VERSION "ae3c"

NS_ :

BS_:

BU_: Brightloop_Can_Loader ECU HVHV DCDC

BO_ 2147487814 BL3_Node6GlobalValue: 7 HVHV
 SG_ NCellOtpErrorFlags m0 : 48|8@1+ (1,0) [0|255] ""  ECU
 SG_ TCell3N2 m1 : 48|8@1+ (1,-40) [-40|215] "°C"  ECU
 SG_ VAuxCell4N2 m9 : 48|8@1+ (0.15,0) [0|38.25] "V"  ECU
 SG_ TCell3N1 m1 : 40|8@1+ (1,-40) [-40|215] "°C"  ECU
 SG_ TInternal m3 : 40|8@1+ (1,-40) [-40|215] "°C"  ECU
 SG_ NBootloaderId m4 : 40|16@1+ (1,0) [0|65535] ""  ECU
 SG_ NApplicationId m5 : 40|16@1+ (1,0) [0|65535] ""  ECU
 SG_ VAuxCell3N2 m9 : 40|8@1+ (0.15,0) [0|38.25] "V"  ECU
 SG_ NSyncNodeCount m0 : 39|5@1+ (1,0) [0|31] ""  ECU
 SG_ NSyncNodeRank m0 : 34|5@1+ (1,0) [0|31] ""  ECU
 SG_ NReleaseMode m0 : 32|2@1+ (1,0) [0|3] ""  ECU
 SG_ TCell2N2 m1 : 32|8@1+ (1,-40) [-40|215] "°C"  ECU
 SG_ NCellVAuxErrorFlags m7 : 32|8@1+ (1,0) [0|65535] ""  ECU
 SG_ VAuxCell4N1 m8 : 32|8@1+ (0.15,0) [0|38.25] "V"  ECU
 SG_ VAuxCell2N2 m9 : 32|8@1+ (0.15,0) [0|38.25] "V"  ECU
 SG_ VAuxCell4N3 m10 : 32|8@1+ (0.15,0) [0|38.25] "V"  ECU
 SG_ TCell4N3 m11 : 32|8@1+ (1,-40) [-40|215] "°C"  ECU
 SG_ VAux3Measured m0 : 24|8@1+ (0.01,0) [0|2.55] "V"  ECU
 SG_ TCell2N1 m1 : 24|8@1+ (1,-40) [-40|215] "°C"  ECU
 SG_ NConfigCrc m4 : 24|16@1+ (1,0) [0|65535] ""  ECU
 SG_ NSettingsCrc m5 : 24|16@1+ (1,0) [0|65535] ""  ECU
 SG_ NSerial m6 : 24|32@1+ (1,0) [0|4294967295] ""  ECU
 SG_ VAuxCell3N1 m8 : 24|8@1+ (0.15,0) [0|38.25] "V"  ECU
 SG_ VAuxCell1N2 m9 : 24|8@1+ (0.15,0) [0|38.25] "V"  ECU
 SG_ VAuxCell3N3 m10 : 24|8@1+ (0.15,0) [0|38.25] "V"  ECU
 SG_ TCell3N3 m11 : 24|8@1+ (1,-40) [-40|215] "°C"  ECU
 SG_ VAux2Measured m0 : 16|8@1+ (0.02,0) [0|5.1] "V"  ECU
 SG_ TCell1N2 m1 : 16|8@1+ (1,-40) [-40|215] "°C"  ECU
 SG_ TCell4N2 m2 : 16|8@1+ (1,-40) [-40|215] "°C"  ECU
 SG_ NCellXcpErrorFlags m7 : 16|16@1+ (1,0) [0|65535] ""  ECU
 SG_ VAuxCell2N1 m8 : 16|8@1+ (0.15,0) [0|38.25] "V"  ECU
 SG_ VAuxCell2N3 m10 : 16|8@1+ (0.15,0) [0|38.25] "V"  ECU
 SG_ TCell2N3 m11 : 16|8@1+ (1,-40) [-40|215] "°C"  ECU
 SG_ VAux1Measured m0 : 8|8@1+ (0.15,0) [0|38.25] "V"  ECU
 SG_ TCell1N1 m1 : 8|8@1+ (1,-40) [-40|215] "°C"  ECU
 SG_ TCell4N1 m2 : 8|8@1+ (1,-40) [-40|215] "°C"  ECU
 SG_ NConfigVersion m4 : 8|16@1+ (1,0) [0|65535] ""  ECU
 SG_ NSettingsVersion m5 : 8|16@1+ (1,0) [0|65535] ""  ECU
 SG_ NChecksum m6 : 8|16@1+ (1,0) [0|65535] ""  ECU
 SG_ NCellSwOcpErrorFlags m7 : 8|8@1+ (1,0) [0|255] ""  ECU
 SG_ VAuxCell1N1 m8 : 8|8@1+ (0.15,0) [0|38.25] "V"  ECU
 SG_ VAuxCell1N3 m10 : 8|8@1+ (0.15,0) [0|38.25] "V"  ECU
 SG_ TCell1N3 m11 : 8|8@1+ (1,-40) [-40|215] "°C"  ECU
 SG_ NMultiplexer M : 0|8@1+ (1,0) [0|255] ""  ECU

BO_ 2147487750 BL3_Node6Status: 8 HVHV
 SG_ BPath1AcModeActivated m0 : 63|1@1+ (1,0) [0|1] ""  ECU
 SG_ BPath1AcUfpError m0 : 62|1@1+ (1,0) [0|1] ""  ECU
 SG_ BPath1AcOfpError m0 : 61|1@1+ (1,0) [0|1] ""  ECU
 SG_ NPath1AcFunctionMode m0 : 58|3@1+ (1,0) [0|7] ""  ECU
 SG_ BPath1FlgCapaError m0 : 57|1@1+ (1,0) [0|1] ""  ECU
 SG_ BPath2FlgCapaError m1 : 57|1@1+ (1,0) [0|1] ""  ECU
 SG_ BPath1ErrVAuxCell m0 : 56|1@1+ (1,0) [0|1] ""  ECU
 SG_ BPath2ErrVAuxCell m1 : 56|1@1+ (1,0) [0|1] ""  ECU
 SG_ IPath1Unbalance m0 : 48|8@1+ (0.25,0) [0|63.75] "A"  ECU
 SG_ IPath2Unbalance m1 : 48|8@1+ (0.25,0) [0|63.75] "A"  ECU
 SG_ BPath1RcpWarning m0 : 47|1@1+ (1,0) [0|1] ""  ECU
 SG_ BPath2RcpWarning m1 : 47|1@1+ (1,0) [0|1] ""  ECU
 SG_ BPath1OcpError m0 : 46|1@1+ (1,0) [0|1] ""  ECU
 SG_ BPath2OcpError m1 : 46|1@1+ (1,0) [0|1] ""  ECU
 SG_ BPath1OtpError m0 : 45|1@1+ (1,0) [0|1] ""  ECU
 SG_ BPath2OtpError m1 : 45|1@1+ (1,0) [0|1] ""  ECU
 SG_ BPath1SideBUvpError m0 : 44|1@1+ (1,0) [0|1] ""  ECU
 SG_ BPath2SideBUvpError m1 : 44|1@1+ (1,0) [0|1] ""  ECU
 SG_ BPath1SideAUvpError m0 : 43|1@1+ (1,0) [0|1] ""  ECU
 SG_ BPath2SideAUvpError m1 : 43|1@1+ (1,0) [0|1] ""  ECU
 SG_ BPath1SideBOvpError m0 : 42|1@1+ (1,0) [0|1] ""  ECU
 SG_ BPath2SideBOvpError m1 : 42|1@1+ (1,0) [0|1] ""  ECU
 SG_ BPath1SideAOvpError m0 : 41|1@1+ (1,0) [0|1] ""  ECU
 SG_ BPath2SideAOvpError m1 : 41|1@1+ (1,0) [0|1] ""  ECU
 SG_ BPath1Requested m0 : 40|1@1+ (1,0) [0|1] ""  ECU
 SG_ BPath2Requested m1 : 40|1@1+ (1,0) [0|1] ""  ECU
 SG_ NPath1CurrentSideSelected m0 : 38|2@1+ (1,0) [0|3] ""  ECU
 SG_ NPath2CurrentSideSelected m1 : 38|2@1+ (1,0) [0|3] ""  ECU
 SG_ NPath1VoltageSideSelected m0 : 36|2@1+ (1,0) [0|3] ""  ECU
 SG_ NPath2VoltageSideSelected m1 : 36|2@1+ (1,0) [0|3] ""  ECU
 SG_ NPath1State m0 : 32|4@1+ (1,0) [0|15] ""  ECU
 SG_ NPath2State m1 : 32|4@1+ (1,0) [0|15] ""  ECU
 SG_ NMultiplexer M : 29|3@1+ (1,0) [0|7] ""  ECU
 SG_ BXcpError : 28|1@1+ (1,0) [0|1] ""  ECU
 SG_ NCellHwErrorFlags : 20|8@1+ (1,0) [0|255] ""  ECU
 SG_ BSyncInputSignal : 18|1@1+ (1,0) [0|0] ""  ECU
 SG_ BSyncRequested : 17|1@1+ (1,0) [0|0] ""  ECU
 SG_ BInternalTemperatureError : 16|1@1+ (1,0) [0|1] ""  ECU
 SG_ BConfigSettingsError : 15|1@1+ (1,0) [0|1] ""  ECU
 SG_ BAuxSupplyError : 14|1@1+ (1,0) [0|1] ""  ECU
 SG_ BCanTimeoutError : 13|1@1+ (1,0) [0|1] ""  ECU
 SG_ BAuxIsoEnabled : 12|1@1+ (1,0) [0|1] ""  ECU
 SG_ BSafetyDischargeEnabled : 11|1@1+ (1,0) [0|1] ""  ECU
 SG_ BFaultSignal : 10|1@1+ (1,0) [0|1] ""  ECU
 SG_ BEnableSignal : 9|1@1+ (1,0) [0|1] ""  ECU
 SG_ BSafetyDischargeStatus : 8|1@1+ (1,0) [0|1] ""  ECU
 SG_ BSyncStatus : 7|1@1+ (1,0) [0|1] ""  ECU
 SG_ BReadConfigAndSettingsRequested : 6|1@1+ (1,0) [0|1] ""  ECU
 SG_ BSwResetModuleRequested : 5|1@1+ (1,0) [0|1] ""  ECU
 SG_ BSafetyDischargeRequested : 4|1@1+ (1,0) [0|1] ""  ECU
 SG_ NModuleState : 0|4@1+ (1,0) [0|15] ""  ECU

BO_ 2147487753 BL4_Node9Status: 8 HVHV
 SG_ BPath1AcModeActivated m0 : 63|1@1+ (1,0) [0|1] ""  ECU
 SG_ BPath1AcUfpError m0 : 62|1@1+ (1,0) [0|1] ""  ECU
 SG_ BPath1AcOfpError m0 : 61|1@1+ (1,0) [0|1] ""  ECU
 SG_ NPath1AcFunctionMode m0 : 58|3@1+ (1,0) [0|7] ""  ECU
 SG_ BPath1FlgCapaError m0 : 57|1@1+ (1,0) [0|1] ""  ECU
 SG_ BPath2FlgCapaError m1 : 57|1@1+ (1,0) [0|1] ""  ECU
 SG_ BPath1ErrVAuxCell m0 : 56|1@1+ (1,0) [0|1] ""  ECU
 SG_ BPath2ErrVAuxCell m1 : 56|1@1+ (1,0) [0|1] ""  ECU
 SG_ IPath1Unbalance m0 : 48|8@1+ (0.25,0) [0|63.75] "A"  ECU
 SG_ IPath2Unbalance m1 : 48|8@1+ (0.25,0) [0|63.75] "A"  ECU
 SG_ BPath1RcpWarning m0 : 47|1@1+ (1,0) [0|1] ""  ECU
 SG_ BPath2RcpWarning m1 : 47|1@1+ (1,0) [0|1] ""  ECU
 SG_ BPath1OcpError m0 : 46|1@1+ (1,0) [0|1] ""  ECU
 SG_ BPath2OcpError m1 : 46|1@1+ (1,0) [0|1] ""  ECU
 SG_ BPath1OtpError m0 : 45|1@1+ (1,0) [0|1] ""  ECU
 SG_ BPath2OtpError m1 : 45|1@1+ (1,0) [0|1] ""  ECU
 SG_ BPath1SideBUvpError m0 : 44|1@1+ (1,0) [0|1] ""  ECU
 SG_ BPath2SideBUvpError m1 : 44|1@1+ (1,0) [0|1] ""  ECU
 SG_ BPath1SideAUvpError m0 : 43|1@1+ (1,0) [0|1] ""  ECU
 SG_ BPath2SideAUvpError m1 : 43|1@1+ (1,0) [0|1] ""  ECU
 SG_ BPath1SideBOvpError m0 : 42|1@1+ (1,0) [0|1] ""  ECU
 SG_ BPath2SideBOvpError m1 : 42|1@1+ (1,0) [0|1] ""  ECU
 SG_ BPath1SideAOvpError m0 : 41|1@1+ (1,0) [0|1] ""  ECU
 SG_ BPath2SideAOvpError m1 : 41|1@1+ (1,0) [0|1] ""  ECU
 SG_ BPath1Requested m0 : 40|1@1+ (1,0) [0|1] ""  ECU
 SG_ BPath2Requested m1 : 40|1@1+ (1,0) [0|1] ""  ECU
 SG_ NPath1CurrentSideSelected m0 : 38|2@1+ (1,0) [0|3] ""  ECU
 SG_ NPath2CurrentSideSelected m1 : 38|2@1+ (1,0) [0|3] ""  ECU
 SG_ NPath1VoltageSideSelected m0 : 36|2@1+ (1,0) [0|3] ""  ECU
 SG_ NPath2VoltageSideSelected m1 : 36|2@1+ (1,0) [0|3] ""  ECU
 SG_ NPath1State m0 : 32|4@1+ (1,0) [0|15] ""  ECU
 SG_ NPath2State m1 : 32|4@1+ (1,0) [0|15] ""  ECU
 SG_ NMultiplexer M : 29|3@1+ (1,0) [0|7] ""  ECU
 SG_ BXcpError : 28|1@1+ (1,0) [0|1] ""  ECU
 SG_ NCellHwErrorFlags : 20|8@1+ (1,0) [0|255] ""  ECU
 SG_ BSyncInputSignal : 18|1@1+ (1,0) [0|0] ""  ECU
 SG_ BSyncRequested : 17|1@1+ (1,0) [0|0] ""  ECU
 SG_ BInternalTemperatureError : 16|1@1+ (1,0) [0|1] ""  ECU
 SG_ BConfigSettingsError : 15|1@1+ (1,0) [0|1] ""  ECU
 SG_ BAuxSupplyError : 14|1@1+ (1,0) [0|1] ""  ECU
 SG_ BCanTimeoutError : 13|1@1+ (1,0) [0|1] ""  ECU
 SG_ BAuxIsoEnabled : 12|1@1+ (1,0) [0|1] ""  ECU
 SG_ BSafetyDischargeEnabled : 11|1@1+ (1,0) [0|1] ""  ECU
 SG_ BFaultSignal : 10|1@1+ (1,0) [0|1] ""  ECU
 SG_ BEnableSignal : 9|1@1+ (1,0) [0|1] ""  ECU
 SG_ BSafetyDischargeStatus : 8|1@1+ (1,0) [0|1] ""  ECU
 SG_ BSyncStatus : 7|1@1+ (1,0) [0|1] ""  ECU
 SG_ BReadConfigAndSettingsRequested : 6|1@1+ (1,0) [0|1] ""  ECU
 SG_ BSwResetModuleRequested : 5|1@1+ (1,0) [0|1] ""  ECU
 SG_ BSafetyDischargeRequested : 4|1@1+ (1,0) [0|1] ""  ECU
 SG_ NModuleState : 0|4@1+ (1,0) [0|15] ""  ECU

BO_ 2147489417 BL4_Node9Setpoints2Value: 6 HVHV
 SG_ IqPath1AcLimitLo m9 : 38|10@1+ (0.5,-256) [-256|255.5] "A"  ECU
 SG_ IqPath1AcLimitHi m9 : 28|10@1+ (0.5,-256) [-256|255.5] "A"  ECU
 SG_ PPath2LimitLo m2 : 24|16@1+ (100,-3000000) [-3000000|3553500] "W"  ECU
 SG_ IqPath1AcSetpoint m13 : 18|10@1+ (0.5,-256) [-256|255.5] "A"  ECU
 SG_ IdPath1AcLimitLo m9 : 18|10@1+ (0.5,-256) [-256|255.5] "A"  ECU
 SG_ IdPath1AcSetpoint m13 : 8|10@1+ (0.5,-256) [-256|255.5] "A"  ECU
 SG_ IdPath1AcLimitHi m9 : 8|10@1+ (0.5,-256) [-256|255.5] "A"  ECU
 SG_ PPath2LimitHi m2 : 8|16@1+ (100,-3000000) [-3000000|3553500] "W"  ECU
 SG_ NMultiplexer M : 0|5@1+ (1,0) [0|31] ""  ECU

BO_ 2147489353 BL4_Node9Setpoints1Value: 7 HVHV
 SG_ NPath1AcFunctionMode m9 : 50|3@1+ (1,0) [0|7] ""  ECU
 SG_ NPath2CurrentSideSelected m2 : 42|2@1+ (1,0) [0|3] ""  ECU
 SG_ NPath2VoltageSideSelected m2 : 40|2@1+ (1,0) [0|3] ""  ECU
 SG_ NPath1AcFrequencySetpoint m9 : 38|12@1+ (0.25,0) [0|1023.75] "Hz"  ECU
 SG_ IPath2LimitLo m2 : 28|12@1+ (0.5,-1000) [-1000|1047.5] "A"  ECU
 SG_ VqPath1AcSetpoint m9 : 27|11@1+ (1,-1024) [-1024|1023] "V"  ECU
 SG_ VdPath1AcSetpoint m9 : 16|11@1+ (1,-1024) [-1024|1023] "V"  ECU
 SG_ IPath2LimitHi m2 : 16|12@1+ (0.5,-1000) [-1000|1047.5] "A"  ECU
 SG_ VDcPath1AcSetpoint m9 : 4|12@1+ (1,0) [0|4095] "V"  ECU
 SG_ VPath2Setpoint m2 : 4|12@1+ (1,0) [0|4095] "V"  ECU
 SG_ NMultiplexer M : 0|4@1+ (1,0) [0|15] ""  ECU

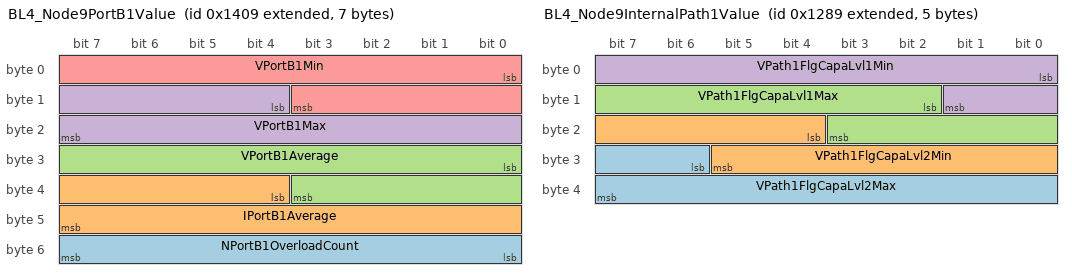
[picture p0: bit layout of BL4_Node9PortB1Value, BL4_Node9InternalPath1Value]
BO_ 2147488777 BL4_Node9PortB1Value: 7 HVHV
 SG_ NPortB1OverloadCount : 48|8@1+ (1,0) [0|255] ""  ECU
 SG_ IPortB1Average : 36|12@1+ (0.25,-500) [-500|523.75] "A"  ECU
 SG_ VPortB1Average : 24|12@1+ (1,0) [0|4095] "V"  ECU
 SG_ VPortB1Max : 12|12@1+ (1,0) [0|4095] "V"  ECU
 SG_ VPortB1Min : 0|12@1+ (1,0) [0|4095] "V"  ECU

BO_ 2147487881 BL4_Node9PortA1Value: 8 HVHV
 SG_ NMultiplexer M : 56|8@1+ (1,0) [0|255] ""  ECU
 SG_ IqPhAPortA1RMS m3 : 42|12@1+ (0.125,-256) [-256|255.875] "A"  ECU
 SG_ IqPortA1RMS m1 : 36|12@1+ (0.125,-256) [-256|255.875] "A"  ECU
 SG_ NFrequencyPortA1 m2 : 36|16@1+ (0.0125,0) [0|819.1875] "Hz"  ECU
 SG_ IqPhCPortA1RMS m4 : 36|12@1+ (0.125,-256) [-256|255.875] "A"  ECU
 SG_ IdPhAPortA1RMS m3 : 30|12@1+ (0.125,-256) [-256|255.875] "A"  ECU
 SG_ IdPortA1RMS m1 : 24|12@1+ (0.125,-256) [-256|255.875] "A"  ECU
 SG_ VphCPortA1Peak m2 : 24|12@1+ (0.5,0) [0|2047.5] "V"  ECU
 SG_ IdPhCPortA1RMS m4 : 24|12@1+ (0.125,-256) [-256|255.875] "A"  ECU
 SG_ IphCPortA1Peak m3 : 20|10@1+ (0.25,0) [0|255.75] "A"  ECU
 SG_ VqPortA1RMS m1 : 12|12@1+ (0.5,-1024) [-1024|1023.5] "V"  ECU
 SG_ VphBPortA1Peak m2 : 12|12@1+ (0.5,0) [0|2047.5] "V"  ECU
 SG_ IqPhBPortA1RMS m4 : 12|12@1+ (0.125,-256) [-256|255.875] "A"  ECU
 SG_ IphBPortA1Peak m3 : 10|10@1+ (0.25,0) [0|255.75] "A"  ECU
 SG_ VdPortA1RMS m1 : 0|12@1+ (0.5,-1024) [-1024|1023.5] "V"  ECU
 SG_ VphAPortA1Peak m2 : 0|12@1+ (0.5,0) [0|2047.5] "V"  ECU
 SG_ IphAPortA1Peak m3 : 0|10@1+ (0.25,0) [0|255.75] "A"  ECU
 SG_ IdPhBPortA1RMS m4 : 0|12@1+ (0.125,-256) [-256|255.875] "A"  ECU

BO_ 2147487945 BL4_Node9PortA2Value: 8 HVHV
 SG_ NMultiplexer M : 56|8@1+ (1,0) [0|255] ""  ECU
 SG_ NPortA2OverloadCount m0 : 48|8@1+ (1,0) [0|255] ""  ECU
 SG_ IPortA2Average m0 : 36|12@1+ (0.25,-500) [-500|523.75] "A"  ECU
 SG_ VPortA2Average m0 : 24|12@1+ (1,0) [0|4095] "V"  ECU
 SG_ VPortA2Max m0 : 12|12@1+ (1,0) [0|4095] "V"  ECU
 SG_ VPortA2Min m0 : 0|12@1+ (1,0) [0|4095] "V"  ECU

BO_ 2147488393 BL4_Node9InternalPath1Value: 5 HVHV
 SG_ VPath1FlgCapaLvl2Max : 30|10@1+ (2,0) [0|2046] "V"  ECU
 SG_ VPath1FlgCapaLvl2Min : 20|10@1+ (2,0) [0|2046] "V"  ECU
 SG_ VPath1FlgCapaLvl1Max : 10|10@1+ (2,0) [0|2046] "V"  ECU
 SG_ VPath1FlgCapaLvl1Min : 0|10@1+ (2,0) [0|2046] "V"  ECU

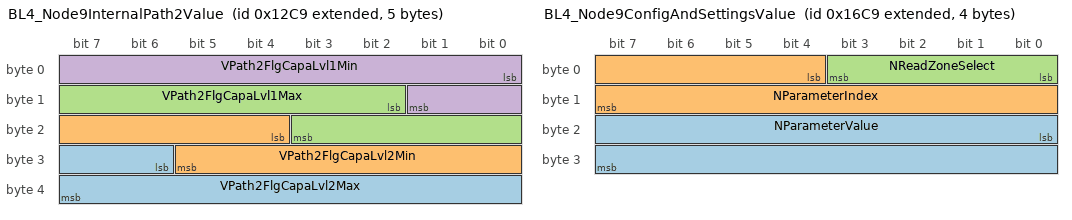
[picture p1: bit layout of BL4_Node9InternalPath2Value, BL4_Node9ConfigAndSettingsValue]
BO_ 2147488457 BL4_Node9InternalPath2Value: 5 HVHV
 SG_ VPath2FlgCapaLvl2Max : 30|10@1+ (2,0) [0|2046] "V"  ECU
 SG_ VPath2FlgCapaLvl2Min : 20|10@1+ (2,0) [0|2046] "V"  ECU
 SG_ VPath2FlgCapaLvl1Max : 10|10@1+ (2,0) [0|2046] "V"  ECU
 SG_ VPath2FlgCapaLvl1Min : 0|10@1+ (2,0) [0|2046] "V"  ECU

BO_ 2147487817 BL4_Node9GlobalValue: 7 HVHV
 SG_ NCellOtpErrorFlags m0 : 48|8@1+ (1,0) [0|255] ""  ECU
 SG_ TCell3N2 m1 : 48|8@1+ (1,-40) [-40|215] "°C"  ECU
 SG_ VAuxCell4N2 m9 : 48|8@1+ (0.15,0) [0|38.25] "V"  ECU
 SG_ TCell3N1 m1 : 40|8@1+ (1,-40) [-40|215] "°C"  ECU
 SG_ TInternal m3 : 40|8@1+ (1,-40) [-40|215] "°C"  ECU
 SG_ NBootloaderId m4 : 40|16@1+ (1,0) [0|65535] ""  ECU
 SG_ NApplicationId m5 : 40|16@1+ (1,0) [0|65535] ""  ECU
 SG_ VAuxCell3N2 m9 : 40|8@1+ (0.15,0) [0|38.25] "V"  ECU
 SG_ NSyncNodeCount m0 : 39|5@1+ (1,0) [0|31] ""  ECU
 SG_ NSyncNodeRank m0 : 34|5@1+ (1,0) [0|31] ""  ECU
 SG_ NReleaseMode m0 : 32|2@1+ (1,0) [0|3] ""  ECU
 SG_ TCell2N2 m1 : 32|8@1+ (1,-40) [-40|215] "°C"  ECU
 SG_ NCellVAuxErrorFlags m7 : 32|8@1+ (1,0) [0|65535] ""  ECU
 SG_ VAuxCell4N1 m8 : 32|8@1+ (0.15,0) [0|38.25] "V"  ECU
 SG_ VAuxCell2N2 m9 : 32|8@1+ (0.15,0) [0|38.25] "V"  ECU
 SG_ VAuxCell4N3 m10 : 32|8@1+ (0.15,0) [0|38.25] "V"  ECU
 SG_ TCell4N3 m11 : 32|8@1+ (1,-40) [-40|215] "°C"  ECU
 SG_ VAux3Measured m0 : 24|8@1+ (0.01,0) [0|2.55] "V"  ECU
 SG_ TCell2N1 m1 : 24|8@1+ (1,-40) [-40|215] "°C"  ECU
 SG_ NConfigCrc m4 : 24|16@1+ (1,0) [0|65535] ""  ECU
 SG_ NSettingsCrc m5 : 24|16@1+ (1,0) [0|65535] ""  ECU
 SG_ NSerial m6 : 24|32@1+ (1,0) [0|4294967295] ""  ECU
 SG_ VAuxCell3N1 m8 : 24|8@1+ (0.15,0) [0|38.25] "V"  ECU
 SG_ VAuxCell1N2 m9 : 24|8@1+ (0.15,0) [0|38.25] "V"  ECU
 SG_ VAuxCell3N3 m10 : 24|8@1+ (0.15,0) [0|38.25] "V"  ECU
 SG_ TCell3N3 m11 : 24|8@1+ (1,-40) [-40|215] "°C"  ECU
 SG_ VAux2Measured m0 : 16|8@1+ (0.02,0) [0|5.1] "V"  ECU
 SG_ TCell1N2 m1 : 16|8@1+ (1,-40) [-40|215] "°C"  ECU
 SG_ TCell4N2 m2 : 16|8@1+ (1,-40) [-40|215] "°C"  ECU
 SG_ NCellXcpErrorFlags m7 : 16|16@1+ (1,0) [0|65535] ""  ECU
 SG_ VAuxCell2N1 m8 : 16|8@1+ (0.15,0) [0|38.25] "V"  ECU
 SG_ VAuxCell2N3 m10 : 16|8@1+ (0.15,0) [0|38.25] "V"  ECU
 SG_ TCell2N3 m11 : 16|8@1+ (1,-40) [-40|215] "°C"  ECU
 SG_ VAux1Measured m0 : 8|8@1+ (0.15,0) [0|38.25] "V"  ECU
 SG_ TCell1N1 m1 : 8|8@1+ (1,-40) [-40|215] "°C"  ECU
 SG_ TCell4N1 m2 : 8|8@1+ (1,-40) [-40|215] "°C"  ECU
 SG_ NConfigVersion m4 : 8|16@1+ (1,0) [0|65535] ""  ECU
 SG_ NSettingsVersion m5 : 8|16@1+ (1,0) [0|65535] ""  ECU
 SG_ NChecksum m6 : 8|16@1+ (1,0) [0|65535] ""  ECU
 SG_ NCellSwOcpErrorFlags m7 : 8|8@1+ (1,0) [0|255] ""  ECU
 SG_ VAuxCell1N1 m8 : 8|8@1+ (0.15,0) [0|38.25] "V"  ECU
 SG_ VAuxCell1N3 m10 : 8|8@1+ (0.15,0) [0|38.25] "V"  ECU
 SG_ TCell1N3 m11 : 8|8@1+ (1,-40) [-40|215] "°C"  ECU
 SG_ NMultiplexer M : 0|8@1+ (1,0) [0|255] ""  ECU

BO_ 2147489481 BL4_Node9ConfigAndSettingsValue: 4 HVHV
 SG_ NParameterValue : 16|16@1+ (1,0) [0|0] ""  ECU
 SG_ NParameterIndex : 4|12@1+ (1,0) [0|0] ""  ECU
 SG_ NReadZoneSelect : 0|4@1+ (1,0) [0|0] ""  ECU

BO_ 2147489416 BL4_Node8Setpoints2Value: 6 HVHV
 SG_ IqPath1AcLimitLo m9 : 38|10@1+ (0.5,-256) [-256|255.5] "A"  ECU
 SG_ IqPath1AcLimitHi m9 : 28|10@1+ (0.5,-256) [-256|255.5] "A"  ECU
 SG_ PPath2LimitLo m2 : 24|16@1+ (100,-3000000) [-3000000|3553500] "W"  ECU
 SG_ IqPath1AcSetpoint m13 : 18|10@1+ (0.5,-256) [-256|255.5] "A"  ECU
 SG_ IdPath1AcLimitLo m9 : 18|10@1+ (0.5,-256) [-256|255.5] "A"  ECU
 SG_ IdPath1AcSetpoint m13 : 8|10@1+ (0.5,-256) [-256|255.5] "A"  ECU
 SG_ IdPath1AcLimitHi m9 : 8|10@1+ (0.5,-256) [-256|255.5] "A"  ECU
 SG_ PPath2LimitHi m2 : 8|16@1+ (100,-3000000) [-3000000|3553500] "W"  ECU
 SG_ NMultiplexer M : 0|5@1+ (1,0) [0|31] ""  ECU

BO_ 2147489352 BL4_Node8Setpoints1Value: 7 HVHV
 SG_ NPath1AcFunctionMode m9 : 50|3@1+ (1,0) [0|7] ""  ECU
 SG_ NPath2CurrentSideSelected m2 : 42|2@1+ (1,0) [0|3] ""  ECU
 SG_ NPath2VoltageSideSelected m2 : 40|2@1+ (1,0) [0|3] ""  ECU
 SG_ NPath1AcFrequencySetpoint m9 : 38|12@1+ (0.25,0) [0|1023.75] "Hz"  ECU
 SG_ IPath2LimitLo m2 : 28|12@1+ (0.5,-1000) [-1000|1047.5] "A"  ECU
 SG_ VqPath1AcSetpoint m9 : 27|11@1+ (1,-1024) [-1024|1023] "V"  ECU
 SG_ VdPath1AcSetpoint m9 : 16|11@1+ (1,-1024) [-1024|1023] "V"  ECU
 SG_ IPath2LimitHi m2 : 16|12@1+ (0.5,-1000) [-1000|1047.5] "A"  ECU
 SG_ VDcPath1AcSetpoint m9 : 4|12@1+ (1,0) [0|4095] "V"  ECU
 SG_ VPath2Setpoint m2 : 4|12@1+ (1,0) [0|4095] "V"  ECU
 SG_ NMultiplexer M : 0|4@1+ (1,0) [0|15] ""  ECU

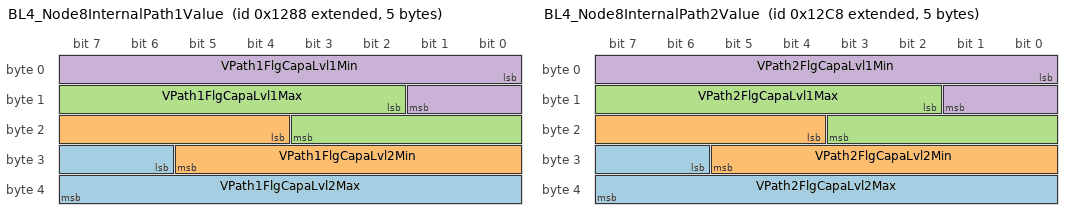
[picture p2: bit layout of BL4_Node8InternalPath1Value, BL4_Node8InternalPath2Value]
BO_ 2147488392 BL4_Node8InternalPath1Value: 5 HVHV
 SG_ VPath1FlgCapaLvl2Max : 30|10@1+ (2,0) [0|2046] "V"  ECU
 SG_ VPath1FlgCapaLvl2Min : 20|10@1+ (2,0) [0|2046] "V"  ECU
 SG_ VPath1FlgCapaLvl1Max : 10|10@1+ (2,0) [0|2046] "V"  ECU
 SG_ VPath1FlgCapaLvl1Min : 0|10@1+ (2,0) [0|2046] "V"  ECU

BO_ 2147488456 BL4_Node8InternalPath2Value: 5 HVHV
 SG_ VPath2FlgCapaLvl2Max : 30|10@1+ (2,0) [0|2046] "V"  ECU
 SG_ VPath2FlgCapaLvl2Min : 20|10@1+ (2,0) [0|2046] "V"  ECU
 SG_ VPath2FlgCapaLvl1Max : 10|10@1+ (2,0) [0|2046] "V"  ECU
 SG_ VPath2FlgCapaLvl1Min : 0|10@1+ (2,0) [0|2046] "V"  ECU

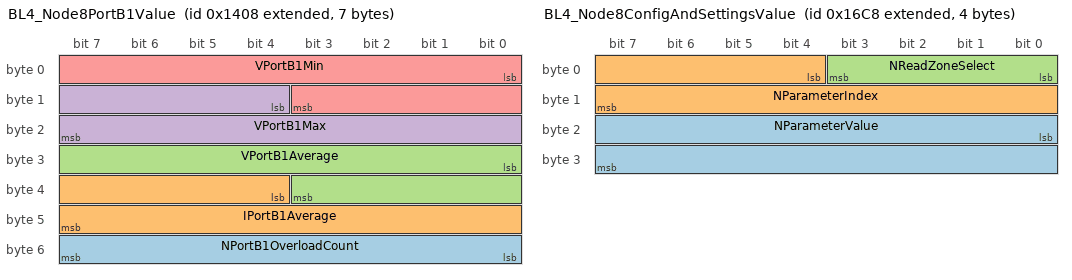
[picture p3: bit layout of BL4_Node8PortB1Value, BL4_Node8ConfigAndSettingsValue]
BO_ 2147488776 BL4_Node8PortB1Value: 7 HVHV
 SG_ NPortB1OverloadCount : 48|8@1+ (1,0) [0|255] ""  ECU
 SG_ IPortB1Average : 36|12@1+ (0.25,-500) [-500|523.75] "A"  ECU
 SG_ VPortB1Average : 24|12@1+ (1,0) [0|4095] "V"  ECU
 SG_ VPortB1Max : 12|12@1+ (1,0) [0|4095] "V"  ECU
 SG_ VPortB1Min : 0|12@1+ (1,0) [0|4095] "V"  ECU

BO_ 2147487880 BL4_Node8PortA1Value: 8 HVHV
 SG_ NMultiplexer M : 56|8@1+ (1,0) [0|255] ""  ECU
 SG_ IqPhAPortA1RMS m3 : 42|12@1+ (0.125,-256) [-256|255.875] "A"  ECU
 SG_ IqPortA1RMS m1 : 36|12@1+ (0.125,-256) [-256|255.875] "A"  ECU
 SG_ NFrequencyPortA1 m2 : 36|16@1+ (0.0125,0) [0|819.1875] "Hz"  ECU
 SG_ IqPhCPortA1RMS m4 : 36|12@1+ (0.125,-256) [-256|255.875] "A"  ECU
 SG_ IdPhAPortA1RMS m3 : 30|12@1+ (0.125,-256) [-256|255.875] "A"  ECU
 SG_ IdPortA1RMS m1 : 24|12@1+ (0.125,-256) [-256|255.875] "A"  ECU
 SG_ VphCPortA1Peak m2 : 24|12@1+ (0.5,0) [0|2047.5] "V"  ECU
 SG_ IdPhCPortA1RMS m4 : 24|12@1+ (0.125,-256) [-256|255.875] "A"  ECU
 SG_ IphCPortA1Peak m3 : 20|10@1+ (0.25,0) [0|255.75] "A"  ECU
 SG_ VqPortA1RMS m1 : 12|12@1+ (0.5,-1024) [-1024|1023.5] "V"  ECU
 SG_ VphBPortA1Peak m2 : 12|12@1+ (0.5,0) [0|2047.5] "V"  ECU
 SG_ IqPhBPortA1RMS m4 : 12|12@1+ (0.125,-256) [-256|255.875] "A"  ECU
 SG_ IphBPortA1Peak m3 : 10|10@1+ (0.25,0) [0|255.75] "A"  ECU
 SG_ VdPortA1RMS m1 : 0|12@1+ (0.5,-1024) [-1024|1023.5] "V"  ECU
 SG_ VphAPortA1Peak m2 : 0|12@1+ (0.5,0) [0|2047.5] "V"  ECU
 SG_ IphAPortA1Peak m3 : 0|10@1+ (0.25,0) [0|255.75] "A"  ECU
 SG_ IdPhBPortA1RMS m4 : 0|12@1+ (0.125,-256) [-256|255.875] "A"  ECU

BO_ 2147487944 BL4_Node8PortA2Value: 8 HVHV
 SG_ NMultiplexer M : 56|8@1+ (1,0) [0|255] ""  ECU
 SG_ NPortA2OverloadCount m0 : 48|8@1+ (1,0) [0|255] ""  ECU
 SG_ IPortA2Average m0 : 36|12@1+ (0.25,-500) [-500|523.75] "A"  ECU
 SG_ VPortA2Average m0 : 24|12@1+ (1,0) [0|4095] "V"  ECU
 SG_ VPortA2Max m0 : 12|12@1+ (1,0) [0|4095] "V"  ECU
 SG_ VPortA2Min m0 : 0|12@1+ (1,0) [0|4095] "V"  ECU

BO_ 2147489480 BL4_Node8ConfigAndSettingsValue: 4 HVHV
 SG_ NParameterValue : 16|16@1+ (1,0) [0|0] ""  ECU
 SG_ NParameterIndex : 4|12@1+ (1,0) [0|0] ""  ECU
 SG_ NReadZoneSelect : 0|4@1+ (1,0) [0|0] ""  ECU

BO_ 2147487816 BL4_Node8GlobalValue: 7 HVHV
 SG_ NCellOtpErrorFlags m0 : 48|8@1+ (1,0) [0|255] ""  ECU
 SG_ TCell3N2 m1 : 48|8@1+ (1,-40) [-40|215] "°C"  ECU
 SG_ VAuxCell4N2 m9 : 48|8@1+ (0.15,0) [0|38.25] "V"  ECU
 SG_ TCell3N1 m1 : 40|8@1+ (1,-40) [-40|215] "°C"  ECU
 SG_ TInternal m3 : 40|8@1+ (1,-40) [-40|215] "°C"  ECU
 SG_ NBootloaderId m4 : 40|16@1+ (1,0) [0|65535] ""  ECU
 SG_ NApplicationId m5 : 40|16@1+ (1,0) [0|65535] ""  ECU
 SG_ VAuxCell3N2 m9 : 40|8@1+ (0.15,0) [0|38.25] "V"  ECU
 SG_ NSyncNodeCount m0 : 39|5@1+ (1,0) [0|31] ""  ECU
 SG_ NSyncNodeRank m0 : 34|5@1+ (1,0) [0|31] ""  ECU
 SG_ NReleaseMode m0 : 32|2@1+ (1,0) [0|3] ""  ECU
 SG_ TCell2N2 m1 : 32|8@1+ (1,-40) [-40|215] "°C"  ECU
 SG_ NCellVAuxErrorFlags m7 : 32|8@1+ (1,0) [0|65535] ""  ECU
 SG_ VAuxCell4N1 m8 : 32|8@1+ (0.15,0) [0|38.25] "V"  ECU
 SG_ VAuxCell2N2 m9 : 32|8@1+ (0.15,0) [0|38.25] "V"  ECU
 SG_ VAuxCell4N3 m10 : 32|8@1+ (0.15,0) [0|38.25] "V"  ECU
 SG_ TCell4N3 m11 : 32|8@1+ (1,-40) [-40|215] "°C"  ECU
 SG_ VAux3Measured m0 : 24|8@1+ (0.01,0) [0|2.55] "V"  ECU
 SG_ TCell2N1 m1 : 24|8@1+ (1,-40) [-40|215] "°C"  ECU
 SG_ NConfigCrc m4 : 24|16@1+ (1,0) [0|65535] ""  ECU
 SG_ NSettingsCrc m5 : 24|16@1+ (1,0) [0|65535] ""  ECU
 SG_ NSerial m6 : 24|32@1+ (1,0) [0|4294967295] ""  ECU
 SG_ VAuxCell3N1 m8 : 24|8@1+ (0.15,0) [0|38.25] "V"  ECU
 SG_ VAuxCell1N2 m9 : 24|8@1+ (0.15,0) [0|38.25] "V"  ECU
 SG_ VAuxCell3N3 m10 : 24|8@1+ (0.15,0) [0|38.25] "V"  ECU
 SG_ TCell3N3 m11 : 24|8@1+ (1,-40) [-40|215] "°C"  ECU
 SG_ VAux2Measured m0 : 16|8@1+ (0.02,0) [0|5.1] "V"  ECU
 SG_ TCell1N2 m1 : 16|8@1+ (1,-40) [-40|215] "°C"  ECU
 SG_ TCell4N2 m2 : 16|8@1+ (1,-40) [-40|215] "°C"  ECU
 SG_ NCellXcpErrorFlags m7 : 16|16@1+ (1,0) [0|65535] ""  ECU
 SG_ VAuxCell2N1 m8 : 16|8@1+ (0.15,0) [0|38.25] "V"  ECU
 SG_ VAuxCell2N3 m10 : 16|8@1+ (0.15,0) [0|38.25] "V"  ECU
 SG_ TCell2N3 m11 : 16|8@1+ (1,-40) [-40|215] "°C"  ECU
 SG_ VAux1Measured m0 : 8|8@1+ (0.15,0) [0|38.25] "V"  ECU
 SG_ TCell1N1 m1 : 8|8@1+ (1,-40) [-40|215] "°C"  ECU
 SG_ TCell4N1 m2 : 8|8@1+ (1,-40) [-40|215] "°C"  ECU
 SG_ NConfigVersion m4 : 8|16@1+ (1,0) [0|65535] ""  ECU
 SG_ NSettingsVersion m5 : 8|16@1+ (1,0) [0|65535] ""  ECU
 SG_ NChecksum m6 : 8|16@1+ (1,0) [0|65535] ""  ECU
 SG_ NCellSwOcpErrorFlags m7 : 8|8@1+ (1,0) [0|255] ""  ECU
 SG_ VAuxCell1N1 m8 : 8|8@1+ (0.15,0) [0|38.25] "V"  ECU
 SG_ VAuxCell1N3 m10 : 8|8@1+ (0.15,0) [0|38.25] "V"  ECU
 SG_ TCell1N3 m11 : 8|8@1+ (1,-40) [-40|215] "°C"  ECU
 SG_ NMultiplexer M : 0|8@1+ (1,0) [0|255] ""  ECU

BO_ 2147487752 BL4_Node8Status: 8 HVHV
 SG_ BPath1AcModeActivated m0 : 63|1@1+ (1,0) [0|1] ""  ECU
 SG_ BPath1AcUfpError m0 : 62|1@1+ (1,0) [0|1] ""  ECU
 SG_ BPath1AcOfpError m0 : 61|1@1+ (1,0) [0|1] ""  ECU
 SG_ NPath1AcFunctionMode m0 : 58|3@1+ (1,0) [0|7] ""  ECU
 SG_ BPath1FlgCapaError m0 : 57|1@1+ (1,0) [0|1] ""  ECU
 SG_ BPath2FlgCapaError m1 : 57|1@1+ (1,0) [0|1] ""  ECU
 SG_ BPath1ErrVAuxCell m0 : 56|1@1+ (1,0) [0|1] ""  ECU
 SG_ BPath2ErrVAuxCell m1 : 56|1@1+ (1,0) [0|1] ""  ECU
 SG_ IPath1Unbalance m0 : 48|8@1+ (0.25,0) [0|63.75] "A"  ECU
 SG_ IPath2Unbalance m1 : 48|8@1+ (0.25,0) [0|63.75] "A"  ECU
 SG_ BPath1RcpWarning m0 : 47|1@1+ (1,0) [0|1] ""  ECU
 SG_ BPath2RcpWarning m1 : 47|1@1+ (1,0) [0|1] ""  ECU
 SG_ BPath1OcpError m0 : 46|1@1+ (1,0) [0|1] ""  ECU
 SG_ BPath2OcpError m1 : 46|1@1+ (1,0) [0|1] ""  ECU
 SG_ BPath1OtpError m0 : 45|1@1+ (1,0) [0|1] ""  ECU
 SG_ BPath2OtpError m1 : 45|1@1+ (1,0) [0|1] ""  ECU
 SG_ BPath1SideBUvpError m0 : 44|1@1+ (1,0) [0|1] ""  ECU
 SG_ BPath2SideBUvpError m1 : 44|1@1+ (1,0) [0|1] ""  ECU
 SG_ BPath1SideAUvpError m0 : 43|1@1+ (1,0) [0|1] ""  ECU
 SG_ BPath2SideAUvpError m1 : 43|1@1+ (1,0) [0|1] ""  ECU
 SG_ BPath1SideBOvpError m0 : 42|1@1+ (1,0) [0|1] ""  ECU
 SG_ BPath2SideBOvpError m1 : 42|1@1+ (1,0) [0|1] ""  ECU
 SG_ BPath1SideAOvpError m0 : 41|1@1+ (1,0) [0|1] ""  ECU
 SG_ BPath2SideAOvpError m1 : 41|1@1+ (1,0) [0|1] ""  ECU
 SG_ BPath1Requested m0 : 40|1@1+ (1,0) [0|1] ""  ECU
 SG_ BPath2Requested m1 : 40|1@1+ (1,0) [0|1] ""  ECU
 SG_ NPath1CurrentSideSelected m0 : 38|2@1+ (1,0) [0|3] ""  ECU
 SG_ NPath2CurrentSideSelected m1 : 38|2@1+ (1,0) [0|3] ""  ECU
 SG_ NPath1VoltageSideSelected m0 : 36|2@1+ (1,0) [0|3] ""  ECU
 SG_ NPath2VoltageSideSelected m1 : 36|2@1+ (1,0) [0|3] ""  ECU
 SG_ NPath1State m0 : 32|4@1+ (1,0) [0|15] ""  ECU
 SG_ NPath2State m1 : 32|4@1+ (1,0) [0|15] ""  ECU
 SG_ NMultiplexer M : 29|3@1+ (1,0) [0|7] ""  ECU
 SG_ BXcpError : 28|1@1+ (1,0) [0|1] ""  ECU
 SG_ NCellHwErrorFlags : 20|8@1+ (1,0) [0|255] ""  ECU
 SG_ BSyncInputSignal : 18|1@1+ (1,0) [0|0] ""  ECU
 SG_ BSyncRequested : 17|1@1+ (1,0) [0|0] ""  ECU
 SG_ BInternalTemperatureError : 16|1@1+ (1,0) [0|1] ""  ECU
 SG_ BConfigSettingsError : 15|1@1+ (1,0) [0|1] ""  ECU
 SG_ BAuxSupplyError : 14|1@1+ (1,0) [0|1] ""  ECU
 SG_ BCanTimeoutError : 13|1@1+ (1,0) [0|1] ""  ECU
 SG_ BAuxIsoEnabled : 12|1@1+ (1,0) [0|1] ""  ECU
 SG_ BSafetyDischargeEnabled : 11|1@1+ (1,0) [0|1] ""  ECU
 SG_ BFaultSignal : 10|1@1+ (1,0) [0|1] ""  ECU
 SG_ BEnableSignal : 9|1@1+ (1,0) [0|1] ""  ECU
 SG_ BSafetyDischargeStatus : 8|1@1+ (1,0) [0|1] ""  ECU
 SG_ BSyncStatus : 7|1@1+ (1,0) [0|1] ""  ECU
 SG_ BReadConfigAndSettingsRequested : 6|1@1+ (1,0) [0|1] ""  ECU
 SG_ BSwResetModuleRequested : 5|1@1+ (1,0) [0|1] ""  ECU
 SG_ BSafetyDischargeRequested : 4|1@1+ (1,0) [0|1] ""  ECU
 SG_ NModuleState : 0|4@1+ (1,0) [0|15] ""  ECU

BO_ 2147491393 BL5_Setpoints1Value: 7 DCDC
 SG_ NPath1CurrentSideSelected m1 : 42|2@1+ (1,0) [0|3] ""  ECU
 SG_ NPath1VoltageSideSelected m1 : 40|2@1+ (1,0) [0|3] ""  ECU
 SG_ IPath1LimitLo m1 : 28|12@1+ (0.5,-1000) [-1000|1047.5] "A"  ECU
 SG_ IPath1LimitHi m1 : 16|12@1+ (0.5,-1000) [-1000|1047.5] "A"  ECU
 SG_ VPath1Setpoint m1 : 4|12@1+ (1,0) [0|4095] "V"  ECU
 SG_ NMultiplexer M : 0|4@1+ (1,0) [0|15] ""  ECU

BO_ 2147491457 BL5_Setpoints2Value: 6 DCDC
 SG_ PPath1LimitLo m1 : 24|16@1+ (100,-3000000) [-3000000|3553500] "W"  ECU
 SG_ PPath1LimitHi m1 : 8|16@1+ (100,-3000000) [-3000000|3553500] "W"  ECU
 SG_ NMultiplexer M : 0|4@1+ (1,0) [0|15] ""  ECU

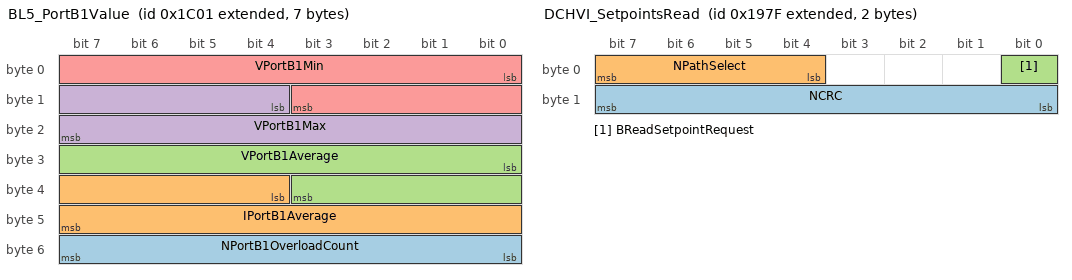
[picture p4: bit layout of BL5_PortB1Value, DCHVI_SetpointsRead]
BO_ 2147490817 BL5_PortB1Value: 7 DCDC
 SG_ NPortB1OverloadCount : 48|8@1+ (1,0) [0|255] ""  ECU
 SG_ IPortB1Average : 36|12@1+ (0.25,-500) [-500|523.75] "A"  ECU
 SG_ VPortB1Average : 24|12@1+ (1,0) [0|4095] "V"  ECU
 SG_ VPortB1Max : 12|12@1+ (1,0) [0|4095] "V"  ECU
 SG_ VPortB1Min : 0|12@1+ (1,0) [0|4095] "V"  ECU

BO_ 2147490175 DCHVI_SetpointsRead: 2 ECU
 SG_ NCRC : 8|8@1+ (1,0) [0|255] ""  DCDC
 SG_ NPathSelect : 4|4@1+ (1,0) [0|15] ""  DCDC
 SG_ BReadSetpointRequest : 0|1@1+ (1,0) [0|1] ""  DCDC

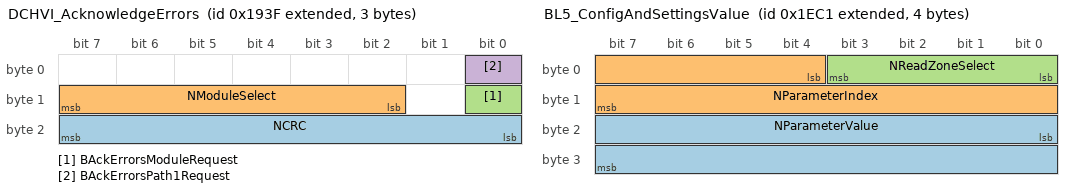
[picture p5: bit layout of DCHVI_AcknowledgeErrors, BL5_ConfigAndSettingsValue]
BO_ 2147490111 DCHVI_AcknowledgeErrors: 3 ECU
 SG_ NCRC : 16|8@1+ (1,0) [0|255] ""  DCDC
 SG_ NModuleSelect M : 10|6@1+ (1,0) [0|63] ""  DCDC
 SG_ BAckErrorsModuleRequest : 8|1@1+ (1,0) [0|1] ""  DCDC
 SG_ BAckErrorsPath1Request : 0|1@1+ (1,0) [0|1] ""  DCDC

BO_ 2147490047 DCHVI_Setpoints2Write: 7 ECU
 SG_ NCRC : 48|8@1+ (1,0) [0|255] ""  DCDC
 SG_ NModuleSelect M : 40|6@1+ (1,0) [0|63] ""  DCDC
 SG_ BL5_PPath1LimitLo m1 : 24|16@1+ (100,-3000000) [-3000000|3553500] "W"  DCDC
 SG_ BL6_PPath1LimitLo m1 : 24|16@1+ (100,-3000000) [-3000000|3553500] "W"  DCDC
 SG_ BL7_PPath1LimitLo m1 : 24|16@1+ (100,-3000000) [-3000000|3553500] "W"  DCDC
 SG_ BL5_PPath1LimitHi m1 : 8|16@1+ (100,-3000000) [-3000000|3553500] "W"  DCDC
 SG_ BL6_PPath1LimitHi m1 : 8|16@1+ (100,-3000000) [-3000000|3553500] "W"  DCDC
 SG_ BL7_PPath1LimitHi m1 : 8|16@1+ (100,-3000000) [-3000000|3553500] "W"  DCDC
 SG_ BL5_NMultiplexer m1M : 0|4@1+ (1,0) [0|15] ""  DCDC
 SG_ BL6_NMultiplexer m2M : 0|4@1+ (1,0) [0|15] ""  DCDC
 SG_ BL7_NMultiplexer m3M : 0|4@1+ (1,0) [0|15] ""  DCDC

BO_ 2147489921 BL5_PortA1Value: 8 DCDC
 SG_ NMultiplexer M : 56|8@1+ (1,0) [0|255] ""  ECU
 SG_ NPortA1OverloadCount m0 : 48|8@1+ (1,0) [0|255] ""  ECU
 SG_ IPortA1Average m0 : 36|12@1+ (0.25,-500) [-500|523.75] "A"  ECU
 SG_ VPortA1Average m0 : 24|12@1+ (1,0) [0|4095] "V"  ECU
 SG_ VPortA1Max m0 : 12|12@1+ (1,0) [0|4095] "V"  ECU
 SG_ VPortA1Min m0 : 0|12@1+ (1,0) [0|4095] "V"  ECU

BO_ 2147491521 BL5_ConfigAndSettingsValue: 4 DCDC
 SG_ NParameterValue : 16|16@1+ (1,0) [0|65535] ""  ECU
 SG_ NParameterIndex : 4|12@1+ (1,0) [0|4095] ""  ECU
 SG_ NReadZoneSelect : 0|4@1+ (1,0) [0|15] ""  ECU

BO_ 2147489857 BL5_GlobalValue: 8 DCDC
 SG_ BSetpointsApplied : 56|1@1+ (1,0) [0|1] ""  ECU
 SG_ VAuxCell6N1 m8 : 48|8@1+ (0.15,0) [0|38.25] "V"  ECU
 SG_ TCell6N2 m2 : 48|8@1+ (1,-40) [-40|215] "°C"  ECU
 SG_ TCell3N2 m1 : 48|8@1+ (1,-40) [-40|215] "°C"  ECU
 SG_ NCellOtpErrorFlags m0 : 48|8@1+ (1,0) [0|255] ""  ECU
 SG_ VAuxCell5N1 m8 : 40|8@1+ (0.15,0) [0|38.25] "V"  ECU
 SG_ NApplicationId m5 : 40|16@1+ (1,0) [0|65535] ""  ECU
 SG_ NBootloaderId m4 : 40|16@1+ (1,0) [0|65535] ""  ECU
 SG_ TInternal m3 : 40|8@1+ (1,-40) [-40|215] "°C"  ECU
 SG_ TCell6N1 m2 : 40|8@1+ (1,-40) [-40|215] "°C"  ECU
 SG_ TCell3N1 m1 : 40|8@1+ (1,-40) [-40|215] "°C"  ECU
 SG_ NSyncNodeCount m0 : 39|5@1+ (1,0) [0|31] ""  ECU
 SG_ NSyncNodeRank m0 : 34|5@1+ (1,0) [0|31] ""  ECU
 SG_ VAuxCell4N1 m8 : 32|8@1+ (0.15,0) [0|38.25] "V"  ECU
 SG_ NCellVAuxErrorFlags m7 : 32|8@1+ (1,0) [0|65535] ""  ECU
 SG_ TCell8N2 m3 : 32|8@1+ (1,-40) [-40|215] "°C"  ECU
 SG_ TCell5N2 m2 : 32|8@1+ (1,-40) [-40|215] "°C"  ECU
 SG_ TCell2N2 m1 : 32|8@1+ (1,-40) [-40|215] "°C"  ECU
 SG_ NReleaseMode m0 : 32|2@1+ (1,0) [0|3] ""  ECU
 SG_ VAuxCell3N1 m8 : 24|8@1+ (0.15,0) [0|38.25] "V"  ECU
 SG_ NSerial m6 : 24|32@1+ (1,0) [0|4294967295] ""  ECU
 SG_ NSettingsCrc m5 : 24|16@1+ (1,0) [0|65535] ""  ECU
 SG_ NConfigCrc m4 : 24|16@1+ (1,0) [0|65535] ""  ECU
 SG_ TCell8N1 m3 : 24|8@1+ (1,-40) [-40|215] "°C"  ECU
 SG_ TCell5N1 m2 : 24|8@1+ (1,-40) [-40|215] "°C"  ECU
 SG_ TCell2N1 m1 : 24|8@1+ (1,-40) [-40|215] "°C"  ECU
 SG_ VAux3Measured m0 : 24|8@1+ (0.01,0) [0|2.55] "V"  ECU
 SG_ VAuxCell8N1 m9 : 16|8@1+ (0.15,0) [0|38.25] "V"  ECU
 SG_ VAuxCell2N1 m8 : 16|8@1+ (0.15,0) [0|38.25] "V"  ECU
 SG_ NCellXcpErrorFlags m7 : 16|16@1+ (1,0) [0|65535] ""  ECU
 SG_ TCell7N2 m3 : 16|8@1+ (1,-40) [-40|215] "°C"  ECU
 SG_ TCell4N2 m2 : 16|8@1+ (1,-40) [-40|215] "°C"  ECU
 SG_ TCell1N2 m1 : 16|8@1+ (1,-40) [-40|215] "°C"  ECU
 SG_ VAux2Measured m0 : 16|8@1+ (0.02,0) [0|5.1] "V"  ECU
 SG_ VAuxCell7N1 m9 : 8|8@1+ (0.15,0) [0|38.25] "V"  ECU
 SG_ VAuxCell1N1 m8 : 8|8@1+ (0.15,0) [0|38.25] "V"  ECU
 SG_ NCellSwOcpErrorFlags m7 : 8|8@1+ (1,0) [0|255] ""  ECU
 SG_ NChecksum m6 : 8|16@1+ (1,0) [0|65535] ""  ECU
 SG_ NSettingsVersion m5 : 8|16@1+ (1,0) [0|65535] ""  ECU
 SG_ NConfigVersion m4 : 8|16@1+ (1,0) [0|65535] ""  ECU
 SG_ TCell7N1 m3 : 8|8@1+ (1,-40) [-40|215] "°C"  ECU
 SG_ TCell4N1 m2 : 8|8@1+ (1,-40) [-40|215] "°C"  ECU
 SG_ TCell1N1 m1 : 8|8@1+ (1,-40) [-40|215] "°C"  ECU
 SG_ VAux1Measured m0 : 8|8@1+ (0.15,0) [0|38.25] "V"  ECU
 SG_ NMultiplexer M : 0|8@1+ (1,0) [0|255] ""  ECU

BO_ 2147489793 BL5_Status: 8 DCDC
 SG_ BPath1AcModeActivated m0 : 63|1@1+ (1,0) [0|1] ""  ECU
 SG_ BPath1ErrVAuxCell m0 : 56|1@1+ (1,0) [0|1] ""  ECU
 SG_ IPath1Unbalance m0 : 48|8@1+ (0.25,0) [0|63.75] "A"  ECU
 SG_ BPath1RcpWarning m0 : 47|1@1+ (1,0) [0|1] ""  ECU
 SG_ BPath1OcpError m0 : 46|1@1+ (1,0) [0|1] ""  ECU
 SG_ BPath1OtpError m0 : 45|1@1+ (1,0) [0|1] ""  ECU
 SG_ BPath1SideBUvpError m0 : 44|1@1+ (1,0) [0|1] ""  ECU
 SG_ BPath1SideAUvpError m0 : 43|1@1+ (1,0) [0|1] ""  ECU
 SG_ BPath1SideBOvpError m0 : 42|1@1+ (1,0) [0|1] ""  ECU
 SG_ BPath1SideAOvpError m0 : 41|1@1+ (1,0) [0|1] ""  ECU
 SG_ BPath1Requested m0 : 40|1@1+ (1,0) [0|1] ""  ECU
 SG_ NPath1CurrentSideSelected m0 : 38|2@1+ (1,0) [0|3] ""  ECU
 SG_ NPath1VoltageSideSelected m0 : 36|2@1+ (1,0) [0|3] ""  ECU
 SG_ NPath1State m0 : 32|4@1+ (1,0) [0|15] ""  ECU
 SG_ NMultiplexer M : 29|3@1+ (1,0) [0|7] ""  ECU
 SG_ BXcpError : 28|1@1+ (1,0) [0|1] ""  ECU
 SG_ NCellHwErrorFlags : 20|8@1+ (1,0) [0|255] ""  ECU
 SG_ BIsoError : 19|1@1+ (1,0) [0|1] ""  ECU
 SG_ BSyncInputSignal : 18|1@1+ (1,0) [0|1] ""  ECU
 SG_ BSyncRequested : 17|1@1+ (1,0) [0|1] ""  ECU
 SG_ BInternalTemperatureError : 16|1@1+ (1,0) [0|1] ""  ECU
 SG_ BConfigSettingsError : 15|1@1+ (1,0) [0|1] ""  ECU
 SG_ BAuxSupplyError : 14|1@1+ (1,0) [0|1] ""  ECU
 SG_ BCanTimeoutError : 13|1@1+ (1,0) [0|1] ""  ECU
 SG_ BAuxIsoEnabled : 12|1@1+ (1,0) [0|1] ""  ECU
 SG_ BSafetyDischargeEnabled : 11|1@1+ (1,0) [0|1] ""  ECU
 SG_ BFaultSignal : 10|1@1+ (1,0) [0|1] ""  ECU
 SG_ BEnableSignal : 9|1@1+ (1,0) [0|1] ""  ECU
 SG_ BSafetyDischargeStatus : 8|1@1+ (1,0) [0|1] ""  ECU
 SG_ BSyncStatus : 7|1@1+ (1,0) [0|1] ""  ECU
 SG_ BReadConfigAndSettingsRequested : 6|1@1+ (1,0) [0|1] ""  ECU
 SG_ BSwResetModuleRequested : 5|1@1+ (1,0) [0|1] ""  ECU
 SG_ BSafetyDischargeRequested : 4|1@1+ (1,0) [0|1] ""  ECU
 SG_ NModuleState : 0|4@1+ (1,0) [0|15] ""  ECU

BO_ 2147489983 DCHVI_DcSetpoints1Write: 8 ECU
 SG_ NCRC : 56|8@1+ (1,0) [0|255] ""  DCDC
 SG_ NModuleSelect M : 48|6@1+ (1,0) [0|63] ""  DCDC
 SG_ BL5_NPath1CurrentSideSelect m1 : 42|2@1+ (1,0) [0|3] ""  DCDC
 SG_ BL6_NPath1CurrentSideSelect m1 : 42|2@1+ (1,0) [0|3] ""  DCDC
 SG_ BL7_NPath1CurrentSideSelect m1 : 42|2@1+ (1,0) [0|3] ""  DCDC
 SG_ BL5_NPath1VoltageSideSelect m1 : 40|2@1+ (1,0) [0|3] ""  DCDC
 SG_ BL6_NPath1VoltageSideSelect m1 : 40|2@1+ (1,0) [0|3] ""  DCDC
 SG_ BL7_NPath1VoltageSideSelect m1 : 40|2@1+ (1,0) [0|3] ""  DCDC
 SG_ BL5_IPath1LimitLo m1 : 28|12@1+ (0.5,-1000) [-1000|1047.5] "A"  DCDC
 SG_ BL6_IPath1LimitLo m1 : 28|12@1+ (0.5,-1000) [-1000|1047.5] "A"  DCDC
 SG_ BL7_IPath1LimitLo m1 : 28|12@1+ (0.5,-1000) [-1000|1047.5] "A"  DCDC
 SG_ BL5_IPath1LimitHi m1 : 16|12@1+ (0.5,-1000) [-1000|1047.5] "A"  DCDC
 SG_ BL6_IPath1LimitHi m1 : 16|12@1+ (0.5,-1000) [-1000|1047.5] "A"  DCDC
 SG_ BL7_IPath1LimitHi m1 : 16|12@1+ (0.5,-1000) [-1000|1047.5] "A"  DCDC
 SG_ BL5_VPath1Setpoint m1 : 4|12@1+ (1,0) [0|4095] "V"  DCDC
 SG_ BL6_VPath1Setpoint m1 : 4|12@1+ (1,0) [0|4095] "V"  DCDC
 SG_ BL7_VPath1Setpoint m1 : 4|12@1+ (1,0) [0|4095] "V"  DCDC
 SG_ BL5_NMultiplexer m1M : 0|4@1+ (1,0) [0|15] ""  DCDC
 SG_ BL6_NMultiplexer m2M : 0|4@1+ (1,0) [0|15] ""  DCDC
 SG_ BL7_NMultiplexer m3M : 0|4@1+ (1,0) [0|15] ""  DCDC

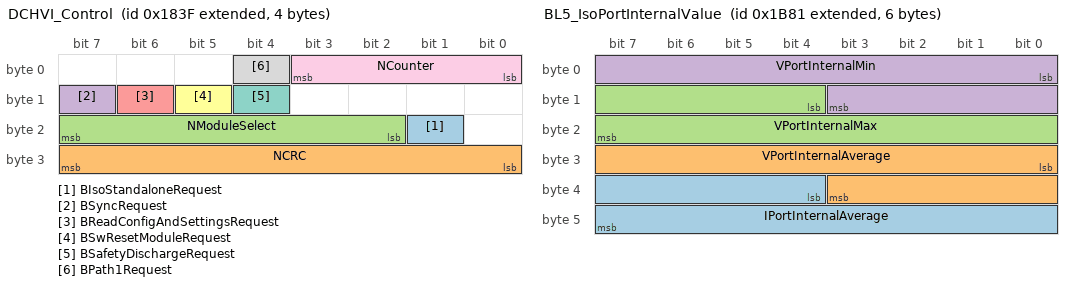
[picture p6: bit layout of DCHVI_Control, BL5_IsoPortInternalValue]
BO_ 2147489855 DCHVI_Control: 4 ECU
 SG_ BIsoStandaloneRequest : 17|1@1+ (1,0) [0|1] "" Vector__XXX
 SG_ NCRC : 24|8@1+ (1,0) [0|255] ""  DCDC
 SG_ NModuleSelect M : 18|6@1+ (1,0) [0|63] ""  DCDC
 SG_ BSyncRequest : 15|1@1+ (1,0) [0|1] ""  DCDC
 SG_ BReadConfigAndSettingsRequest : 14|1@1+ (1,0) [0|1] ""  DCDC
 SG_ BSwResetModuleRequest : 13|1@1+ (1,0) [0|1] ""  DCDC
 SG_ BSafetyDischargeRequest : 12|1@1+ (1,0) [0|1] ""  DCDC
 SG_ BPath1Request : 4|1@1+ (1,0) [0|1] ""  DCDC
 SG_ NCounter : 0|4@1+ (1,0) [0|15] ""  DCDC

BO_ 2147491713 BL5_IsoStatus: 6 DCDC
 SG_ BStartupTimeout : 40|1@1- (1,0) [0|1] ""  ECU
 SG_ BOtpBuckAux : 39|1@1+ (1,0) [0|1] ""  ECU
 SG_ BOtpSecError : 38|1@1+ (1,0) [0|1] ""  ECU
 SG_ BOtpPriError : 37|1@1+ (1,0) [0|1] ""  ECU
 SG_ BXcpBuckAuxError : 36|1@1+ (1,0) [0|1] ""  ECU
 SG_ BXcpDcdcError : 35|1@1+ (1,0) [0|1] ""  ECU
 SG_ BSecOcpError : 34|1@1+ (1,0) [0|1] ""  ECU
 SG_ BPriOcpError : 33|1@1+ (1,0) [0|1] ""  ECU
 SG_ BSecUvpError : 32|1@1+ (1,0) [0|1] ""  ECU
 SG_ BSecOvpError : 31|1@1+ (1,0) [0|1] ""  ECU
 SG_ BPriUvpError : 30|1@1+ (1,0) [0|1] ""  ECU
 SG_ BPriOvpError : 29|1@1+ (1,0) [0|1] ""  ECU
 SG_ BBuckOcpError : 28|1@1+ (1,0) [0|1] ""  ECU
 SG_ BSuppAuxUvpError : 27|1@1+ (1,0) [0|1] ""  ECU
 SG_ BSuppAuxOvpError : 26|1@1+ (1,0) [0|1] ""  ECU
 SG_ BBuckAuxHwError : 25|1@1+ (1,0) [0|1] ""  ECU
 SG_ BBuckVAuxDriverError : 24|1@1+ (1,0) [0|1] ""  ECU
 SG_ BAuxSupplyError : 23|1@1+ (1,0) [0|1] ""  ECU
 SG_ BCanIntTimeoutError : 22|1@1+ (1,0) [0|1] ""  ECU
 SG_ BCanTimeoutError : 21|1@1+ (1,0) [0|1] ""  ECU
 SG_ BConfigSettingsError : 20|1@1+ (1,0) [0|1] ""  ECU
 SG_ BPowerRequested : 19|1@1+ (1,0) [0|1] ""  ECU
 SG_ NAuxBuckState : 16|3@1+ (1,0) [0|7] ""  ECU
 SG_ NChan2State : 13|3@1+ (1,0) [0|7] ""  ECU
 SG_ NChan1State : 10|3@1+ (1,0) [0|7] ""  ECU
 SG_ BAuxIsoEnabled : 9|1@1+ (1,0) [0|1] ""  ECU
 SG_ BFaultSignal : 8|1@1+ (1,0) [0|1] ""  ECU
 SG_ BEnableSignal : 7|1@1+ (1,0) [0|1] ""  ECU
 SG_ BSyncInputSignal : 6|1@1+ (1,0) [0|1] ""  ECU
 SG_ BSyncStatus : 5|1@1+ (1,0) [0|1] ""  ECU
 SG_ BSwResetModuleRequested : 4|1@1+ (1,0) [0|1] ""  ECU
 SG_ NState : 0|4@1+ (1,0) [0|15] ""  ECU

BO_ 2147491777 BL5_IsoGlobalValues: 8 DCDC
 SG_ TSecCh2D m4 : 56|8@1+ (1,-40) [-40|215] "°C"  ECU
 SG_ TSecCh1D m3 : 56|8@1+ (1,-40) [-40|215] "°C"  ECU
 SG_ TPriCh2D m2 : 56|8@1+ (1,-40) [-40|215] "°C"  ECU
 SG_ TPriCh1D m1 : 56|8@1+ (1,-40) [-40|215] "°C"  ECU
 SG_ NReleaseMode m11 : 48|2@1+ (1,0) [0|3] ""  ECU
 SG_ NApplicationId m9 : 48|16@1+ (1,0) [0|65536] ""  ECU
 SG_ NSettingsVersion m8 : 48|16@1+ (1,0) [0|65536] ""  ECU
 SG_ NConfigCrc m7 : 48|16@1+ (1,0) [0|65536] ""  ECU
 SG_ NXcpDcdcErrorFlags m6 : 48|16@1+ (1,0) [0|65536] ""  ECU
 SG_ NOtpDcdcErrorFlags m5 : 48|16@1+ (1,0) [0|65536] ""  ECU
 SG_ TSecCh2C m4 : 48|8@1+ (1,-40) [-40|215] "°C"  ECU
 SG_ TSecCh1C m3 : 48|8@1+ (1,-40) [-40|215] "°C"  ECU
 SG_ TPriCh2C m2 : 48|8@1+ (1,-40) [-40|215] "°C"  ECU
 SG_ TPriCh1C m1 : 48|8@1+ (1,-40) [-40|215] "°C"  ECU
 SG_ V1v65Aux m0 : 48|8@1+ (0.01,0) [0|2.55] "V"  ECU
 SG_ VBuckAuxDriver m5 : 40|8@1+ (0.15,0) [0|38.25] "V"  ECU
 SG_ TSecCh2B m4 : 40|8@1+ (1,-40) [-40|215] "°C"  ECU
 SG_ TSecCh1B m3 : 40|8@1+ (1,-40) [-40|215] "°C"  ECU
 SG_ TPriCh2B m2 : 40|8@1+ (1,-40) [-40|215] "°C"  ECU
 SG_ TPriCh1B m1 : 40|8@1+ (1,-40) [-40|215] "°C"  ECU
 SG_ V3v3Aux m0 : 40|8@1+ (0.02,0) [0|5.1] "V"  ECU
 SG_ NMissedSyncPulseCount m12 : 32|16@1- (1,0) [0|65535] ""  ECU
 SG_ NChecksum m11 : 32|16@1+ (1,0) [0|65536] ""  ECU
 SG_ NSerial m10 : 32|32@1+ (1,0) [0|4294967296] ""  ECU
 SG_ NSettingsCrc m9 : 32|16@1+ (1,0) [0|65536] ""  ECU
 SG_ NBootloaderId m8 : 32|16@1+ (1,0) [0|65536] ""  ECU
 SG_ NConfigVersion m7 : 32|16@1+ (1,0) [0|65536] ""  ECU
 SG_ NOcpDcdcErrorFlags m6 : 32|16@1+ (1,0) [0|65536] ""  ECU
 SG_ TBuckAux m5 : 32|8@1+ (1,-40) [-40|215] "°C"  ECU
 SG_ TSecCh2A m4 : 32|8@1+ (1,-40) [-40|215] "°C"  ECU
 SG_ TSecCh1A m3 : 32|8@1+ (1,-40) [-40|215] "°C"  ECU
 SG_ TPriCh2A m2 : 32|8@1+ (1,-40) [-40|215] "°C"  ECU
 SG_ TPriCh1A m1 : 32|8@1+ (1,-40) [-40|215] "°C"  ECU
 SG_ VHvAux m0 : 32|8@1+ (0.15,0) [0|38.25] "V"  ECU
 SG_ NMultiplexer M : 24|4@1+ (1,0) [0|15] ""  ECU
 SG_ VSuppAux : 8|8@1+ (0.15,0) [0|38.25] "V"  ECU
 SG_ IBuckAux : 0|8@1+ (0.25,-30) [-30|33.75] "A"  ECU

BO_ 2147490689 BL5_IsoPortInternalValue: 6 DCDC
 SG_ IPortInternalAverage : 36|12@1+ (0.25,-500) [-500|523.75] "A"  ECU
 SG_ VPortInternalAverage : 24|12@1+ (1,0) [0|4095] "V"  ECU
 SG_ VPortInternalMax : 12|12@1+ (1,0) [0|4095] "V"  ECU
 SG_ VPortInternalMin : 0|12@1+ (1,0) [0|4095] "V"  ECU

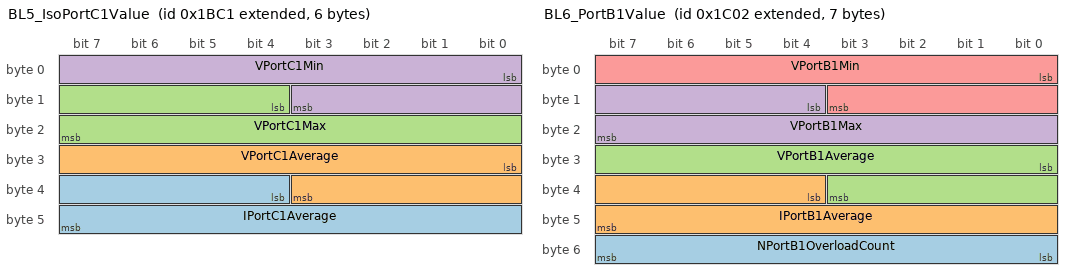
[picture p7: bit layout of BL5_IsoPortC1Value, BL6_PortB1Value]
BO_ 2147490753 BL5_IsoPortC1Value: 6 DCDC
 SG_ IPortC1Average : 36|12@1+ (0.25,-500) [-500|523.75] "A"  ECU
 SG_ VPortC1Average : 24|12@1+ (1,0) [0|4095] "V"  ECU
 SG_ VPortC1Max : 12|12@1+ (1,0) [0|4095] "V"  ECU
 SG_ VPortC1Min : 0|12@1+ (1,0) [0|4095] "V"  ECU

BO_ 2147491394 BL6_Setpoints1Value: 7 DCDC
 SG_ NPath1CurrentSideSelected m1 : 42|2@1+ (1,0) [0|3] ""  ECU
 SG_ NPath1VoltageSideSelected m1 : 40|2@1+ (1,0) [0|3] ""  ECU
 SG_ IPath1LimitLo m1 : 28|12@1+ (0.5,-1000) [-1000|1047.5] "A"  ECU
 SG_ IPath1LimitHi m1 : 16|12@1+ (0.5,-1000) [-1000|1047.5] "A"  ECU
 SG_ VPath1Setpoint m1 : 4|12@1+ (1,0) [0|4095] "V"  ECU
 SG_ NMultiplexer M : 0|4@1+ (1,0) [0|15] ""  ECU

BO_ 2147491458 BL6_Setpoints2Value: 6 DCDC
 SG_ PPath1LimitLo m1 : 24|16@1+ (100,-3000000) [-3000000|3553500] "W"  ECU
 SG_ PPath1LimitHi m1 : 8|16@1+ (100,-3000000) [-3000000|3553500] "W"  ECU
 SG_ NMultiplexer M : 0|4@1+ (1,0) [0|15] ""  ECU

BO_ 2147490818 BL6_PortB1Value: 7 DCDC
 SG_ NPortB1OverloadCount : 48|8@1+ (1,0) [0|255] ""  ECU
 SG_ IPortB1Average : 36|12@1+ (0.25,-500) [-500|523.75] "A"  ECU
 SG_ VPortB1Average : 24|12@1+ (1,0) [0|4095] "V"  ECU
 SG_ VPortB1Max : 12|12@1+ (1,0) [0|4095] "V"  ECU
 SG_ VPortB1Min : 0|12@1+ (1,0) [0|4095] "V"  ECU

BO_ 2147489922 BL6_PortA1Value: 8 DCDC
 SG_ NMultiplexer M : 56|8@1+ (1,0) [0|255] ""  ECU
 SG_ NPortA1OverloadCount m0 : 48|8@1+ (1,0) [0|255] ""  ECU
 SG_ IPortA1Average m0 : 36|12@1+ (0.25,-500) [-500|523.75] "A"  ECU
 SG_ VPortA1Average m0 : 24|12@1+ (1,0) [0|4095] "V"  ECU
 SG_ VPortA1Max m0 : 12|12@1+ (1,0) [0|4095] "V"  ECU
 SG_ VPortA1Min m0 : 0|12@1+ (1,0) [0|4095] "V"  ECU

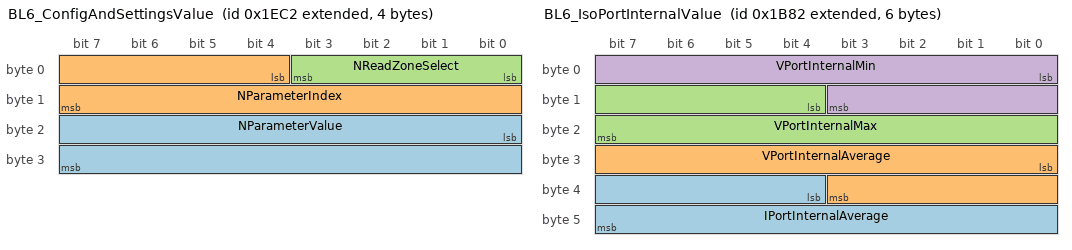
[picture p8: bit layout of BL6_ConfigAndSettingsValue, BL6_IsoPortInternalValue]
BO_ 2147491522 BL6_ConfigAndSettingsValue: 4 DCDC
 SG_ NParameterValue : 16|16@1+ (1,0) [0|65535] ""  ECU
 SG_ NParameterIndex : 4|12@1+ (1,0) [0|4095] ""  ECU
 SG_ NReadZoneSelect : 0|4@1+ (1,0) [0|15] ""  ECU

BO_ 2147489858 BL6_GlobalValue: 8 DCDC
 SG_ BSetpointsApplied : 56|1@1+ (1,0) [0|1] ""  ECU
 SG_ VAuxCell6N1 m8 : 48|8@1+ (0.15,0) [0|38.25] "V"  ECU
 SG_ TCell6N2 m2 : 48|8@1+ (1,-40) [-40|215] "°C"  ECU
 SG_ TCell3N2 m1 : 48|8@1+ (1,-40) [-40|215] "°C"  ECU
 SG_ NCellOtpErrorFlags m0 : 48|8@1+ (1,0) [0|255] ""  ECU
 SG_ VAuxCell5N1 m8 : 40|8@1+ (0.15,0) [0|38.25] "V"  ECU
 SG_ NApplicationId m5 : 40|16@1+ (1,0) [0|65535] ""  ECU
 SG_ NBootloaderId m4 : 40|16@1+ (1,0) [0|65535] ""  ECU
 SG_ TInternal m3 : 40|8@1+ (1,-40) [-40|215] "°C"  ECU
 SG_ TCell6N1 m2 : 40|8@1+ (1,-40) [-40|215] "°C"  ECU
 SG_ TCell3N1 m1 : 40|8@1+ (1,-40) [-40|215] "°C"  ECU
 SG_ NSyncNodeCount m0 : 39|5@1+ (1,0) [0|31] ""  ECU
 SG_ NSyncNodeRank m0 : 34|5@1+ (1,0) [0|31] ""  ECU
 SG_ VAuxCell4N1 m8 : 32|8@1+ (0.15,0) [0|38.25] "V"  ECU
 SG_ NCellVAuxErrorFlags m7 : 32|8@1+ (1,0) [0|65535] ""  ECU
 SG_ TCell8N2 m3 : 32|8@1+ (1,-40) [-40|215] "°C"  ECU
 SG_ TCell5N2 m2 : 32|8@1+ (1,-40) [-40|215] "°C"  ECU
 SG_ TCell2N2 m1 : 32|8@1+ (1,-40) [-40|215] "°C"  ECU
 SG_ NReleaseMode m0 : 32|2@1+ (1,0) [0|3] ""  ECU
 SG_ VAuxCell3N1 m8 : 24|8@1+ (0.15,0) [0|38.25] "V"  ECU
 SG_ NSerial m6 : 24|32@1+ (1,0) [0|4294967295] ""  ECU
 SG_ NSettingsCrc m5 : 24|16@1+ (1,0) [0|65535] ""  ECU
 SG_ NConfigCrc m4 : 24|16@1+ (1,0) [0|65535] ""  ECU
 SG_ TCell8N1 m3 : 24|8@1+ (1,-40) [-40|215] "°C"  ECU
 SG_ TCell5N1 m2 : 24|8@1+ (1,-40) [-40|215] "°C"  ECU
 SG_ TCell2N1 m1 : 24|8@1+ (1,-40) [-40|215] "°C"  ECU
 SG_ VAux3Measured m0 : 24|8@1+ (0.01,0) [0|2.55] "V"  ECU
 SG_ VAuxCell8N1 m9 : 16|8@1+ (0.15,0) [0|38.25] "V"  ECU
 SG_ VAuxCell2N1 m8 : 16|8@1+ (0.15,0) [0|38.25] "V"  ECU
 SG_ NCellXcpErrorFlags m7 : 16|16@1+ (1,0) [0|65535] ""  ECU
 SG_ TCell7N2 m3 : 16|8@1+ (1,-40) [-40|215] "°C"  ECU
 SG_ TCell4N2 m2 : 16|8@1+ (1,-40) [-40|215] "°C"  ECU
 SG_ TCell1N2 m1 : 16|8@1+ (1,-40) [-40|215] "°C"  ECU
 SG_ VAux2Measured m0 : 16|8@1+ (0.02,0) [0|5.1] "V"  ECU
 SG_ VAuxCell7N1 m9 : 8|8@1+ (0.15,0) [0|38.25] "V"  ECU
 SG_ VAuxCell1N1 m8 : 8|8@1+ (0.15,0) [0|38.25] "V"  ECU
 SG_ NCellSwOcpErrorFlags m7 : 8|8@1+ (1,0) [0|255] ""  ECU
 SG_ NChecksum m6 : 8|16@1+ (1,0) [0|65535] ""  ECU
 SG_ NSettingsVersion m5 : 8|16@1+ (1,0) [0|65535] ""  ECU
 SG_ NConfigVersion m4 : 8|16@1+ (1,0) [0|65535] ""  ECU
 SG_ TCell7N1 m3 : 8|8@1+ (1,-40) [-40|215] "°C"  ECU
 SG_ TCell4N1 m2 : 8|8@1+ (1,-40) [-40|215] "°C"  ECU
 SG_ TCell1N1 m1 : 8|8@1+ (1,-40) [-40|215] "°C"  ECU
 SG_ VAux1Measured m0 : 8|8@1+ (0.15,0) [0|38.25] "V"  ECU
 SG_ NMultiplexer M : 0|8@1+ (1,0) [0|255] ""  ECU

BO_ 2147489794 BL6_Status: 8 DCDC
 SG_ BPath1AcModeActivated m0 : 63|1@1+ (1,0) [0|1] ""  ECU
 SG_ BPath1ErrVAuxCell m0 : 56|1@1+ (1,0) [0|1] ""  ECU
 SG_ IPath1Unbalance m0 : 48|8@1+ (0.25,0) [0|63.75] "A"  ECU
 SG_ BPath1RcpWarning m0 : 47|1@1+ (1,0) [0|1] ""  ECU
 SG_ BPath1OcpError m0 : 46|1@1+ (1,0) [0|1] ""  ECU
 SG_ BPath1OtpError m0 : 45|1@1+ (1,0) [0|1] ""  ECU
 SG_ BPath1SideBUvpError m0 : 44|1@1+ (1,0) [0|1] ""  ECU
 SG_ BPath1SideAUvpError m0 : 43|1@1+ (1,0) [0|1] ""  ECU
 SG_ BPath1SideBOvpError m0 : 42|1@1+ (1,0) [0|1] ""  ECU
 SG_ BPath1SideAOvpError m0 : 41|1@1+ (1,0) [0|1] ""  ECU
 SG_ BPath1Requested m0 : 40|1@1+ (1,0) [0|1] ""  ECU
 SG_ NPath1CurrentSideSelected m0 : 38|2@1+ (1,0) [0|3] ""  ECU
 SG_ NPath1VoltageSideSelected m0 : 36|2@1+ (1,0) [0|3] ""  ECU
 SG_ NPath1State m0 : 32|4@1+ (1,0) [0|15] ""  ECU
 SG_ NMultiplexer M : 29|3@1+ (1,0) [0|7] ""  ECU
 SG_ BXcpError : 28|1@1+ (1,0) [0|1] ""  ECU
 SG_ NCellHwErrorFlags : 20|8@1+ (1,0) [0|255] ""  ECU
 SG_ BIsoError : 19|1@1+ (1,0) [0|1] ""  ECU
 SG_ BSyncInputSignal : 18|1@1+ (1,0) [0|1] ""  ECU
 SG_ BSyncRequested : 17|1@1+ (1,0) [0|1] ""  ECU
 SG_ BInternalTemperatureError : 16|1@1+ (1,0) [0|1] ""  ECU
 SG_ BConfigSettingsError : 15|1@1+ (1,0) [0|1] ""  ECU
 SG_ BAuxSupplyError : 14|1@1+ (1,0) [0|1] ""  ECU
 SG_ BCanTimeoutError : 13|1@1+ (1,0) [0|1] ""  ECU
 SG_ BAuxIsoEnabled : 12|1@1+ (1,0) [0|1] ""  ECU
 SG_ BSafetyDischargeEnabled : 11|1@1+ (1,0) [0|1] ""  ECU
 SG_ BFaultSignal : 10|1@1+ (1,0) [0|1] ""  ECU
 SG_ BEnableSignal : 9|1@1+ (1,0) [0|1] ""  ECU
 SG_ BSafetyDischargeStatus : 8|1@1+ (1,0) [0|1] ""  ECU
 SG_ BSyncStatus : 7|1@1+ (1,0) [0|1] ""  ECU
 SG_ BReadConfigAndSettingsRequested : 6|1@1+ (1,0) [0|1] ""  ECU
 SG_ BSwResetModuleRequested : 5|1@1+ (1,0) [0|1] ""  ECU
 SG_ BSafetyDischargeRequested : 4|1@1+ (1,0) [0|1] ""  ECU
 SG_ NModuleState : 0|4@1+ (1,0) [0|15] ""  ECU

BO_ 2147491714 BL6_IsoStatus: 6 DCDC
 SG_ BStartupTimeout : 40|1@1- (1,0) [0|1] ""  ECU
 SG_ BOtpBuckAux : 39|1@1+ (1,0) [0|1] ""  ECU
 SG_ BOtpSecError : 38|1@1+ (1,0) [0|1] ""  ECU
 SG_ BOtpPriError : 37|1@1+ (1,0) [0|1] ""  ECU
 SG_ BXcpBuckAuxError : 36|1@1+ (1,0) [0|1] ""  ECU
 SG_ BXcpDcdcError : 35|1@1+ (1,0) [0|1] ""  ECU
 SG_ BSecOcpError : 34|1@1+ (1,0) [0|1] ""  ECU
 SG_ BPriOcpError : 33|1@1+ (1,0) [0|1] ""  ECU
 SG_ BSecUvpError : 32|1@1+ (1,0) [0|1] ""  ECU
 SG_ BSecOvpError : 31|1@1+ (1,0) [0|1] ""  ECU
 SG_ BPriUvpError : 30|1@1+ (1,0) [0|1] ""  ECU
 SG_ BPriOvpError : 29|1@1+ (1,0) [0|1] ""  ECU
 SG_ BBuckOcpError : 28|1@1+ (1,0) [0|1] ""  ECU
 SG_ BSuppAuxUvpError : 27|1@1+ (1,0) [0|1] ""  ECU
 SG_ BSuppAuxOvpError : 26|1@1+ (1,0) [0|1] ""  ECU
 SG_ BBuckAuxHwError : 25|1@1+ (1,0) [0|1] ""  ECU
 SG_ BBuckVAuxDriverError : 24|1@1+ (1,0) [0|1] ""  ECU
 SG_ BAuxSupplyError : 23|1@1+ (1,0) [0|1] ""  ECU
 SG_ BCanIntTimeoutError : 22|1@1+ (1,0) [0|1] ""  ECU
 SG_ BCanTimeoutError : 21|1@1+ (1,0) [0|1] ""  ECU
 SG_ BConfigSettingsError : 20|1@1+ (1,0) [0|1] ""  ECU
 SG_ BPowerRequested : 19|1@1+ (1,0) [0|1] ""  ECU
 SG_ NAuxBuckState : 16|3@1+ (1,0) [0|7] ""  ECU
 SG_ NChan2State : 13|3@1+ (1,0) [0|7] ""  ECU
 SG_ NChan1State : 10|3@1+ (1,0) [0|7] ""  ECU
 SG_ BAuxIsoEnabled : 9|1@1+ (1,0) [0|1] ""  ECU
 SG_ BFaultSignal : 8|1@1+ (1,0) [0|1] ""  ECU
 SG_ BEnableSignal : 7|1@1+ (1,0) [0|1] ""  ECU
 SG_ BSyncInputSignal : 6|1@1+ (1,0) [0|1] ""  ECU
 SG_ BSyncStatus : 5|1@1+ (1,0) [0|1] ""  ECU
 SG_ BSwResetModuleRequested : 4|1@1+ (1,0) [0|1] ""  ECU
 SG_ NState : 0|4@1+ (1,0) [0|15] ""  ECU

BO_ 2147491778 BL6_IsoGlobalValues: 8 DCDC
 SG_ TSecCh2D m4 : 56|8@1+ (1,-40) [-40|215] "°C"  ECU
 SG_ TSecCh1D m3 : 56|8@1+ (1,-40) [-40|215] "°C"  ECU
 SG_ TPriCh2D m2 : 56|8@1+ (1,-40) [-40|215] "°C"  ECU
 SG_ TPriCh1D m1 : 56|8@1+ (1,-40) [-40|215] "°C"  ECU
 SG_ NReleaseMode m11 : 48|2@1+ (1,0) [0|3] ""  ECU
 SG_ NApplicationId m9 : 48|16@1+ (1,0) [0|65536] ""  ECU
 SG_ NSettingsVersion m8 : 48|16@1+ (1,0) [0|65536] ""  ECU
 SG_ NConfigCrc m7 : 48|16@1+ (1,0) [0|65536] ""  ECU
 SG_ NXcpDcdcErrorFlags m6 : 48|16@1+ (1,0) [0|65536] ""  ECU
 SG_ NOtpDcdcErrorFlags m5 : 48|16@1+ (1,0) [0|65536] ""  ECU
 SG_ TSecCh2C m4 : 48|8@1+ (1,-40) [-40|215] "°C"  ECU
 SG_ TSecCh1C m3 : 48|8@1+ (1,-40) [-40|215] "°C"  ECU
 SG_ TPriCh2C m2 : 48|8@1+ (1,-40) [-40|215] "°C"  ECU
 SG_ TPriCh1C m1 : 48|8@1+ (1,-40) [-40|215] "°C"  ECU
 SG_ V1v65Aux m0 : 48|8@1+ (0.01,0) [0|2.55] "V"  ECU
 SG_ VBuckAuxDriver m5 : 40|8@1+ (0.15,0) [0|38.25] "V"  ECU
 SG_ TSecCh2B m4 : 40|8@1+ (1,-40) [-40|215] "°C"  ECU
 SG_ TSecCh1B m3 : 40|8@1+ (1,-40) [-40|215] "°C"  ECU
 SG_ TPriCh2B m2 : 40|8@1+ (1,-40) [-40|215] "°C"  ECU
 SG_ TPriCh1B m1 : 40|8@1+ (1,-40) [-40|215] "°C"  ECU
 SG_ V3v3Aux m0 : 40|8@1+ (0.02,0) [0|5.1] "V"  ECU
 SG_ NMissedSyncPulseCount m12 : 32|16@1- (1,0) [0|65535] ""  ECU
 SG_ NChecksum m11 : 32|16@1+ (1,0) [0|65536] ""  ECU
 SG_ NSerial m10 : 32|32@1+ (1,0) [0|4294967296] ""  ECU
 SG_ NSettingsCrc m9 : 32|16@1+ (1,0) [0|65536] ""  ECU
 SG_ NBootloaderId m8 : 32|16@1+ (1,0) [0|65536] ""  ECU
 SG_ NConfigVersion m7 : 32|16@1+ (1,0) [0|65536] ""  ECU
 SG_ NOcpDcdcErrorFlags m6 : 32|16@1+ (1,0) [0|65536] ""  ECU
 SG_ TBuckAux m5 : 32|8@1+ (1,-40) [-40|215] "°C"  ECU
 SG_ TSecCh2A m4 : 32|8@1+ (1,-40) [-40|215] "°C"  ECU
 SG_ TSecCh1A m3 : 32|8@1+ (1,-40) [-40|215] "°C"  ECU
 SG_ TPriCh2A m2 : 32|8@1+ (1,-40) [-40|215] "°C"  ECU
 SG_ TPriCh1A m1 : 32|8@1+ (1,-40) [-40|215] "°C"  ECU
 SG_ VHvAux m0 : 32|8@1+ (0.15,0) [0|38.25] "V"  ECU
 SG_ NMultiplexer M : 24|4@1+ (1,0) [0|15] ""  ECU
 SG_ VSuppAux : 8|8@1+ (0.15,0) [0|38.25] "V"  ECU
 SG_ IBuckAux : 0|8@1+ (0.25,-30) [-30|33.75] "A"  ECU

BO_ 2147490690 BL6_IsoPortInternalValue: 6 DCDC
 SG_ IPortInternalAverage : 36|12@1+ (0.25,-500) [-500|523.75] "A"  ECU
 SG_ VPortInternalAverage : 24|12@1+ (1,0) [0|4095] "V"  ECU
 SG_ VPortInternalMax : 12|12@1+ (1,0) [0|4095] "V"  ECU
 SG_ VPortInternalMin : 0|12@1+ (1,0) [0|4095] "V"  ECU

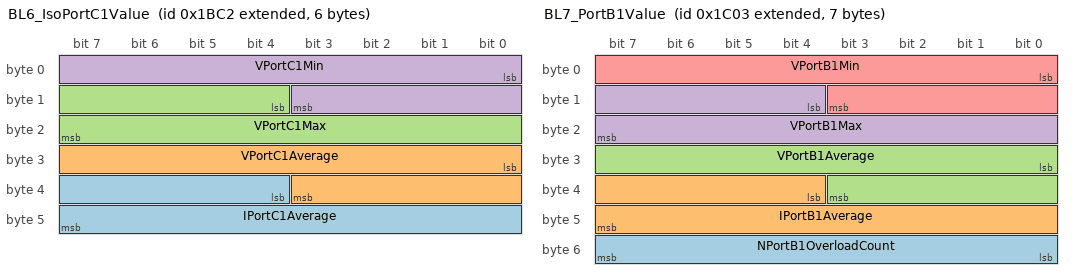
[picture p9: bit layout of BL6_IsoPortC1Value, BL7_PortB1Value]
BO_ 2147490754 BL6_IsoPortC1Value: 6 DCDC
 SG_ IPortC1Average : 36|12@1+ (0.25,-500) [-500|523.75] "A"  ECU
 SG_ VPortC1Average : 24|12@1+ (1,0) [0|4095] "V"  ECU
 SG_ VPortC1Max : 12|12@1+ (1,0) [0|4095] "V"  ECU
 SG_ VPortC1Min : 0|12@1+ (1,0) [0|4095] "V"  ECU

BO_ 2147491395 BL7_Setpoints1Value: 7 DCDC
 SG_ NPath1CurrentSideSelected m1 : 42|2@1+ (1,0) [0|3] ""  ECU
 SG_ NPath1VoltageSideSelected m1 : 40|2@1+ (1,0) [0|3] ""  ECU
 SG_ IPath1LimitLo m1 : 28|12@1+ (0.5,-1000) [-1000|1047.5] "A"  ECU
 SG_ IPath1LimitHi m1 : 16|12@1+ (0.5,-1000) [-1000|1047.5] "A"  ECU
 SG_ VPath1Setpoint m1 : 4|12@1+ (1,0) [0|4095] "V"  ECU
 SG_ NMultiplexer M : 0|4@1+ (1,0) [0|15] ""  ECU

BO_ 2147491459 BL7_Setpoints2Value: 6 DCDC
 SG_ PPath1LimitLo m1 : 24|16@1+ (100,-3000000) [-3000000|3553500] "W"  ECU
 SG_ PPath1LimitHi m1 : 8|16@1+ (100,-3000000) [-3000000|3553500] "W"  ECU
 SG_ NMultiplexer M : 0|4@1+ (1,0) [0|15] ""  ECU

BO_ 2147490819 BL7_PortB1Value: 7 DCDC
 SG_ NPortB1OverloadCount : 48|8@1+ (1,0) [0|255] ""  ECU
 SG_ IPortB1Average : 36|12@1+ (0.25,-500) [-500|523.75] "A"  ECU
 SG_ VPortB1Average : 24|12@1+ (1,0) [0|4095] "V"  ECU
 SG_ VPortB1Max : 12|12@1+ (1,0) [0|4095] "V"  ECU
 SG_ VPortB1Min : 0|12@1+ (1,0) [0|4095] "V"  ECU

BO_ 2147489923 BL7_PortA1Value: 8 DCDC
 SG_ NMultiplexer M : 56|8@1+ (1,0) [0|255] ""  ECU
 SG_ NPortA1OverloadCount m0 : 48|8@1+ (1,0) [0|255] ""  ECU
 SG_ IPortA1Average m0 : 36|12@1+ (0.25,-500) [-500|523.75] "A"  ECU
 SG_ VPortA1Average m0 : 24|12@1+ (1,0) [0|4095] "V"  ECU
 SG_ VPortA1Max m0 : 12|12@1+ (1,0) [0|4095] "V"  ECU
 SG_ VPortA1Min m0 : 0|12@1+ (1,0) [0|4095] "V"  ECU

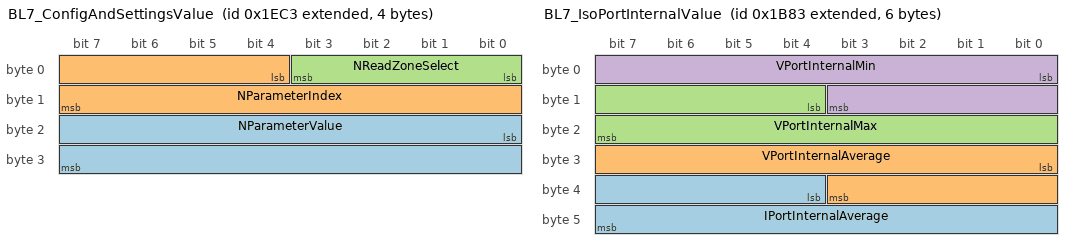
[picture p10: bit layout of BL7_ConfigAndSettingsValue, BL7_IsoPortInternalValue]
BO_ 2147491523 BL7_ConfigAndSettingsValue: 4 DCDC
 SG_ NParameterValue : 16|16@1+ (1,0) [0|65535] ""  ECU
 SG_ NParameterIndex : 4|12@1+ (1,0) [0|4095] ""  ECU
 SG_ NReadZoneSelect : 0|4@1+ (1,0) [0|15] ""  ECU

BO_ 2147489859 BL7_GlobalValue: 8 DCDC
 SG_ BSetpointsApplied : 56|1@1+ (1,0) [0|1] ""  ECU
 SG_ VAuxCell6N1 m8 : 48|8@1+ (0.15,0) [0|38.25] "V"  ECU
 SG_ TCell6N2 m2 : 48|8@1+ (1,-40) [-40|215] "°C"  ECU
 SG_ TCell3N2 m1 : 48|8@1+ (1,-40) [-40|215] "°C"  ECU
 SG_ NCellOtpErrorFlags m0 : 48|8@1+ (1,0) [0|255] ""  ECU
 SG_ VAuxCell5N1 m8 : 40|8@1+ (0.15,0) [0|38.25] "V"  ECU
 SG_ NApplicationId m5 : 40|16@1+ (1,0) [0|65535] ""  ECU
 SG_ NBootloaderId m4 : 40|16@1+ (1,0) [0|65535] ""  ECU
 SG_ TInternal m3 : 40|8@1+ (1,-40) [-40|215] "°C"  ECU
 SG_ TCell6N1 m2 : 40|8@1+ (1,-40) [-40|215] "°C"  ECU
 SG_ TCell3N1 m1 : 40|8@1+ (1,-40) [-40|215] "°C"  ECU
 SG_ NSyncNodeCount m0 : 39|5@1+ (1,0) [0|31] ""  ECU
 SG_ NSyncNodeRank m0 : 34|5@1+ (1,0) [0|31] ""  ECU
 SG_ VAuxCell4N1 m8 : 32|8@1+ (0.15,0) [0|38.25] "V"  ECU
 SG_ NCellVAuxErrorFlags m7 : 32|8@1+ (1,0) [0|65535] ""  ECU
 SG_ TCell8N2 m3 : 32|8@1+ (1,-40) [-40|215] "°C"  ECU
 SG_ TCell5N2 m2 : 32|8@1+ (1,-40) [-40|215] "°C"  ECU
 SG_ TCell2N2 m1 : 32|8@1+ (1,-40) [-40|215] "°C"  ECU
 SG_ NReleaseMode m0 : 32|2@1+ (1,0) [0|3] ""  ECU
 SG_ VAuxCell3N1 m8 : 24|8@1+ (0.15,0) [0|38.25] "V"  ECU
 SG_ NSerial m6 : 24|32@1+ (1,0) [0|4294967295] ""  ECU
 SG_ NSettingsCrc m5 : 24|16@1+ (1,0) [0|65535] ""  ECU
 SG_ NConfigCrc m4 : 24|16@1+ (1,0) [0|65535] ""  ECU
 SG_ TCell8N1 m3 : 24|8@1+ (1,-40) [-40|215] "°C"  ECU
 SG_ TCell5N1 m2 : 24|8@1+ (1,-40) [-40|215] "°C"  ECU
 SG_ TCell2N1 m1 : 24|8@1+ (1,-40) [-40|215] "°C"  ECU
 SG_ VAux3Measured m0 : 24|8@1+ (0.01,0) [0|2.55] "V"  ECU
 SG_ VAuxCell8N1 m9 : 16|8@1+ (0.15,0) [0|38.25] "V"  ECU
 SG_ VAuxCell2N1 m8 : 16|8@1+ (0.15,0) [0|38.25] "V"  ECU
 SG_ NCellXcpErrorFlags m7 : 16|16@1+ (1,0) [0|65535] ""  ECU
 SG_ TCell7N2 m3 : 16|8@1+ (1,-40) [-40|215] "°C"  ECU
 SG_ TCell4N2 m2 : 16|8@1+ (1,-40) [-40|215] "°C"  ECU
 SG_ TCell1N2 m1 : 16|8@1+ (1,-40) [-40|215] "°C"  ECU
 SG_ VAux2Measured m0 : 16|8@1+ (0.02,0) [0|5.1] "V"  ECU
 SG_ VAuxCell7N1 m9 : 8|8@1+ (0.15,0) [0|38.25] "V"  ECU
 SG_ VAuxCell1N1 m8 : 8|8@1+ (0.15,0) [0|38.25] "V"  ECU
 SG_ NCellSwOcpErrorFlags m7 : 8|8@1+ (1,0) [0|255] ""  ECU
 SG_ NChecksum m6 : 8|16@1+ (1,0) [0|65535] ""  ECU
 SG_ NSettingsVersion m5 : 8|16@1+ (1,0) [0|65535] ""  ECU
 SG_ NConfigVersion m4 : 8|16@1+ (1,0) [0|65535] ""  ECU
 SG_ TCell7N1 m3 : 8|8@1+ (1,-40) [-40|215] "°C"  ECU
 SG_ TCell4N1 m2 : 8|8@1+ (1,-40) [-40|215] "°C"  ECU
 SG_ TCell1N1 m1 : 8|8@1+ (1,-40) [-40|215] "°C"  ECU
 SG_ VAux1Measured m0 : 8|8@1+ (0.15,0) [0|38.25] "V"  ECU
 SG_ NMultiplexer M : 0|8@1+ (1,0) [0|255] ""  ECU

BO_ 2147489795 BL7_Status: 8 DCDC
 SG_ BPath1AcModeActivated m0 : 63|1@1+ (1,0) [0|1] ""  ECU
 SG_ BPath1ErrVAuxCell m0 : 56|1@1+ (1,0) [0|1] ""  ECU
 SG_ IPath1Unbalance m0 : 48|8@1+ (0.25,0) [0|63.75] "A"  ECU
 SG_ BPath1RcpWarning m0 : 47|1@1+ (1,0) [0|1] ""  ECU
 SG_ BPath1OcpError m0 : 46|1@1+ (1,0) [0|1] ""  ECU
 SG_ BPath1OtpError m0 : 45|1@1+ (1,0) [0|1] ""  ECU
 SG_ BPath1SideBUvpError m0 : 44|1@1+ (1,0) [0|1] ""  ECU
 SG_ BPath1SideAUvpError m0 : 43|1@1+ (1,0) [0|1] ""  ECU
 SG_ BPath1SideBOvpError m0 : 42|1@1+ (1,0) [0|1] ""  ECU
 SG_ BPath1SideAOvpError m0 : 41|1@1+ (1,0) [0|1] ""  ECU
 SG_ BPath1Requested m0 : 40|1@1+ (1,0) [0|1] ""  ECU
 SG_ NPath1CurrentSideSelected m0 : 38|2@1+ (1,0) [0|3] ""  ECU
 SG_ NPath1VoltageSideSelected m0 : 36|2@1+ (1,0) [0|3] ""  ECU
 SG_ NPath1State m0 : 32|4@1+ (1,0) [0|15] ""  ECU
 SG_ NMultiplexer M : 29|3@1+ (1,0) [0|7] ""  ECU
 SG_ BXcpError : 28|1@1+ (1,0) [0|1] ""  ECU
 SG_ NCellHwErrorFlags : 20|8@1+ (1,0) [0|255] ""  ECU
 SG_ BIsoError : 19|1@1+ (1,0) [0|1] ""  ECU
 SG_ BSyncInputSignal : 18|1@1+ (1,0) [0|1] ""  ECU
 SG_ BSyncRequested : 17|1@1+ (1,0) [0|1] ""  ECU
 SG_ BInternalTemperatureError : 16|1@1+ (1,0) [0|1] ""  ECU
 SG_ BConfigSettingsError : 15|1@1+ (1,0) [0|1] ""  ECU
 SG_ BAuxSupplyError : 14|1@1+ (1,0) [0|1] ""  ECU
 SG_ BCanTimeoutError : 13|1@1+ (1,0) [0|1] ""  ECU
 SG_ BAuxIsoEnabled : 12|1@1+ (1,0) [0|1] ""  ECU
 SG_ BSafetyDischargeEnabled : 11|1@1+ (1,0) [0|1] ""  ECU
 SG_ BFaultSignal : 10|1@1+ (1,0) [0|1] ""  ECU
 SG_ BEnableSignal : 9|1@1+ (1,0) [0|1] ""  ECU
 SG_ BSafetyDischargeStatus : 8|1@1+ (1,0) [0|1] ""  ECU
 SG_ BSyncStatus : 7|1@1+ (1,0) [0|1] ""  ECU
 SG_ BReadConfigAndSettingsRequested : 6|1@1+ (1,0) [0|1] ""  ECU
 SG_ BSwResetModuleRequested : 5|1@1+ (1,0) [0|1] ""  ECU
 SG_ BSafetyDischargeRequested : 4|1@1+ (1,0) [0|1] ""  ECU
 SG_ NModuleState : 0|4@1+ (1,0) [0|15] ""  ECU

BO_ 2147491715 BL7_IsoStatus: 6 DCDC
 SG_ BStartupTimeout : 40|1@1- (1,0) [0|1] ""  ECU
 SG_ BOtpBuckAux : 39|1@1+ (1,0) [0|1] ""  ECU
 SG_ BOtpSecError : 38|1@1+ (1,0) [0|1] ""  ECU
 SG_ BOtpPriError : 37|1@1+ (1,0) [0|1] ""  ECU
 SG_ BXcpBuckAuxError : 36|1@1+ (1,0) [0|1] ""  ECU
 SG_ BXcpDcdcError : 35|1@1+ (1,0) [0|1] ""  ECU
 SG_ BSecOcpError : 34|1@1+ (1,0) [0|1] ""  ECU
 SG_ BPriOcpError : 33|1@1+ (1,0) [0|1] ""  ECU
 SG_ BSecUvpError : 32|1@1+ (1,0) [0|1] ""  ECU
 SG_ BSecOvpError : 31|1@1+ (1,0) [0|1] ""  ECU
 SG_ BPriUvpError : 30|1@1+ (1,0) [0|1] ""  ECU
 SG_ BPriOvpError : 29|1@1+ (1,0) [0|1] ""  ECU
 SG_ BBuckOcpError : 28|1@1+ (1,0) [0|1] ""  ECU
 SG_ BSuppAuxUvpError : 27|1@1+ (1,0) [0|1] ""  ECU
 SG_ BSuppAuxOvpError : 26|1@1+ (1,0) [0|1] ""  ECU
 SG_ BBuckAuxHwError : 25|1@1+ (1,0) [0|1] ""  ECU
 SG_ BBuckVAuxDriverError : 24|1@1+ (1,0) [0|1] ""  ECU
 SG_ BAuxSupplyError : 23|1@1+ (1,0) [0|1] ""  ECU
 SG_ BCanIntTimeoutError : 22|1@1+ (1,0) [0|1] ""  ECU
 SG_ BCanTimeoutError : 21|1@1+ (1,0) [0|1] ""  ECU
 SG_ BConfigSettingsError : 20|1@1+ (1,0) [0|1] ""  ECU
 SG_ BPowerRequested : 19|1@1+ (1,0) [0|1] ""  ECU
 SG_ NAuxBuckState : 16|3@1+ (1,0) [0|7] ""  ECU
 SG_ NChan2State : 13|3@1+ (1,0) [0|7] ""  ECU
 SG_ NChan1State : 10|3@1+ (1,0) [0|7] ""  ECU
 SG_ BAuxIsoEnabled : 9|1@1+ (1,0) [0|1] ""  ECU
 SG_ BFaultSignal : 8|1@1+ (1,0) [0|1] ""  ECU
 SG_ BEnableSignal : 7|1@1+ (1,0) [0|1] ""  ECU
 SG_ BSyncInputSignal : 6|1@1+ (1,0) [0|1] ""  ECU
 SG_ BSyncStatus : 5|1@1+ (1,0) [0|1] ""  ECU
 SG_ BSwResetModuleRequested : 4|1@1+ (1,0) [0|1] ""  ECU
 SG_ NState : 0|4@1+ (1,0) [0|15] ""  ECU

BO_ 2147491779 BL7_IsoGlobalValues: 8 DCDC
 SG_ TSecCh2D m4 : 56|8@1+ (1,-40) [-40|215] "°C"  ECU
 SG_ TSecCh1D m3 : 56|8@1+ (1,-40) [-40|215] "°C"  ECU
 SG_ TPriCh2D m2 : 56|8@1+ (1,-40) [-40|215] "°C"  ECU
 SG_ TPriCh1D m1 : 56|8@1+ (1,-40) [-40|215] "°C"  ECU
 SG_ NReleaseMode m11 : 48|2@1+ (1,0) [0|3] ""  ECU
 SG_ NApplicationId m9 : 48|16@1+ (1,0) [0|65536] ""  ECU
 SG_ NSettingsVersion m8 : 48|16@1+ (1,0) [0|65536] ""  ECU
 SG_ NConfigCrc m7 : 48|16@1+ (1,0) [0|65536] ""  ECU
 SG_ NXcpDcdcErrorFlags m6 : 48|16@1+ (1,0) [0|65536] ""  ECU
 SG_ NOtpDcdcErrorFlags m5 : 48|16@1+ (1,0) [0|65536] ""  ECU
 SG_ TSecCh2C m4 : 48|8@1+ (1,-40) [-40|215] "°C"  ECU
 SG_ TSecCh1C m3 : 48|8@1+ (1,-40) [-40|215] "°C"  ECU
 SG_ TPriCh2C m2 : 48|8@1+ (1,-40) [-40|215] "°C"  ECU
 SG_ TPriCh1C m1 : 48|8@1+ (1,-40) [-40|215] "°C"  ECU
 SG_ V1v65Aux m0 : 48|8@1+ (0.01,0) [0|2.55] "V"  ECU
 SG_ VBuckAuxDriver m5 : 40|8@1+ (0.15,0) [0|38.25] "V"  ECU
 SG_ TSecCh2B m4 : 40|8@1+ (1,-40) [-40|215] "°C"  ECU
 SG_ TSecCh1B m3 : 40|8@1+ (1,-40) [-40|215] "°C"  ECU
 SG_ TPriCh2B m2 : 40|8@1+ (1,-40) [-40|215] "°C"  ECU
 SG_ TPriCh1B m1 : 40|8@1+ (1,-40) [-40|215] "°C"  ECU
 SG_ V3v3Aux m0 : 40|8@1+ (0.02,0) [0|5.1] "V"  ECU
 SG_ NMissedSyncPulseCount m12 : 32|16@1- (1,0) [0|65535] ""  ECU
 SG_ NChecksum m11 : 32|16@1+ (1,0) [0|65536] ""  ECU
 SG_ NSerial m10 : 32|32@1+ (1,0) [0|4294967296] ""  ECU
 SG_ NSettingsCrc m9 : 32|16@1+ (1,0) [0|65536] ""  ECU
 SG_ NBootloaderId m8 : 32|16@1+ (1,0) [0|65536] ""  ECU
 SG_ NConfigVersion m7 : 32|16@1+ (1,0) [0|65536] ""  ECU
 SG_ NOcpDcdcErrorFlags m6 : 32|16@1+ (1,0) [0|65536] ""  ECU
 SG_ TBuckAux m5 : 32|8@1+ (1,-40) [-40|215] "°C"  ECU
 SG_ TSecCh2A m4 : 32|8@1+ (1,-40) [-40|215] "°C"  ECU
 SG_ TSecCh1A m3 : 32|8@1+ (1,-40) [-40|215] "°C"  ECU
 SG_ TPriCh2A m2 : 32|8@1+ (1,-40) [-40|215] "°C"  ECU
 SG_ TPriCh1A m1 : 32|8@1+ (1,-40) [-40|215] "°C"  ECU
 SG_ VHvAux m0 : 32|8@1+ (0.15,0) [0|38.25] "V"  ECU
 SG_ NMultiplexer M : 24|4@1+ (1,0) [0|15] ""  ECU
 SG_ VSuppAux : 8|8@1+ (0.15,0) [0|38.25] "V"  ECU
 SG_ IBuckAux : 0|8@1+ (0.25,-30) [-30|33.75] "A"  ECU

BO_ 2147490691 BL7_IsoPortInternalValue: 6 DCDC
 SG_ IPortInternalAverage : 36|12@1+ (0.25,-500) [-500|523.75] "A"  ECU
 SG_ VPortInternalAverage : 24|12@1+ (1,0) [0|4095] "V"  ECU
 SG_ VPortInternalMax : 12|12@1+ (1,0) [0|4095] "V"  ECU
 SG_ VPortInternalMin : 0|12@1+ (1,0) [0|4095] "V"  ECU

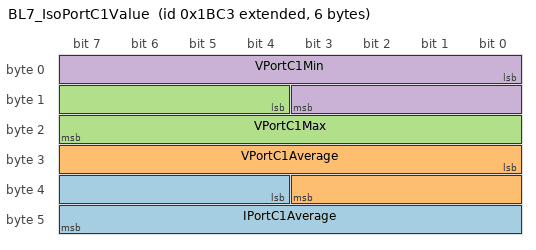
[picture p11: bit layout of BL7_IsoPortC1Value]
BO_ 2147490755 BL7_IsoPortC1Value: 6 DCDC
 SG_ IPortC1Average : 36|12@1+ (0.25,-500) [-500|523.75] "A"  ECU
 SG_ VPortC1Average : 24|12@1+ (1,0) [0|4095] "V"  ECU
 SG_ VPortC1Max : 12|12@1+ (1,0) [0|4095] "V"  ECU
 SG_ VPortC1Min : 0|12@1+ (1,0) [0|4095] "V"  ECU

CM_ BO_ 2147487814 "Global values";
CM_ SG_ 2147487814 NCellOtpErrorFlags "Indicates overtemperature protection of cells";
CM_ SG_ 2147487814 TCell3N2 "Temperature number 2 of cell 3";
CM_ SG_ 2147487814 VAuxCell4N2 "Auxiliary voltage number 2 of cell 4";
CM_ SG_ 2147487814 TCell3N1 "Temperature number 1 of cell 3";
CM_ SG_ 2147487814 TInternal "Global product temperature";
CM_ SG_ 2147487814 NBootloaderId "Version number of the bootloader program";
CM_ SG_ 2147487814 NApplicationId "Version number of the application program";
CM_ SG_ 2147487814 VAuxCell3N2 "Auxiliary voltage number 2 of cell 3";
CM_ SG_ 2147487814 NSyncNodeCount "Number of node on the network";
CM_ SG_ 2147487814 NSyncNodeRank "Rank of the node on the network";
CM_ SG_ 2147487814 NReleaseMode "Reserved";
CM_ SG_ 2147487814 TCell2N2 "Temperature number 2 of cell 2";
CM_ SG_ 2147487814 NCellVAuxErrorFlags "Indicates Auxiliary voltage error on cells";
CM_ SG_ 2147487814 VAuxCell4N1 "Auxiliary voltage number 1 of cell 4";
CM_ SG_ 2147487814 VAuxCell2N2 "Auxiliary voltage number 2 of cell 2";
CM_ SG_ 2147487814 VAuxCell4N3 "Auxiliary voltage number 3 of cell 4";
CM_ SG_ 2147487814 TCell4N3 "Temperature number 3 of cell 4";
CM_ SG_ 2147487814 VAux3Measured "Auxiliary voltage used for offset of current and voltage measurement";
CM_ SG_ 2147487814 TCell2N1 "Temperature number 1 of cell 2";
CM_ SG_ 2147487814 NConfigCrc "CRC of the CONFIG";
CM_ SG_ 2147487814 NSettingsCrc "CRC of the SETTINGS";
CM_ SG_ 2147487814 NSerial "Product Serial Number";
CM_ SG_ 2147487814 VAuxCell3N1 "Auxiliary voltage number 1 of cell 3";
CM_ SG_ 2147487814 VAuxCell1N2 "Auxiliary voltage number 2 of cell 1";
CM_ SG_ 2147487814 VAuxCell3N3 "Auxiliary voltage number 3 of cell 3";
CM_ SG_ 2147487814 TCell3N3 "Temperature number 3 of cell 3";
CM_ SG_ 2147487814 VAux2Measured "Auxiliary voltage 3V3 value";
CM_ SG_ 2147487814 TCell1N2 "Temperature number 2 of cell 1";
CM_ SG_ 2147487814 TCell4N2 "Temperature number 2 of cell 4";
CM_ SG_ 2147487814 NCellXcpErrorFlags "Indicates Xcp error on cells";
CM_ SG_ 2147487814 VAuxCell2N1 "Auxiliary voltage number 1 of cell 2";
CM_ SG_ 2147487814 VAuxCell2N3 "Auxiliary voltage number 3 of cell 2";
CM_ SG_ 2147487814 TCell2N3 "Temperature number 3 of cell 2";
CM_ SG_ 2147487814 VAux1Measured "Auxiliary voltage LV value";
CM_ SG_ 2147487814 TCell1N1 "Temperature number 1 of cell 1";
CM_ SG_ 2147487814 TCell4N1 "Temperature number 1 of cell 4";
CM_ SG_ 2147487814 NConfigVersion "Version number of the CONFIG";
CM_ SG_ 2147487814 NSettingsVersion "Version number of the SETTINGS";
CM_ SG_ 2147487814 NChecksum "Checksum of the application program";
CM_ SG_ 2147487814 NCellSwOcpErrorFlags "Indicates Sw overcurrent protection ";
CM_ SG_ 2147487814 VAuxCell1N1 "Auxiliary voltage number 1 of cell 1";
CM_ SG_ 2147487814 VAuxCell1N3 "Auxiliary voltage number 3 of cell 1";
CM_ SG_ 2147487814 TCell1N3 "Temperature number 3 of cell 1";
CM_ SG_ 2147487814 NMultiplexer "Multiplexer ID";
CM_ BO_ 2147487750 "Overal HVHV Status & Diagnostic";
CM_ SG_ 2147487750 BPath1AcModeActivated "Indicates that the Power Path 1 is working in AC mode";
CM_ SG_ 2147487750 BPath1AcUfpError "Power path 1 underfrequency fault";
CM_ SG_ 2147487750 BPath1AcOfpError "Power path 1 overfrequency fault";
CM_ SG_ 2147487750 NPath1AcFunctionMode "Power path 1 AC Function mode select";
CM_ SG_ 2147487750 BPath1FlgCapaError "Indicates a flying capa voltage error on power path 1";
CM_ SG_ 2147487750 BPath2FlgCapaError "Indicates a flying capa voltage error on power path 2";
CM_ SG_ 2147487750 BPath1ErrVAuxCell "Indicates a driver auxiliary voltage error on power path 1";
CM_ SG_ 2147487750 BPath2ErrVAuxCell "Indicates a driver auxiliary voltage error on power path 2";
CM_ SG_ 2147487750 IPath1Unbalance "Unbalanced current between cells on power path 1";
CM_ SG_ 2147487750 IPath2Unbalance "Unbalanced current between cells on power path 2";
CM_ SG_ 2147487750 BPath1RcpWarning "Warns the user of a potential reverse current problem";
CM_ SG_ 2147487750 BPath2RcpWarning "Warns the user of a potential reverse current problem";
CM_ SG_ 2147487750 BPath1OcpError "Power path 1 overcurrent fault";
CM_ SG_ 2147487750 BPath2OcpError "Power path 2 overcurrent fault";
CM_ SG_ 2147487750 BPath1OtpError "Power path 1 overtemperature fault";
CM_ SG_ 2147487750 BPath2OtpError "Power path 2 overtemperature fault";
CM_ SG_ 2147487750 BPath1SideBUvpError "Power path 1 side B undervoltage fault";
CM_ SG_ 2147487750 BPath2SideBUvpError "Power path 2 side B undervoltage fault";
CM_ SG_ 2147487750 BPath1SideAUvpError "Power path 1 side A undervoltage fault";
CM_ SG_ 2147487750 BPath2SideAUvpError "Power path 2 side A undervoltage fault";
CM_ SG_ 2147487750 BPath1SideBOvpError "Power path 1 side B overvoltage fault";
CM_ SG_ 2147487750 BPath2SideBOvpError "Power path 2 side B overvoltage fault";
CM_ SG_ 2147487750 BPath1SideAOvpError "Power path 1 side A overvoltage fault";
CM_ SG_ 2147487750 BPath2SideAOvpError "Power path 2 side A overvoltage fault";
CM_ SG_ 2147487750 BPath1Requested "Indicates that the power path 1 start command has been received";
CM_ SG_ 2147487750 BPath2Requested "Indicates that the power path 2 start command has been received";
CM_ SG_ 2147487750 NPath1CurrentSideSelected "Point of current limitation of Power path 1";
CM_ SG_ 2147487750 NPath2CurrentSideSelected "Point of current limitation of Power path 2";
CM_ SG_ 2147487750 NPath1VoltageSideSelected "Point of voltage regulation of Power path 1";
CM_ SG_ 2147487750 NPath2VoltageSideSelected "Point of voltage regulation of Power path 2";
CM_ SG_ 2147487750 NPath1State "Indicates the power path 1 status";
CM_ SG_ 2147487750 NPath2State "Indicates the power path 2 status";
CM_ SG_ 2147487750 NMultiplexer "Multiplexer ID";
CM_ SG_ 2147487750 BXcpError "Indicates a power switches command?s integrity fault";
CM_ SG_ 2147487750 NCellHwErrorFlags "Indicates HW errors triggered on CELL";
CM_ SG_ 2147487750 BSyncInputSignal "Indicates if a correct synchronization signal is detected on the input synchronization pin";
CM_ SG_ 2147487750 BSyncRequested "Indicates the synchronization command has been received";
CM_ SG_ 2147487750 BInternalTemperatureError "Indicates an overtemperature error on the internal temperature";
CM_ SG_ 2147487750 BConfigSettingsError "Indicates that the Config and/or Settings data is corrupted";
CM_ SG_ 2147487750 BAuxSupplyError "Indicates a fault on one of the auxiliary power supplies";
CM_ SG_ 2147487750 BCanTimeoutError "Indicates an error on the CAN bus";
CM_ SG_ 2147487750 BAuxIsoEnabled "Indicates that isolated auxiliary supplies are activated";
CM_ SG_ 2147487750 BSafetyDischargeEnabled "Indicates the safety discharge is activated";
CM_ SG_ 2147487750 BFaultSignal "Indicates the signal Fault status";
CM_ SG_ 2147487750 BEnableSignal "Indicates the external hardware ENABLE status";
CM_ SG_ 2147487750 BSafetyDischargeStatus "Indicates the safety discharge status";
CM_ SG_ 2147487750 BSyncStatus "Indicates the synchronization has been done successfully";
CM_ SG_ 2147487750 BReadConfigAndSettingsRequested "Indicates that the Read config and settings command has been received";
CM_ SG_ 2147487750 BSwResetModuleRequested "Indicates that the Software reset command has been received";
CM_ SG_ 2147487750 BSafetyDischargeRequested "Indicates that the safety discharge command has been received";
CM_ SG_ 2147487750 NModuleState "Indicates the overall module status";
CM_ BO_ 2147487753 "Overal HVHV Status & Diagnostic";
CM_ SG_ 2147487753 BPath1AcModeActivated "Indicates that the Power Path 1 is working in AC mode";
CM_ SG_ 2147487753 BPath1AcUfpError "Power path 1 underfrequency fault";
CM_ SG_ 2147487753 BPath1AcOfpError "Power path 1 overfrequency fault";
CM_ SG_ 2147487753 NPath1AcFunctionMode "Power path 1 AC Function mode select";
CM_ SG_ 2147487753 BPath1FlgCapaError "Indicates a flying capa voltage error on power path 1";
CM_ SG_ 2147487753 BPath2FlgCapaError "Indicates a flying capa voltage error on power path 2";
CM_ SG_ 2147487753 BPath1ErrVAuxCell "Indicates a driver auxiliary voltage error on power path 1";
CM_ SG_ 2147487753 BPath2ErrVAuxCell "Indicates a driver auxiliary voltage error on power path 2";
CM_ SG_ 2147487753 IPath1Unbalance "Unbalanced current between cells on power path 1";
CM_ SG_ 2147487753 IPath2Unbalance "Unbalanced current between cells on power path 2";
CM_ SG_ 2147487753 BPath1RcpWarning "Warns the user of a potential reverse current problem";
CM_ SG_ 2147487753 BPath2RcpWarning "Warns the user of a potential reverse current problem";
CM_ SG_ 2147487753 BPath1OcpError "Power path 1 overcurrent fault";
CM_ SG_ 2147487753 BPath2OcpError "Power path 2 overcurrent fault";
CM_ SG_ 2147487753 BPath1OtpError "Power path 1 overtemperature fault";
CM_ SG_ 2147487753 BPath2OtpError "Power path 2 overtemperature fault";
CM_ SG_ 2147487753 BPath1SideBUvpError "Power path 1 side B undervoltage fault";
CM_ SG_ 2147487753 BPath2SideBUvpError "Power path 2 side B undervoltage fault";
CM_ SG_ 2147487753 BPath1SideAUvpError "Power path 1 side A undervoltage fault";
CM_ SG_ 2147487753 BPath2SideAUvpError "Power path 2 side A undervoltage fault";
CM_ SG_ 2147487753 BPath1SideBOvpError "Power path 1 side B overvoltage fault";
CM_ SG_ 2147487753 BPath2SideBOvpError "Power path 2 side B overvoltage fault";
CM_ SG_ 2147487753 BPath1SideAOvpError "Power path 1 side A overvoltage fault";
CM_ SG_ 2147487753 BPath2SideAOvpError "Power path 2 side A overvoltage fault";
CM_ SG_ 2147487753 BPath1Requested "Indicates that the power path 1 start command has been received";
CM_ SG_ 2147487753 BPath2Requested "Indicates that the power path 2 start command has been received";
CM_ SG_ 2147487753 NPath1CurrentSideSelected "Point of current limitation of Power path 1";
CM_ SG_ 2147487753 NPath2CurrentSideSelected "Point of current limitation of Power path 2";
CM_ SG_ 2147487753 NPath1VoltageSideSelected "Point of voltage regulation of Power path 1";
CM_ SG_ 2147487753 NPath2VoltageSideSelected "Point of voltage regulation of Power path 2";
CM_ SG_ 2147487753 NPath1State "Indicates the power path 1 status";
CM_ SG_ 2147487753 NPath2State "Indicates the power path 2 status";
CM_ SG_ 2147487753 NMultiplexer "Multiplexer ID";
CM_ SG_ 2147487753 BXcpError "Indicates a power switches command?s integrity fault";
CM_ SG_ 2147487753 NCellHwErrorFlags "Indicates HW errors triggered on CELL";
CM_ SG_ 2147487753 BSyncInputSignal "Indicates if a correct synchronization signal is detected on the input synchronization pin";
CM_ SG_ 2147487753 BSyncRequested "Indicates the synchronization command has been received";
CM_ SG_ 2147487753 BInternalTemperatureError "Indicates an overtemperature error on the internal temperature";
CM_ SG_ 2147487753 BConfigSettingsError "Indicates that the Config and/or Settings data is corrupted";
CM_ SG_ 2147487753 BAuxSupplyError "Indicates a fault on one of the auxiliary power supplies";
CM_ SG_ 2147487753 BCanTimeoutError "Indicates an error on the CAN bus";
CM_ SG_ 2147487753 BAuxIsoEnabled "Indicates that isolated auxiliary supplies are activated";
CM_ SG_ 2147487753 BSafetyDischargeEnabled "Indicates the safety discharge is activated";
CM_ SG_ 2147487753 BFaultSignal "Indicates the signal Fault status";
CM_ SG_ 2147487753 BEnableSignal "Indicates the external hardware ENABLE status";
CM_ SG_ 2147487753 BSafetyDischargeStatus "Indicates the safety discharge status";
CM_ SG_ 2147487753 BSyncStatus "Indicates the synchronization has been done successfully";
CM_ SG_ 2147487753 BReadConfigAndSettingsRequested "Indicates that the Read config and settings command has been received";
CM_ SG_ 2147487753 BSwResetModuleRequested "Indicates that the Software reset command has been received";
CM_ SG_ 2147487753 BSafetyDischargeRequested "Indicates that the safety discharge command has been received";
CM_ SG_ 2147487753 NModuleState "Indicates the overall module status";
CM_ BO_ 2147489417 "Response message giving the present values of the setpoints ";
CM_ SG_ 2147489417 IqPath1AcLimitLo "Power path 1 AC Iq lower limitation";
CM_ SG_ 2147489417 IqPath1AcLimitHi "Power path 1 AC Iq upper limitation";
CM_ SG_ 2147489417 PPath2LimitLo "Power path 2 power lower limitation";
CM_ SG_ 2147489417 IqPath1AcSetpoint "Power path 1 AC Iq setpoint";
CM_ SG_ 2147489417 IdPath1AcLimitLo "Power path 1 AC Id lower limitation";
CM_ SG_ 2147489417 IdPath1AcSetpoint "Power path 1 AC Id setpoint";
CM_ SG_ 2147489417 IdPath1AcLimitHi "Power path 1 AC Id upper limitation";
CM_ SG_ 2147489417 PPath2LimitHi "Power path 2 power upper limitation";
CM_ SG_ 2147489417 NMultiplexer "Multiplexer ID:  the power path's number of the setpoints";
CM_ BO_ 2147489353 "Response message giving the present values of the setpoints ";
CM_ SG_ 2147489353 NPath1AcFunctionMode "Power path 1 AC Function mode select";
CM_ SG_ 2147489353 NPath2CurrentSideSelected "Point of current limitation of Power path 2";
CM_ SG_ 2147489353 NPath2VoltageSideSelected "Point of voltage regulation of Power path 2";
CM_ SG_ 2147489353 NPath1AcFrequencySetpoint "Power path 1 AC frequency setpoint";
CM_ SG_ 2147489353 IPath2LimitLo "Power path 2 current lower limitation";
CM_ SG_ 2147489353 VqPath1AcSetpoint "Power path 1 AC Vq setpoint";
CM_ SG_ 2147489353 VdPath1AcSetpoint "Power path 1 AC Vd setpoint";
CM_ SG_ 2147489353 IPath2LimitHi "Power path 2 current upper limitation";
CM_ SG_ 2147489353 VDcPath1AcSetpoint "Power path 1 AC Vdc setpoint";
CM_ SG_ 2147489353 VPath2Setpoint "Power path 2 voltage setpoint";
CM_ SG_ 2147489353 NMultiplexer "Multiplexer ID:  the power path's number of the setpoints";
CM_ BO_ 2147488777 "Values of port B1";
CM_ SG_ 2147488777 NPortB1OverloadCount "Counter indicating the number of times an overload is detected on port B1";
CM_ SG_ 2147488777 IPortB1Average "Average value of the port B1 current";
CM_ SG_ 2147488777 VPortB1Average "Average value of the port B1 voltage";
CM_ SG_ 2147488777 VPortB1Max "Maximum value of the  port B1 voltage seen since the last message sent";
CM_ SG_ 2147488777 VPortB1Min "Minimum value of the port B1 voltage seen since the last message sent";
CM_ BO_ 2147487881 "Values of port A1 ";
CM_ SG_ 2147487881 NMultiplexer "Multiplexer ID";
CM_ SG_ 2147487881 IqPhAPortA1RMS "RMS value of the Iq on phase A";
CM_ SG_ 2147487881 IqPortA1RMS "RMS value of the Iq on Port";
CM_ SG_ 2147487881 NFrequencyPortA1 "Frequency of the AC network";
CM_ SG_ 2147487881 IqPhCPortA1RMS "RMS value of the Iq on phase C";
CM_ SG_ 2147487881 IdPhAPortA1RMS "RMS value of the Id on phase A";
CM_ SG_ 2147487881 IdPortA1RMS "RMS value of the Id on Port";
CM_ SG_ 2147487881 VphCPortA1Peak "Peak value of the voltage on phase C";
CM_ SG_ 2147487881 IdPhCPortA1RMS "RMS value of the Id on phase C";
CM_ SG_ 2147487881 IphCPortA1Peak "Peak value of the current on phase C";
CM_ SG_ 2147487881 VqPortA1RMS "RMS value of the Vq";
CM_ SG_ 2147487881 VphBPortA1Peak "Peak value of the voltage on phase B";
CM_ SG_ 2147487881 IqPhBPortA1RMS "RMS value of the Iq on phase B";
CM_ SG_ 2147487881 IphBPortA1Peak "Peak value of the current on phase B";
CM_ SG_ 2147487881 VdPortA1RMS "RMS value of the Vd";
CM_ SG_ 2147487881 VphAPortA1Peak "Peak value of the voltage on phase A";
CM_ SG_ 2147487881 IphAPortA1Peak "Peak value of the current on phase A";
CM_ SG_ 2147487881 IdPhBPortA1RMS "RMS value of the Id on phase B";
CM_ BO_ 2147487945 "Values of port A2 ";
CM_ SG_ 2147487945 NMultiplexer "Multiplexer ID";
CM_ SG_ 2147487945 NPortA2OverloadCount "Counter indicating the number of times an overload is detected on port A2";
CM_ SG_ 2147487945 IPortA2Average "Average value of the port A2 current";
CM_ SG_ 2147487945 VPortA2Average "Average value of the port A2 voltage";
CM_ SG_ 2147487945 VPortA2Max "Maximum value of the  port A2 voltage seen since the last message sent";
CM_ SG_ 2147487945 VPortA2Min "Minimum value of the port A2 voltage seen since the last message sent";
CM_ BO_ 2147488393 "Values of internal parameters on PowerPath1";
CM_ SG_ 2147488393 VPath1FlgCapaLvl2Max "Maximum value of the flying capa level 2 voltage of the power path 1 seen since the last message sent";
CM_ SG_ 2147488393 VPath1FlgCapaLvl2Min "Minimum value of the flying capa level 2 voltage of the power path 1 seen since the last message sent";
CM_ SG_ 2147488393 VPath1FlgCapaLvl1Max "Maximum value of the flying capa level 1 voltage of the power path 1 seen since the last message sent";
CM_ SG_ 2147488393 VPath1FlgCapaLvl1Min "Minimum value of the flying capa level 1 voltage of the power path 1 seen since the last message sent";
CM_ BO_ 2147488457 "Values of internal parameters on PowerPath2";
CM_ SG_ 2147488457 VPath2FlgCapaLvl2Max "Maximum value of the flying capa level 2 voltage of the power path 2 seen since the last message sent";
CM_ SG_ 2147488457 VPath2FlgCapaLvl2Min "Minimum value of the flying capa level 2 voltage of the power path 2 seen since the last message sent";
CM_ SG_ 2147488457 VPath2FlgCapaLvl1Max "Maximum value of the flying capa level 1 voltage of the power path 2 seen since the last message sent";
CM_ SG_ 2147488457 VPath2FlgCapaLvl1Min "Minimum value of the flying capa level 1 voltage of the power path 2 seen since the last message sent";
CM_ BO_ 2147487817 "Global values";
CM_ SG_ 2147487817 NCellOtpErrorFlags "Indicates overtemperature protection of cells";
CM_ SG_ 2147487817 TCell3N2 "Temperature number 2 of cell 3";
CM_ SG_ 2147487817 VAuxCell4N2 "Auxiliary voltage number 2 of cell 4";
CM_ SG_ 2147487817 TCell3N1 "Temperature number 1 of cell 3";
CM_ SG_ 2147487817 TInternal "Global product temperature";
CM_ SG_ 2147487817 NBootloaderId "Version number of the bootloader program";
CM_ SG_ 2147487817 NApplicationId "Version number of the application program";
CM_ SG_ 2147487817 VAuxCell3N2 "Auxiliary voltage number 2 of cell 3";
CM_ SG_ 2147487817 NSyncNodeCount "Number of node on the network";
CM_ SG_ 2147487817 NSyncNodeRank "Rank of the node on the network";
CM_ SG_ 2147487817 NReleaseMode "Reserved";
CM_ SG_ 2147487817 TCell2N2 "Temperature number 2 of cell 2";
CM_ SG_ 2147487817 NCellVAuxErrorFlags "Indicates Auxiliary voltage error on cells";
CM_ SG_ 2147487817 VAuxCell4N1 "Auxiliary voltage number 1 of cell 4";
CM_ SG_ 2147487817 VAuxCell2N2 "Auxiliary voltage number 2 of cell 2";
CM_ SG_ 2147487817 VAuxCell4N3 "Auxiliary voltage number 3 of cell 4";
CM_ SG_ 2147487817 TCell4N3 "Temperature number 3 of cell 4";
CM_ SG_ 2147487817 VAux3Measured "Auxiliary voltage used for offset of current and voltage measurement";
CM_ SG_ 2147487817 TCell2N1 "Temperature number 1 of cell 2";
CM_ SG_ 2147487817 NConfigCrc "CRC of the CONFIG";
CM_ SG_ 2147487817 NSettingsCrc "CRC of the SETTINGS";
CM_ SG_ 2147487817 NSerial "Product Serial Number";
CM_ SG_ 2147487817 VAuxCell3N1 "Auxiliary voltage number 1 of cell 3";
CM_ SG_ 2147487817 VAuxCell1N2 "Auxiliary voltage number 2 of cell 1";
CM_ SG_ 2147487817 VAuxCell3N3 "Auxiliary voltage number 3 of cell 3";
CM_ SG_ 2147487817 TCell3N3 "Temperature number 3 of cell 3";
CM_ SG_ 2147487817 VAux2Measured "Auxiliary voltage 3V3 value";
CM_ SG_ 2147487817 TCell1N2 "Temperature number 2 of cell 1";
CM_ SG_ 2147487817 TCell4N2 "Temperature number 2 of cell 4";
CM_ SG_ 2147487817 NCellXcpErrorFlags "Indicates Xcp error on cells";
CM_ SG_ 2147487817 VAuxCell2N1 "Auxiliary voltage number 1 of cell 2";
CM_ SG_ 2147487817 VAuxCell2N3 "Auxiliary voltage number 3 of cell 2";
CM_ SG_ 2147487817 TCell2N3 "Temperature number 3 of cell 2";
CM_ SG_ 2147487817 VAux1Measured "Auxiliary voltage LV value";
CM_ SG_ 2147487817 TCell1N1 "Temperature number 1 of cell 1";
CM_ SG_ 2147487817 TCell4N1 "Temperature number 1 of cell 4";
CM_ SG_ 2147487817 NConfigVersion "Version number of the CONFIG";
CM_ SG_ 2147487817 NSettingsVersion "Version number of the SETTINGS";
CM_ SG_ 2147487817 NChecksum "Checksum of the application program";
CM_ SG_ 2147487817 NCellSwOcpErrorFlags "Indicates Sw overcurrent protection ";
CM_ SG_ 2147487817 VAuxCell1N1 "Auxiliary voltage number 1 of cell 1";
CM_ SG_ 2147487817 VAuxCell1N3 "Auxiliary voltage number 3 of cell 1";
CM_ SG_ 2147487817 TCell1N3 "Temperature number 3 of cell 1";
CM_ SG_ 2147487817 NMultiplexer "Multiplexer ID";
CM_ BO_ 2147489481 "Value of all parameters of the configuration and settings";
CM_ SG_ 2147489481 NParameterValue "Value of the 16bits word";
CM_ SG_ 2147489481 NParameterIndex "Index at which the word is read in the selected zone";
CM_ SG_ 2147489481 NReadZoneSelect "Zone in which to read the parameters";
CM_ BO_ 2147489416 "Response message giving the present values of the setpoints ";
CM_ SG_ 2147489416 IqPath1AcLimitLo "Power path 1 AC Iq lower limitation";
CM_ SG_ 2147489416 IqPath1AcLimitHi "Power path 1 AC Iq upper limitation";
CM_ SG_ 2147489416 PPath2LimitLo "Power path 2 power lower limitation";
CM_ SG_ 2147489416 IqPath1AcSetpoint "Power path 1 AC Iq setpoint";
CM_ SG_ 2147489416 IdPath1AcLimitLo "Power path 1 AC Id lower limitation";
CM_ SG_ 2147489416 IdPath1AcSetpoint "Power path 1 AC Id setpoint";
CM_ SG_ 2147489416 IdPath1AcLimitHi "Power path 1 AC Id upper limitation";
CM_ SG_ 2147489416 PPath2LimitHi "Power path 2 power upper limitation";
CM_ SG_ 2147489416 NMultiplexer "Multiplexer ID:  the power path's number of the setpoints";
CM_ BO_ 2147489352 "Response message giving the present values of the setpoints ";
CM_ SG_ 2147489352 NPath1AcFunctionMode "Power path 1 AC Function mode select";
CM_ SG_ 2147489352 NPath2CurrentSideSelected "Point of current limitation of Power path 2";
CM_ SG_ 2147489352 NPath2VoltageSideSelected "Point of voltage regulation of Power path 2";
CM_ SG_ 2147489352 NPath1AcFrequencySetpoint "Power path 1 AC frequency setpoint";
CM_ SG_ 2147489352 IPath2LimitLo "Power path 2 current lower limitation";
CM_ SG_ 2147489352 VqPath1AcSetpoint "Power path 1 AC Vq setpoint";
CM_ SG_ 2147489352 VdPath1AcSetpoint "Power path 1 AC Vd setpoint";
CM_ SG_ 2147489352 IPath2LimitHi "Power path 2 current upper limitation";
CM_ SG_ 2147489352 VDcPath1AcSetpoint "Power path 1 AC Vdc setpoint";
CM_ SG_ 2147489352 VPath2Setpoint "Power path 2 voltage setpoint";
CM_ SG_ 2147489352 NMultiplexer "Multiplexer ID:  the power path's number of the setpoints";
CM_ BO_ 2147488392 "Values of internal parameters on PowerPath1";
CM_ SG_ 2147488392 VPath1FlgCapaLvl2Max "Maximum value of the flying capa level 2 voltage of the power path 1 seen since the last message sent";
CM_ SG_ 2147488392 VPath1FlgCapaLvl2Min "Minimum value of the flying capa level 2 voltage of the power path 1 seen since the last message sent";
CM_ SG_ 2147488392 VPath1FlgCapaLvl1Max "Maximum value of the flying capa level 1 voltage of the power path 1 seen since the last message sent";
CM_ SG_ 2147488392 VPath1FlgCapaLvl1Min "Minimum value of the flying capa level 1 voltage of the power path 1 seen since the last message sent";
CM_ BO_ 2147488456 "Values of internal parameters on PowerPath2";
CM_ SG_ 2147488456 VPath2FlgCapaLvl2Max "Maximum value of the flying capa level 2 voltage of the power path 2 seen since the last message sent";
CM_ SG_ 2147488456 VPath2FlgCapaLvl2Min "Minimum value of the flying capa level 2 voltage of the power path 2 seen since the last message sent";
CM_ SG_ 2147488456 VPath2FlgCapaLvl1Max "Maximum value of the flying capa level 1 voltage of the power path 2 seen since the last message sent";
CM_ SG_ 2147488456 VPath2FlgCapaLvl1Min "Minimum value of the flying capa level 1 voltage of the power path 2 seen since the last message sent";
CM_ BO_ 2147488776 "Values of port B1";
CM_ SG_ 2147488776 NPortB1OverloadCount "Counter indicating the number of times an overload is detected on port B1";
CM_ SG_ 2147488776 IPortB1Average "Average value of the port B1 current";
CM_ SG_ 2147488776 VPortB1Average "Average value of the port B1 voltage";
CM_ SG_ 2147488776 VPortB1Max "Maximum value of the  port B1 voltage seen since the last message sent";
CM_ SG_ 2147488776 VPortB1Min "Minimum value of the port B1 voltage seen since the last message sent";
CM_ BO_ 2147487880 "Values of port A1 ";
CM_ SG_ 2147487880 NMultiplexer "Multiplexer ID";
CM_ SG_ 2147487880 IqPhAPortA1RMS "RMS value of the Iq on phase A";
CM_ SG_ 2147487880 IqPortA1RMS "RMS value of the Iq on Port";
CM_ SG_ 2147487880 NFrequencyPortA1 "Frequency of the AC network";
CM_ SG_ 2147487880 IqPhCPortA1RMS "RMS value of the Iq on phase C";
CM_ SG_ 2147487880 IdPhAPortA1RMS "RMS value of the Id on phase A";
CM_ SG_ 2147487880 IdPortA1RMS "RMS value of the Id on Port";
CM_ SG_ 2147487880 VphCPortA1Peak "Peak value of the voltage on phase C";
CM_ SG_ 2147487880 IdPhCPortA1RMS "RMS value of the Id on phase C";
CM_ SG_ 2147487880 IphCPortA1Peak "Peak value of the current on phase C";
CM_ SG_ 2147487880 VqPortA1RMS "RMS value of the Vq";
CM_ SG_ 2147487880 VphBPortA1Peak "Peak value of the voltage on phase B";
CM_ SG_ 2147487880 IqPhBPortA1RMS "RMS value of the Iq on phase B";
CM_ SG_ 2147487880 IphBPortA1Peak "Peak value of the current on phase B";
CM_ SG_ 2147487880 VdPortA1RMS "RMS value of the Vd";
CM_ SG_ 2147487880 VphAPortA1Peak "Peak value of the voltage on phase A";
CM_ SG_ 2147487880 IphAPortA1Peak "Peak value of the current on phase A";
CM_ SG_ 2147487880 IdPhBPortA1RMS "RMS value of the Id on phase B";
CM_ BO_ 2147487944 "Values of port A2 ";
CM_ SG_ 2147487944 NMultiplexer "Multiplexer ID";
CM_ SG_ 2147487944 NPortA2OverloadCount "Counter indicating the number of times an overload is detected on port A2";
CM_ SG_ 2147487944 IPortA2Average "Average value of the port A2 current";
CM_ SG_ 2147487944 VPortA2Average "Average value of the port A2 voltage";
CM_ SG_ 2147487944 VPortA2Max "Maximum value of the  port A2 voltage seen since the last message sent";
CM_ SG_ 2147487944 VPortA2Min "Minimum value of the port A2 voltage seen since the last message sent";
CM_ BO_ 2147489480 "Value of all parameters of the configuration and settings";
CM_ SG_ 2147489480 NParameterValue "Value of the 16bits word";
CM_ SG_ 2147489480 NParameterIndex "Index at which the word is read in the selected zone";
CM_ SG_ 2147489480 NReadZoneSelect "Zone in which to read the parameters";
CM_ BO_ 2147487816 "Global values";
CM_ SG_ 2147487816 NCellOtpErrorFlags "Indicates overtemperature protection of cells";
CM_ SG_ 2147487816 TCell3N2 "Temperature number 2 of cell 3";
CM_ SG_ 2147487816 VAuxCell4N2 "Auxiliary voltage number 2 of cell 4";
CM_ SG_ 2147487816 TCell3N1 "Temperature number 1 of cell 3";
CM_ SG_ 2147487816 TInternal "Global product temperature";
CM_ SG_ 2147487816 NBootloaderId "Version number of the bootloader program";
CM_ SG_ 2147487816 NApplicationId "Version number of the application program";
CM_ SG_ 2147487816 VAuxCell3N2 "Auxiliary voltage number 2 of cell 3";
CM_ SG_ 2147487816 NSyncNodeCount "Number of node on the network";
CM_ SG_ 2147487816 NSyncNodeRank "Rank of the node on the network";
CM_ SG_ 2147487816 NReleaseMode "Reserved";
CM_ SG_ 2147487816 TCell2N2 "Temperature number 2 of cell 2";
CM_ SG_ 2147487816 NCellVAuxErrorFlags "Indicates Auxiliary voltage error on cells";
CM_ SG_ 2147487816 VAuxCell4N1 "Auxiliary voltage number 1 of cell 4";
CM_ SG_ 2147487816 VAuxCell2N2 "Auxiliary voltage number 2 of cell 2";
CM_ SG_ 2147487816 VAuxCell4N3 "Auxiliary voltage number 3 of cell 4";
CM_ SG_ 2147487816 TCell4N3 "Temperature number 3 of cell 4";
CM_ SG_ 2147487816 VAux3Measured "Auxiliary voltage used for offset of current and voltage measurement";
CM_ SG_ 2147487816 TCell2N1 "Temperature number 1 of cell 2";
CM_ SG_ 2147487816 NConfigCrc "CRC of the CONFIG";
CM_ SG_ 2147487816 NSettingsCrc "CRC of the SETTINGS";
CM_ SG_ 2147487816 NSerial "Product Serial Number";
CM_ SG_ 2147487816 VAuxCell3N1 "Auxiliary voltage number 1 of cell 3";
CM_ SG_ 2147487816 VAuxCell1N2 "Auxiliary voltage number 2 of cell 1";
CM_ SG_ 2147487816 VAuxCell3N3 "Auxiliary voltage number 3 of cell 3";
CM_ SG_ 2147487816 TCell3N3 "Temperature number 3 of cell 3";
CM_ SG_ 2147487816 VAux2Measured "Auxiliary voltage 3V3 value";
CM_ SG_ 2147487816 TCell1N2 "Temperature number 2 of cell 1";
CM_ SG_ 2147487816 TCell4N2 "Temperature number 2 of cell 4";
CM_ SG_ 2147487816 NCellXcpErrorFlags "Indicates Xcp error on cells";
CM_ SG_ 2147487816 VAuxCell2N1 "Auxiliary voltage number 1 of cell 2";
CM_ SG_ 2147487816 VAuxCell2N3 "Auxiliary voltage number 3 of cell 2";
CM_ SG_ 2147487816 TCell2N3 "Temperature number 3 of cell 2";
CM_ SG_ 2147487816 VAux1Measured "Auxiliary voltage LV value";
CM_ SG_ 2147487816 TCell1N1 "Temperature number 1 of cell 1";
CM_ SG_ 2147487816 TCell4N1 "Temperature number 1 of cell 4";
CM_ SG_ 2147487816 NConfigVersion "Version number of the CONFIG";
CM_ SG_ 2147487816 NSettingsVersion "Version number of the SETTINGS";
CM_ SG_ 2147487816 NChecksum "Checksum of the application program";
CM_ SG_ 2147487816 NCellSwOcpErrorFlags "Indicates Sw overcurrent protection ";
CM_ SG_ 2147487816 VAuxCell1N1 "Auxiliary voltage number 1 of cell 1";
CM_ SG_ 2147487816 VAuxCell1N3 "Auxiliary voltage number 3 of cell 1";
CM_ SG_ 2147487816 TCell1N3 "Temperature number 3 of cell 1";
CM_ SG_ 2147487816 NMultiplexer "Multiplexer ID";
CM_ BO_ 2147487752 "Overal HVHV Status & Diagnostic";
CM_ SG_ 2147487752 BPath1AcModeActivated "Indicates that the Power Path 1 is working in AC mode";
CM_ SG_ 2147487752 BPath1AcUfpError "Power path 1 underfrequency fault";
CM_ SG_ 2147487752 BPath1AcOfpError "Power path 1 overfrequency fault";
CM_ SG_ 2147487752 NPath1AcFunctionMode "Power path 1 AC Function mode select";
CM_ SG_ 2147487752 BPath1FlgCapaError "Indicates a flying capa voltage error on power path 1";
CM_ SG_ 2147487752 BPath2FlgCapaError "Indicates a flying capa voltage error on power path 2";
CM_ SG_ 2147487752 BPath1ErrVAuxCell "Indicates a driver auxiliary voltage error on power path 1";
CM_ SG_ 2147487752 BPath2ErrVAuxCell "Indicates a driver auxiliary voltage error on power path 2";
CM_ SG_ 2147487752 IPath1Unbalance "Unbalanced current between cells on power path 1";
CM_ SG_ 2147487752 IPath2Unbalance "Unbalanced current between cells on power path 2";
CM_ SG_ 2147487752 BPath1RcpWarning "Warns the user of a potential reverse current problem";
CM_ SG_ 2147487752 BPath2RcpWarning "Warns the user of a potential reverse current problem";
CM_ SG_ 2147487752 BPath1OcpError "Power path 1 overcurrent fault";
CM_ SG_ 2147487752 BPath2OcpError "Power path 2 overcurrent fault";
CM_ SG_ 2147487752 BPath1OtpError "Power path 1 overtemperature fault";
CM_ SG_ 2147487752 BPath2OtpError "Power path 2 overtemperature fault";
CM_ SG_ 2147487752 BPath1SideBUvpError "Power path 1 side B undervoltage fault";
CM_ SG_ 2147487752 BPath2SideBUvpError "Power path 2 side B undervoltage fault";
CM_ SG_ 2147487752 BPath1SideAUvpError "Power path 1 side A undervoltage fault";
CM_ SG_ 2147487752 BPath2SideAUvpError "Power path 2 side A undervoltage fault";
CM_ SG_ 2147487752 BPath1SideBOvpError "Power path 1 side B overvoltage fault";
CM_ SG_ 2147487752 BPath2SideBOvpError "Power path 2 side B overvoltage fault";
CM_ SG_ 2147487752 BPath1SideAOvpError "Power path 1 side A overvoltage fault";
CM_ SG_ 2147487752 BPath2SideAOvpError "Power path 2 side A overvoltage fault";
CM_ SG_ 2147487752 BPath1Requested "Indicates that the power path 1 start command has been received";
CM_ SG_ 2147487752 BPath2Requested "Indicates that the power path 2 start command has been received";
CM_ SG_ 2147487752 NPath1CurrentSideSelected "Point of current limitation of Power path 1";
CM_ SG_ 2147487752 NPath2CurrentSideSelected "Point of current limitation of Power path 2";
CM_ SG_ 2147487752 NPath1VoltageSideSelected "Point of voltage regulation of Power path 1";
CM_ SG_ 2147487752 NPath2VoltageSideSelected "Point of voltage regulation of Power path 2";
CM_ SG_ 2147487752 NPath1State "Indicates the power path 1 status";
CM_ SG_ 2147487752 NPath2State "Indicates the power path 2 status";
CM_ SG_ 2147487752 NMultiplexer "Multiplexer ID";
CM_ SG_ 2147487752 BXcpError "Indicates a power switches command?s integrity fault";
CM_ SG_ 2147487752 NCellHwErrorFlags "Indicates HW errors triggered on CELL";
CM_ SG_ 2147487752 BSyncInputSignal "Indicates if a correct synchronization signal is detected on the input synchronization pin";
CM_ SG_ 2147487752 BSyncRequested "Indicates the synchronization command has been received";
CM_ SG_ 2147487752 BInternalTemperatureError "Indicates an overtemperature error on the internal temperature";
CM_ SG_ 2147487752 BConfigSettingsError "Indicates that the Config and/or Settings data is corrupted";
CM_ SG_ 2147487752 BAuxSupplyError "Indicates a fault on one of the auxiliary power supplies";
CM_ SG_ 2147487752 BCanTimeoutError "Indicates an error on the CAN bus";
CM_ SG_ 2147487752 BAuxIsoEnabled "Indicates that isolated auxiliary supplies are activated";
CM_ SG_ 2147487752 BSafetyDischargeEnabled "Indicates the safety discharge is activated";
CM_ SG_ 2147487752 BFaultSignal "Indicates the signal Fault status";
CM_ SG_ 2147487752 BEnableSignal "Indicates the external hardware ENABLE status";
CM_ SG_ 2147487752 BSafetyDischargeStatus "Indicates the safety discharge status";
CM_ SG_ 2147487752 BSyncStatus "Indicates the synchronization has been done successfully";
CM_ SG_ 2147487752 BReadConfigAndSettingsRequested "Indicates that the Read config and settings command has been received";
CM_ SG_ 2147487752 BSwResetModuleRequested "Indicates that the Software reset command has been received";
CM_ SG_ 2147487752 BSafetyDischargeRequested "Indicates that the safety discharge command has been received";
CM_ SG_ 2147487752 NModuleState "Indicates the overall module status";
CM_ BO_ 2147491393 "Response message giving the present values of the setpoints";
CM_ SG_ 2147491393 NPath1CurrentSideSelected "Point of current limitation of Power path 1";
CM_ SG_ 2147491393 NPath1VoltageSideSelected "Point of voltage regulation of Power path 1";
CM_ SG_ 2147491393 IPath1LimitLo "Power path 1 current lower limitation";
CM_ SG_ 2147491393 IPath1LimitHi "Power path 1 current upper limitation";
CM_ SG_ 2147491393 VPath1Setpoint "Power path 1 voltage setpoint";
CM_ SG_ 2147491393 NMultiplexer "Multiplexer ID: the power path's number of the setpoints";
CM_ BO_ 2147491457 "Response message giving the present values of the setpoints";
CM_ SG_ 2147491457 PPath1LimitLo "Power path 1 power lower limitation";
CM_ SG_ 2147491457 PPath1LimitHi "Power path 1 power upper limitation";
CM_ SG_ 2147491457 NMultiplexer "Multiplexer ID:  the power path's number of the setpoints";
CM_ BO_ 2147490817 "Values of port B1";
CM_ SG_ 2147490817 NPortB1OverloadCount "Counter indicating the number of times an overload is detected on port B1";
CM_ SG_ 2147490817 IPortB1Average "Average value of the port B1 current";
CM_ SG_ 2147490817 VPortB1Average "Average value of the port B1 voltage";
CM_ SG_ 2147490817 VPortB1Max "Maximum value of the  port B1 voltage seen since the last message sent";
CM_ SG_ 2147490817 VPortB1Min "Minimum value of the port B1 voltage seen since the last message sent";
CM_ BO_ 2147490175 "Command message to read the setpoints";
CM_ SG_ 2147490175 NCRC "CRC of the message. The module accepts this message only when a correct CRC is verified";
CM_ SG_ 2147490175 NPathSelect "The number of the power path to apply the setpoint read command to";
CM_ SG_ 2147490175 BReadSetpointRequest "Setpoint read command";
CM_ BO_ 2147490111 "Control of error acknowledgement commands";
CM_ SG_ 2147490111 NCRC "CRC of the message. The module accepts this message only when a correct CRC is verified";
CM_ SG_ 2147490111 NModuleSelect "Module ID on which to apply error acknowledge : 1-32 for module 1 to module 32, 63 for all modules";
CM_ SG_ 2147490111 BAckErrorsModuleRequest "Acknowledgement of all errors on module";
CM_ SG_ 2147490111 BAckErrorsPath1Request "Acknowledgement of errors on power path 1";
CM_ BO_ 2147490047 "Control  of Setpoints 2";
CM_ SG_ 2147490047 NCRC "CRC of the message. The module accepts this message only when a correct CRC is verified";
CM_ SG_ 2147490047 NModuleSelect "Module ID on which to apply the setpoints";
CM_ SG_ 2147490047 BL5_PPath1LimitLo "Power path 1 power lower limitation";
CM_ SG_ 2147490047 BL6_PPath1LimitLo "Power path 1 power lower limitation";
CM_ SG_ 2147490047 BL7_PPath1LimitLo "Power path 1 power lower limitation";
CM_ SG_ 2147490047 BL5_PPath1LimitHi "Power path 1 power upper limitation";
CM_ SG_ 2147490047 BL6_PPath1LimitHi "Power path 1 power upper limitation";
CM_ SG_ 2147490047 BL7_PPath1LimitHi "Power path 1 power upper limitation";
CM_ SG_ 2147490047 BL5_NMultiplexer "Multiplexer ID: allows to select the power path to apply the setpoints";
CM_ SG_ 2147490047 BL6_NMultiplexer "Multiplexer ID: allows to select the power path to apply the setpoints";
CM_ SG_ 2147490047 BL7_NMultiplexer "Multiplexer ID: allows to select the power path to apply the setpoints";
CM_ BO_ 2147489921 "Values of port A1";
CM_ SG_ 2147489921 NMultiplexer "Multiplexer ID";
CM_ SG_ 2147489921 NPortA1OverloadCount "Counter indicating the number of times an overload is detected on port A1";
CM_ SG_ 2147489921 IPortA1Average "Average value of the port A1 current";
CM_ SG_ 2147489921 VPortA1Average "Average value of the port A1 voltage";
CM_ SG_ 2147489921 VPortA1Max "Maximum value of the port A1 voltage seen since the last message sent";
CM_ SG_ 2147489921 VPortA1Min "Minimum value of the port A1 voltage seen since the last message sent";
CM_ BO_ 2147491521 "Value of all parameters of the configuration and settings";
CM_ SG_ 2147491521 NParameterValue "Value of the parameter";
CM_ SG_ 2147491521 NParameterIndex "Index at which the word is read in the selected zone";
CM_ SG_ 2147491521 NReadZoneSelect "Zone in which to read the parameters";
CM_ BO_ 2147489857 "Global values";
CM_ SG_ 2147489857 BSetpointsApplied "Indicates the power path setpoints have been applied";
CM_ SG_ 2147489857 VAuxCell6N1 "Auxiliary voltage number 1 of cell 6";
CM_ SG_ 2147489857 TCell6N2 "Temperature number 2 of cell 6";
CM_ SG_ 2147489857 TCell3N2 "Temperature number 2 of cell 3";
CM_ SG_ 2147489857 NCellOtpErrorFlags "Indicates overtemperature protection of cells";
CM_ SG_ 2147489857 VAuxCell5N1 "Auxiliary voltage number 1 of cell 5";
CM_ SG_ 2147489857 NApplicationId "Version number of the application program";
CM_ SG_ 2147489857 NBootloaderId "Version number of the bootloader program";
CM_ SG_ 2147489857 TInternal "Global product temperature";
CM_ SG_ 2147489857 TCell6N1 "Temperature number 1 of cell 6";
CM_ SG_ 2147489857 TCell3N1 "Temperature number 1 of cell 3";
CM_ SG_ 2147489857 NSyncNodeCount "Count of nodes in the array";
CM_ SG_ 2147489857 NSyncNodeRank "Rank of the node in the array";
CM_ SG_ 2147489857 VAuxCell4N1 "Auxiliary voltage number 1 of cell 4";
CM_ SG_ 2147489857 NCellVAuxErrorFlags "Indicates Auxiliary voltage error on cells";
CM_ SG_ 2147489857 TCell8N2 "Temperature number 2 of cell 8";
CM_ SG_ 2147489857 TCell5N2 "Temperature number 2 of cell 5";
CM_ SG_ 2147489857 TCell2N2 "Temperature number 2 of cell 2";
CM_ SG_ 2147489857 NReleaseMode "Reserved";
CM_ SG_ 2147489857 VAuxCell3N1 "Auxiliary voltage number 1 of cell 3";
CM_ SG_ 2147489857 NSerial "Product Serial Number";
CM_ SG_ 2147489857 NSettingsCrc "CRC of the SETTINGS";
CM_ SG_ 2147489857 NConfigCrc "CRC of the CONFIG";
CM_ SG_ 2147489857 TCell8N1 "Temperature number 1 of cell 8";
CM_ SG_ 2147489857 TCell5N1 "Temperature number 1 of cell 5";
CM_ SG_ 2147489857 TCell2N1 "Temperature number 1 of cell 2";
CM_ SG_ 2147489857 VAux3Measured "Auxiliary voltage used for offset of current and voltage measurement";
CM_ SG_ 2147489857 VAuxCell8N1 "Auxiliary voltage number 1 of cell 8";
CM_ SG_ 2147489857 VAuxCell2N1 "Auxiliary voltage number 1 of cell 2";
CM_ SG_ 2147489857 NCellXcpErrorFlags "Indicates Xcp error on cells";
CM_ SG_ 2147489857 TCell7N2 "Temperature number 2 of cell 7";
CM_ SG_ 2147489857 TCell4N2 "Temperature number 2 of cell 4";
CM_ SG_ 2147489857 TCell1N2 "Temperature number 2 of cell 1";
CM_ SG_ 2147489857 VAux2Measured "Auxiliary voltage 3V3 value";
CM_ SG_ 2147489857 VAuxCell7N1 "Auxiliary voltage number 1 of cell 7";
CM_ SG_ 2147489857 VAuxCell1N1 "Auxiliary voltage number 1 of cell 1";
CM_ SG_ 2147489857 NCellSwOcpErrorFlags "Indicates Sw overcurrent protection ";
CM_ SG_ 2147489857 NChecksum "Checksum of the application program";
CM_ SG_ 2147489857 NSettingsVersion "Version number of the SETTINGS";
CM_ SG_ 2147489857 NConfigVersion "Version number of the CONFIG";
CM_ SG_ 2147489857 TCell7N1 "Temperature number 1 of cell 7";
CM_ SG_ 2147489857 TCell4N1 "Temperature number 1 of cell 4";
CM_ SG_ 2147489857 TCell1N1 "Temperature number 1 of cell 1";
CM_ SG_ 2147489857 VAux1Measured "Auxiliary voltage LV value";
CM_ SG_ 2147489857 NMultiplexer "Multiplexer ID";
CM_ BO_ 2147489793 "Overal DCDC Status & Diagnostic";
CM_ SG_ 2147489793 BPath1AcModeActivated "Indicates that the Power Path 1 is working in AC mode";
CM_ SG_ 2147489793 BPath1ErrVAuxCell "Indicates a driver auxiliary voltage error on power path 1";
CM_ SG_ 2147489793 IPath1Unbalance "Unbalanced current between cells on power path 1";
CM_ SG_ 2147489793 BPath1RcpWarning "Warns the user of a potential reverse current problem";
CM_ SG_ 2147489793 BPath1OcpError "Power path 1 overcurrent fault";
CM_ SG_ 2147489793 BPath1OtpError "Power path 1 overtemperature fault";
CM_ SG_ 2147489793 BPath1SideBUvpError "Power path 1 side B undervoltage fault";
CM_ SG_ 2147489793 BPath1SideAUvpError "Power path 1 side A undervoltage fault";
CM_ SG_ 2147489793 BPath1SideBOvpError "Power path 1 side B overvoltage fault";
CM_ SG_ 2147489793 BPath1SideAOvpError "Power path 1 side A overvoltage fault";
CM_ SG_ 2147489793 BPath1Requested "Indicates that the power path 1 start command has been received";
CM_ SG_ 2147489793 NPath1CurrentSideSelected "Point of current limitation of Power path 1";
CM_ SG_ 2147489793 NPath1VoltageSideSelected "Point of voltage regulation of Power path 1";
CM_ SG_ 2147489793 NPath1State "Indicates the path 1 status";
CM_ SG_ 2147489793 NMultiplexer "Multiplexer ID";
CM_ SG_ 2147489793 BXcpError "Indicates a power switches command?s integrity fault";
CM_ SG_ 2147489793 NCellHwErrorFlags "Indicates HW errors triggered on CELL";
CM_ SG_ 2147489793 BIsoError "Indicates if an error occured on the isolated stage";
CM_ SG_ 2147489793 BSyncInputSignal "Indicates if a correct synchronization signal is detected on the input synchronization pin";
CM_ SG_ 2147489793 BSyncRequested "Indicates the synchronization command has been received";
CM_ SG_ 2147489793 BInternalTemperatureError "Indicates an overtemperature error on the internal temperature";
CM_ SG_ 2147489793 BConfigSettingsError "Indicates that the Config and/or Settings data is corrupted";
CM_ SG_ 2147489793 BAuxSupplyError "Indicates a fault on one of the auxiliary power supplies";
CM_ SG_ 2147489793 BCanTimeoutError "Indicates an error on the CAN bus";
CM_ SG_ 2147489793 BAuxIsoEnabled "Indicates that isolated auxiliary supplies are activated";
CM_ SG_ 2147489793 BSafetyDischargeEnabled "Indicates the safety discharge is activated";
CM_ SG_ 2147489793 BFaultSignal "Indicates the signal Fault status";
CM_ SG_ 2147489793 BEnableSignal "Indicates the external hardware ENABLE status";
CM_ SG_ 2147489793 BSafetyDischargeStatus "Indicates the safety discharge status";
CM_ SG_ 2147489793 BSyncStatus "Indicates the synchronization has been done successfully";
CM_ SG_ 2147489793 BReadConfigAndSettingsRequested "Indicates that the Read config and settings command has been received";
CM_ SG_ 2147489793 BSwResetModuleRequested "Indicates that the Software reset command has been received";
CM_ SG_ 2147489793 BSafetyDischargeRequested "Indicates that the safety discharge command has been received";
CM_ SG_ 2147489793 NModuleState "Indicates the overall module status";
CM_ BO_ 2147489983 "Control  of Setpoints 1 DC";
CM_ SG_ 2147489983 NCRC "CRC of the message. The module accepts this message only when a correct CRC is verified";
CM_ SG_ 2147489983 NModuleSelect "Module ID on which to apply the setpoints";
CM_ SG_ 2147489983 BL5_NPath1CurrentSideSelect "Point of current limitation of Power path 1";
CM_ SG_ 2147489983 BL6_NPath1CurrentSideSelect "Point of current limitation of Power path 1";
CM_ SG_ 2147489983 BL7_NPath1CurrentSideSelect "Point of current limitation of Power path 1";
CM_ SG_ 2147489983 BL5_NPath1VoltageSideSelect "Point of voltage regulation of Power path 1";
CM_ SG_ 2147489983 BL6_NPath1VoltageSideSelect "Point of voltage regulation of Power path 1";
CM_ SG_ 2147489983 BL7_NPath1VoltageSideSelect "Point of voltage regulation of Power path 1";
CM_ SG_ 2147489983 BL5_IPath1LimitLo "Power path 1 current lower limitation";
CM_ SG_ 2147489983 BL6_IPath1LimitLo "Power path 1 current lower limitation";
CM_ SG_ 2147489983 BL7_IPath1LimitLo "Power path 1 current lower limitation";
CM_ SG_ 2147489983 BL5_IPath1LimitHi "Power path 1 current upper limitation";
CM_ SG_ 2147489983 BL6_IPath1LimitHi "Power path 1 current upper limitation";
CM_ SG_ 2147489983 BL7_IPath1LimitHi "Power path 1 current upper limitation";
CM_ SG_ 2147489983 BL5_VPath1Setpoint "Power path 1 voltage setpoint";
CM_ SG_ 2147489983 BL6_VPath1Setpoint "Power path 1 voltage setpoint";
CM_ SG_ 2147489983 BL7_VPath1Setpoint "Power path 1 voltage setpoint";
CM_ SG_ 2147489983 BL5_NMultiplexer "Multiplexer ID: allows to select the power path to apply the setpoints";
CM_ SG_ 2147489983 BL6_NMultiplexer "Multiplexer ID: allows to select the power path to apply the setpoints";
CM_ SG_ 2147489983 BL7_NMultiplexer "Multiplexer ID: allows to select the power path to apply the setpoints";
CM_ BO_ 2147489855 "Control message from the ECU";
CM_ SG_ 2147489855 BIsoStandaloneRequest "IsoStandalone command";
CM_ SG_ 2147489855 NCRC "CRC of the message. The module accepts this message only when a correct CRC is verified";
CM_ SG_ 2147489855 NModuleSelect "Module ID on which to apply software reset command and/or read config and settings command and/or discharge active command : 1-32 for module 1 to module 32, 63 for all modules";
CM_ SG_ 2147489855 BSyncRequest "Activate synchronization command";
CM_ SG_ 2147489855 BReadConfigAndSettingsRequest "Read config and settings of module command";
CM_ SG_ 2147489855 BSwResetModuleRequest "Software reset module command";
CM_ SG_ 2147489855 BSafetyDischargeRequest "Module safety discharge command";
CM_ SG_ 2147489855 BPath1Request "Start/Stop power path 1 command";
CM_ SG_ 2147489855 NCounter "Counter for reception of CAN messages. If it does not change for more than CanTimeOut parameter then an error is detected (CAN error)";
CM_ BO_ 2147491713 "Overal Isolation stage Status & Diagnostic";
CM_ SG_ 2147491713 BStartupTimeout "Indicates the start up sequence timed out";
CM_ SG_ 2147491713 BOtpBuckAux "Indicates on over temperature error on the auxiliary buck";
CM_ SG_ 2147491713 BOtpSecError "Indicates an over temperature error on the secondary side of the isolation transformer (side C)";
CM_ SG_ 2147491713 BOtpPriError "Indicates an over temperature error on the primary side of the isolation transformer (side internal)";
CM_ SG_ 2147491713 BXcpBuckAuxError "Indicates an internal fault on the auxiliary buck stage";
CM_ SG_ 2147491713 BXcpDcdcError "Indicates an internal fault on the Dcdc stage";
CM_ SG_ 2147491713 BSecOcpError "Indicates an over current error on the secondary side of the isolation transformer (side C)";
CM_ SG_ 2147491713 BPriOcpError "Indicates an over current error on the primary side of the isolation transformer (side internal)";
CM_ SG_ 2147491713 BSecUvpError "Indicates an undervoltage on the secondary side of the isolation transfomer (side C)";
CM_ SG_ 2147491713 BSecOvpError "Indicates an overvoltage on the secondary side of the isolation transformer (side C)";
CM_ SG_ 2147491713 BPriUvpError "Indicates an undervoltage on the primary side of the isolation transformer (side internal)";
CM_ SG_ 2147491713 BPriOvpError "Indicates an overvoltage on the primary side of the isolation transformer (side internal)";
CM_ SG_ 2147491713 BBuckOcpError "Indicates an error on the current measured in the auxiliary buck";
CM_ SG_ 2147491713 BSuppAuxUvpError "Indicates an undervoltage on the output of the auxiliairy buck";
CM_ SG_ 2147491713 BSuppAuxOvpError "Indicates an overvoltage on the output voltage of the auxiliary buck";
CM_ SG_ 2147491713 BBuckAuxHwError "Indicates an overvoltage on the output voltage of the auxiliary buck";
CM_ SG_ 2147491713 BBuckVAuxDriverError "Indicates an hardware error on the auxiliary buck";
CM_ SG_ 2147491713 BAuxSupplyError "Indicates an error on the auxiliary supply";
CM_ SG_ 2147491713 BCanIntTimeoutError "Indicates an error on the internal CAN bus";
CM_ SG_ 2147491713 BCanTimeoutError "Indicates an error on the CAN bus";
CM_ SG_ 2147491713 BConfigSettingsError "Indicates the Config and or the Settings data are corrupted";
CM_ SG_ 2147491713 BPowerRequested "Indicates a start request has been received from the power board";
CM_ SG_ 2147491713 NAuxBuckState "Indicates the auxiliary buck state";
CM_ SG_ 2147491713 NChan2State "Indicates the isolation transformer channel 2 state";
CM_ SG_ 2147491713 NChan1State "Indicates the isolation transformer channel 1 state";
CM_ SG_ 2147491713 BAuxIsoEnabled "Indicates if the isolated auxiliary supplies are activated";
CM_ SG_ 2147491713 BFaultSignal "Indicates the signal Fault status";
CM_ SG_ 2147491713 BEnableSignal "Indicates the external hardware ENABLE status";
CM_ SG_ 2147491713 BSyncInputSignal "Indicates if a correct synchronization signal is detected on the input synchronization pin";
CM_ SG_ 2147491713 BSyncStatus "Indicates if the synchronization has been done successfully";
CM_ SG_ 2147491713 BSwResetModuleRequested "Indicates the software reset command has been received";
CM_ SG_ 2147491713 NState "Indicates the isolation stage state";
CM_ BO_ 2147491777 "Isolation stage global values";
CM_ SG_ 2147491777 TSecCh2D "Temperature of the secondary bridge D of the channel 2 of the dcdc isolated stage";
CM_ SG_ 2147491777 TSecCh1D "Temperature of the secondary bridge D of the channel 1 of the dcdc isolated stage";
CM_ SG_ 2147491777 TPriCh2D "Temperature of the primary bridge D of the channel 2 of the dcdc isolated stage";
CM_ SG_ 2147491777 TPriCh1D "Temperature of the primary bridge D of the channel 1 of the dcdc isolated stage";
CM_ SG_ 2147491777 NReleaseMode "Reserved";
CM_ SG_ 2147491777 NApplicationId "Module Serial Number";
CM_ SG_ 2147491777 NSettingsVersion "Version number of the settings";
CM_ SG_ 2147491777 NConfigCrc "Crc of the configuration";
CM_ SG_ 2147491777 NXcpDcdcErrorFlags "Details on internal fault for the dcdc stage";
CM_ SG_ 2147491777 NOtpDcdcErrorFlags "Details on over temperature protection";
CM_ SG_ 2147491777 TSecCh2C "Temperature of the secondary bridge C of the channel 2 of the dcdc isolated stage";
CM_ SG_ 2147491777 TSecCh1C "Temperature of the secondary bridge C of the channel 1 of the dcdc isolated stage";
CM_ SG_ 2147491777 TPriCh2C "Temperature of the primary bridge C of the channel 2 of the dcdc isolated stage";
CM_ SG_ 2147491777 TPriCh1C "Temperature of the primary bridge C of the channel 1 of the dcdc isolated stage";
CM_ SG_ 2147491777 V1v65Aux "Auxiliary voltage 1V65 value";
CM_ SG_ 2147491777 VBuckAuxDriver "Auxiliary voltage supply for the auxiliary buck drivers";
CM_ SG_ 2147491777 TSecCh2B "Temperature of the secondary bridge B of the channel 2 of the dcdc isolated stage";
CM_ SG_ 2147491777 TSecCh1B "Temperature of the secondary bridge B of the channel 1 of the dcdc isolated stage";
CM_ SG_ 2147491777 TPriCh2B "Temperature of the primary bridge B of the channel 2 of the dcdc isolated stage";
CM_ SG_ 2147491777 TPriCh1B "Temperature of the primary bridge B of the channel 1 of the dcdc isolated stage";
CM_ SG_ 2147491777 V3v3Aux "Auxiliary voltage 3v3 value";
CM_ SG_ 2147491777 NMissedSyncPulseCount "reserved";
CM_ SG_ 2147491777 NChecksum "Checksum of the application program";
CM_ SG_ 2147491777 NSerial "Module serial number";
CM_ SG_ 2147491777 NSettingsCrc "Crc of the settings";
CM_ SG_ 2147491777 NBootloaderId "Version number of the bootloader program";
CM_ SG_ 2147491777 NConfigVersion "Version number of the configuration";
CM_ SG_ 2147491777 NOcpDcdcErrorFlags "Detail on over current protection";
CM_ SG_ 2147491777 TBuckAux "Temperature of the auxiliary buck";
CM_ SG_ 2147491777 TSecCh2A "Temperature of the secondary bridge A of the channel 2 of the dcdc isolated stage";
CM_ SG_ 2147491777 TSecCh1A "Temperature of the secondary bridge A of the channel 1 of the dcdc isolated stage";
CM_ SG_ 2147491777 TPriCh2A "Temperature of the primary bridge A of the channel 2 of the dcdc isolated stage";
CM_ SG_ 2147491777 TPriCh1A "Temperature of the primary bridge A of the channel 1 of the dcdc isolated stage";
CM_ SG_ 2147491777 VHvAux "Main auxiliary voltage";
CM_ SG_ 2147491777 NMultiplexer "Multiplexer ID";
CM_ SG_ 2147491777 VSuppAux "Auxiliary voltage supply for the dcdc isolation stage";
CM_ SG_ 2147491777 IBuckAux "Auxiliary buck current value";
CM_ BO_ 2147490689 "Values of port Internal";
CM_ SG_ 2147490689 IPortInternalAverage "Average value of the internal port current";
CM_ SG_ 2147490689 VPortInternalAverage "Average value of the internal port voltage";
CM_ SG_ 2147490689 VPortInternalMax "Maximum value of the internal port voltage measured since the last message sent";
CM_ SG_ 2147490689 VPortInternalMin "Minimum value of the internal port voltage measured since the last message sent";
CM_ BO_ 2147490753 "Values of port C1";
CM_ SG_ 2147490753 IPortC1Average "Average value of the port C1 current";
CM_ SG_ 2147490753 VPortC1Average "Average value of the port C1 voltage";
CM_ SG_ 2147490753 VPortC1Max "Maximum value of the  port C1 voltage seen since the last message sent";
CM_ SG_ 2147490753 VPortC1Min "Minimum value of the port C1 voltage seen since the last message sent";
CM_ BO_ 2147491394 "Response message giving the present values of the setpoints";
CM_ SG_ 2147491394 NPath1CurrentSideSelected "Point of current limitation of Power path 1";
CM_ SG_ 2147491394 NPath1VoltageSideSelected "Point of voltage regulation of Power path 1";
CM_ SG_ 2147491394 IPath1LimitLo "Power path 1 current lower limitation";
CM_ SG_ 2147491394 IPath1LimitHi "Power path 1 current upper limitation";
CM_ SG_ 2147491394 VPath1Setpoint "Power path 1 voltage setpoint";
CM_ SG_ 2147491394 NMultiplexer "Multiplexer ID: the power path's number of the setpoints";
CM_ BO_ 2147491458 "Response message giving the present values of the setpoints";
CM_ SG_ 2147491458 PPath1LimitLo "Power path 1 power lower limitation";
CM_ SG_ 2147491458 PPath1LimitHi "Power path 1 power upper limitation";
CM_ SG_ 2147491458 NMultiplexer "Multiplexer ID:  the power path's number of the setpoints";
CM_ BO_ 2147490818 "Values of port B1";
CM_ SG_ 2147490818 NPortB1OverloadCount "Counter indicating the number of times an overload is detected on port B1";
CM_ SG_ 2147490818 IPortB1Average "Average value of the port B1 current";
CM_ SG_ 2147490818 VPortB1Average "Average value of the port B1 voltage";
CM_ SG_ 2147490818 VPortB1Max "Maximum value of the  port B1 voltage seen since the last message sent";
CM_ SG_ 2147490818 VPortB1Min "Minimum value of the port B1 voltage seen since the last message sent";
CM_ BO_ 2147489922 "Values of port A1";
CM_ SG_ 2147489922 NMultiplexer "Multiplexer ID";
CM_ SG_ 2147489922 NPortA1OverloadCount "Counter indicating the number of times an overload is detected on port A1";
CM_ SG_ 2147489922 IPortA1Average "Average value of the port A1 current";
CM_ SG_ 2147489922 VPortA1Average "Average value of the port A1 voltage";
CM_ SG_ 2147489922 VPortA1Max "Maximum value of the port A1 voltage seen since the last message sent";
CM_ SG_ 2147489922 VPortA1Min "Minimum value of the port A1 voltage seen since the last message sent";
CM_ BO_ 2147491522 "Value of all parameters of the configuration and settings";
CM_ SG_ 2147491522 NParameterValue "Value of the parameter";
CM_ SG_ 2147491522 NParameterIndex "Index at which the word is read in the selected zone";
CM_ SG_ 2147491522 NReadZoneSelect "Zone in which to read the parameters";
CM_ BO_ 2147489858 "Global values";
CM_ SG_ 2147489858 BSetpointsApplied "Indicates the power path setpoints have been applied";
CM_ SG_ 2147489858 VAuxCell6N1 "Auxiliary voltage number 1 of cell 6";
CM_ SG_ 2147489858 TCell6N2 "Temperature number 2 of cell 6";
CM_ SG_ 2147489858 TCell3N2 "Temperature number 2 of cell 3";
CM_ SG_ 2147489858 NCellOtpErrorFlags "Indicates overtemperature protection of cells";
CM_ SG_ 2147489858 VAuxCell5N1 "Auxiliary voltage number 1 of cell 5";
CM_ SG_ 2147489858 NApplicationId "Version number of the application program";
CM_ SG_ 2147489858 NBootloaderId "Version number of the bootloader program";
CM_ SG_ 2147489858 TInternal "Global product temperature";
CM_ SG_ 2147489858 TCell6N1 "Temperature number 1 of cell 6";
CM_ SG_ 2147489858 TCell3N1 "Temperature number 1 of cell 3";
CM_ SG_ 2147489858 NSyncNodeCount "Count of nodes in the array";
CM_ SG_ 2147489858 NSyncNodeRank "Rank of the node in the array";
CM_ SG_ 2147489858 VAuxCell4N1 "Auxiliary voltage number 1 of cell 4";
CM_ SG_ 2147489858 NCellVAuxErrorFlags "Indicates Auxiliary voltage error on cells";
CM_ SG_ 2147489858 TCell8N2 "Temperature number 2 of cell 8";
CM_ SG_ 2147489858 TCell5N2 "Temperature number 2 of cell 5";
CM_ SG_ 2147489858 TCell2N2 "Temperature number 2 of cell 2";
CM_ SG_ 2147489858 NReleaseMode "Reserved";
CM_ SG_ 2147489858 VAuxCell3N1 "Auxiliary voltage number 1 of cell 3";
CM_ SG_ 2147489858 NSerial "Product Serial Number";
CM_ SG_ 2147489858 NSettingsCrc "CRC of the SETTINGS";
CM_ SG_ 2147489858 NConfigCrc "CRC of the CONFIG";
CM_ SG_ 2147489858 TCell8N1 "Temperature number 1 of cell 8";
CM_ SG_ 2147489858 TCell5N1 "Temperature number 1 of cell 5";
CM_ SG_ 2147489858 TCell2N1 "Temperature number 1 of cell 2";
CM_ SG_ 2147489858 VAux3Measured "Auxiliary voltage used for offset of current and voltage measurement";
CM_ SG_ 2147489858 VAuxCell8N1 "Auxiliary voltage number 1 of cell 8";
CM_ SG_ 2147489858 VAuxCell2N1 "Auxiliary voltage number 1 of cell 2";
CM_ SG_ 2147489858 NCellXcpErrorFlags "Indicates Xcp error on cells";
CM_ SG_ 2147489858 TCell7N2 "Temperature number 2 of cell 7";
CM_ SG_ 2147489858 TCell4N2 "Temperature number 2 of cell 4";
CM_ SG_ 2147489858 TCell1N2 "Temperature number 2 of cell 1";
CM_ SG_ 2147489858 VAux2Measured "Auxiliary voltage 3V3 value";
CM_ SG_ 2147489858 VAuxCell7N1 "Auxiliary voltage number 1 of cell 7";
CM_ SG_ 2147489858 VAuxCell1N1 "Auxiliary voltage number 1 of cell 1";
CM_ SG_ 2147489858 NCellSwOcpErrorFlags "Indicates Sw overcurrent protection ";
CM_ SG_ 2147489858 NChecksum "Checksum of the application program";
CM_ SG_ 2147489858 NSettingsVersion "Version number of the SETTINGS";
CM_ SG_ 2147489858 NConfigVersion "Version number of the CONFIG";
CM_ SG_ 2147489858 TCell7N1 "Temperature number 1 of cell 7";
CM_ SG_ 2147489858 TCell4N1 "Temperature number 1 of cell 4";
CM_ SG_ 2147489858 TCell1N1 "Temperature number 1 of cell 1";
CM_ SG_ 2147489858 VAux1Measured "Auxiliary voltage LV value";
CM_ SG_ 2147489858 NMultiplexer "Multiplexer ID";
CM_ BO_ 2147489794 "Overal DCDC Status & Diagnostic";
CM_ SG_ 2147489794 BPath1AcModeActivated "Indicates that the Power Path 1 is working in AC mode";
CM_ SG_ 2147489794 BPath1ErrVAuxCell "Indicates a driver auxiliary voltage error on power path 1";
CM_ SG_ 2147489794 IPath1Unbalance "Unbalanced current between cells on power path 1";
CM_ SG_ 2147489794 BPath1RcpWarning "Warns the user of a potential reverse current problem";
CM_ SG_ 2147489794 BPath1OcpError "Power path 1 overcurrent fault";
CM_ SG_ 2147489794 BPath1OtpError "Power path 1 overtemperature fault";
CM_ SG_ 2147489794 BPath1SideBUvpError "Power path 1 side B undervoltage fault";
CM_ SG_ 2147489794 BPath1SideAUvpError "Power path 1 side A undervoltage fault";
CM_ SG_ 2147489794 BPath1SideBOvpError "Power path 1 side B overvoltage fault";
CM_ SG_ 2147489794 BPath1SideAOvpError "Power path 1 side A overvoltage fault";
CM_ SG_ 2147489794 BPath1Requested "Indicates that the power path 1 start command has been received";
CM_ SG_ 2147489794 NPath1CurrentSideSelected "Point of current limitation of Power path 1";
CM_ SG_ 2147489794 NPath1VoltageSideSelected "Point of voltage regulation of Power path 1";
CM_ SG_ 2147489794 NPath1State "Indicates the path 1 status";
CM_ SG_ 2147489794 NMultiplexer "Multiplexer ID";
CM_ SG_ 2147489794 BXcpError "Indicates a power switches command?s integrity fault";
CM_ SG_ 2147489794 NCellHwErrorFlags "Indicates HW errors triggered on CELL";
CM_ SG_ 2147489794 BIsoError "Indicates if an error occured on the isolated stage";
CM_ SG_ 2147489794 BSyncInputSignal "Indicates if a correct synchronization signal is detected on the input synchronization pin";
CM_ SG_ 2147489794 BSyncRequested "Indicates the synchronization command has been received";
CM_ SG_ 2147489794 BInternalTemperatureError "Indicates an overtemperature error on the internal temperature";
CM_ SG_ 2147489794 BConfigSettingsError "Indicates that the Config and/or Settings data is corrupted";
CM_ SG_ 2147489794 BAuxSupplyError "Indicates a fault on one of the auxiliary power supplies";
CM_ SG_ 2147489794 BCanTimeoutError "Indicates an error on the CAN bus";
CM_ SG_ 2147489794 BAuxIsoEnabled "Indicates that isolated auxiliary supplies are activated";
CM_ SG_ 2147489794 BSafetyDischargeEnabled "Indicates the safety discharge is activated";
CM_ SG_ 2147489794 BFaultSignal "Indicates the signal Fault status";
CM_ SG_ 2147489794 BEnableSignal "Indicates the external hardware ENABLE status";
CM_ SG_ 2147489794 BSafetyDischargeStatus "Indicates the safety discharge status";
CM_ SG_ 2147489794 BSyncStatus "Indicates the synchronization has been done successfully";
CM_ SG_ 2147489794 BReadConfigAndSettingsRequested "Indicates that the Read config and settings command has been received";
CM_ SG_ 2147489794 BSwResetModuleRequested "Indicates that the Software reset command has been received";
CM_ SG_ 2147489794 BSafetyDischargeRequested "Indicates that the safety discharge command has been received";
CM_ SG_ 2147489794 NModuleState "Indicates the overall module status";
CM_ BO_ 2147491714 "Overal Isolation stage Status & Diagnostic";
CM_ SG_ 2147491714 BStartupTimeout "Indicates the start up sequence timed out";
CM_ SG_ 2147491714 BOtpBuckAux "Indicates on over temperature error on the auxiliary buck";
CM_ SG_ 2147491714 BOtpSecError "Indicates an over temperature error on the secondary side of the isolation transformer (side C)";
CM_ SG_ 2147491714 BOtpPriError "Indicates an over temperature error on the primary side of the isolation transformer (side internal)";
CM_ SG_ 2147491714 BXcpBuckAuxError "Indicates an internal fault on the auxiliary buck stage";
CM_ SG_ 2147491714 BXcpDcdcError "Indicates an internal fault on the Dcdc stage";
CM_ SG_ 2147491714 BSecOcpError "Indicates an over current error on the secondary side of the isolation transformer (side C)";
CM_ SG_ 2147491714 BPriOcpError "Indicates an over current error on the primary side of the isolation transformer (side internal)";
CM_ SG_ 2147491714 BSecUvpError "Indicates an undervoltage on the secondary side of the isolation transfomer (side C)";
CM_ SG_ 2147491714 BSecOvpError "Indicates an overvoltage on the secondary side of the isolation transformer (side C)";
CM_ SG_ 2147491714 BPriUvpError "Indicates an undervoltage on the primary side of the isolation transformer (side internal)";
CM_ SG_ 2147491714 BPriOvpError "Indicates an overvoltage on the primary side of the isolation transformer (side internal)";
CM_ SG_ 2147491714 BBuckOcpError "Indicates an error on the current measured in the auxiliary buck";
CM_ SG_ 2147491714 BSuppAuxUvpError "Indicates an undervoltage on the output of the auxiliairy buck";
CM_ SG_ 2147491714 BSuppAuxOvpError "Indicates an overvoltage on the output voltage of the auxiliary buck";
CM_ SG_ 2147491714 BBuckAuxHwError "Indicates an overvoltage on the output voltage of the auxiliary buck";
CM_ SG_ 2147491714 BBuckVAuxDriverError "Indicates an hardware error on the auxiliary buck";
CM_ SG_ 2147491714 BAuxSupplyError "Indicates an error on the auxiliary supply";
CM_ SG_ 2147491714 BCanIntTimeoutError "Indicates an error on the internal CAN bus";
CM_ SG_ 2147491714 BCanTimeoutError "Indicates an error on the CAN bus";
CM_ SG_ 2147491714 BConfigSettingsError "Indicates the Config and or the Settings data are corrupted";
CM_ SG_ 2147491714 BPowerRequested "Indicates a start request has been received from the power board";
CM_ SG_ 2147491714 NAuxBuckState "Indicates the auxiliary buck state";
CM_ SG_ 2147491714 NChan2State "Indicates the isolation transformer channel 2 state";
CM_ SG_ 2147491714 NChan1State "Indicates the isolation transformer channel 1 state";
CM_ SG_ 2147491714 BAuxIsoEnabled "Indicates if the isolated auxiliary supplies are activated";
CM_ SG_ 2147491714 BFaultSignal "Indicates the signal Fault status";
CM_ SG_ 2147491714 BEnableSignal "Indicates the external hardware ENABLE status";
CM_ SG_ 2147491714 BSyncInputSignal "Indicates if a correct synchronization signal is detected on the input synchronization pin";
CM_ SG_ 2147491714 BSyncStatus "Indicates if the synchronization has been done successfully";
CM_ SG_ 2147491714 BSwResetModuleRequested "Indicates the software reset command has been received";
CM_ SG_ 2147491714 NState "Indicates the isolation stage state";
CM_ BO_ 2147491778 "Isolation stage global values";
CM_ SG_ 2147491778 TSecCh2D "Temperature of the secondary bridge D of the channel 2 of the dcdc isolated stage";
CM_ SG_ 2147491778 TSecCh1D "Temperature of the secondary bridge D of the channel 1 of the dcdc isolated stage";
CM_ SG_ 2147491778 TPriCh2D "Temperature of the primary bridge D of the channel 2 of the dcdc isolated stage";
CM_ SG_ 2147491778 TPriCh1D "Temperature of the primary bridge D of the channel 1 of the dcdc isolated stage";
CM_ SG_ 2147491778 NReleaseMode "Reserved";
CM_ SG_ 2147491778 NApplicationId "Module Serial Number";
CM_ SG_ 2147491778 NSettingsVersion "Version number of the settings";
CM_ SG_ 2147491778 NConfigCrc "Crc of the configuration";
CM_ SG_ 2147491778 NXcpDcdcErrorFlags "Details on internal fault for the dcdc stage";
CM_ SG_ 2147491778 NOtpDcdcErrorFlags "Details on over temperature protection";
CM_ SG_ 2147491778 TSecCh2C "Temperature of the secondary bridge C of the channel 2 of the dcdc isolated stage";
CM_ SG_ 2147491778 TSecCh1C "Temperature of the secondary bridge C of the channel 1 of the dcdc isolated stage";
CM_ SG_ 2147491778 TPriCh2C "Temperature of the primary bridge C of the channel 2 of the dcdc isolated stage";
CM_ SG_ 2147491778 TPriCh1C "Temperature of the primary bridge C of the channel 1 of the dcdc isolated stage";
CM_ SG_ 2147491778 V1v65Aux "Auxiliary voltage 1V65 value";
CM_ SG_ 2147491778 VBuckAuxDriver "Auxiliary voltage supply for the auxiliary buck drivers";
CM_ SG_ 2147491778 TSecCh2B "Temperature of the secondary bridge B of the channel 2 of the dcdc isolated stage";
CM_ SG_ 2147491778 TSecCh1B "Temperature of the secondary bridge B of the channel 1 of the dcdc isolated stage";
CM_ SG_ 2147491778 TPriCh2B "Temperature of the primary bridge B of the channel 2 of the dcdc isolated stage";
CM_ SG_ 2147491778 TPriCh1B "Temperature of the primary bridge B of the channel 1 of the dcdc isolated stage";
CM_ SG_ 2147491778 V3v3Aux "Auxiliary voltage 3v3 value";
CM_ SG_ 2147491778 NMissedSyncPulseCount "reserved";
CM_ SG_ 2147491778 NChecksum "Checksum of the application program";
CM_ SG_ 2147491778 NSerial "Module serial number";
CM_ SG_ 2147491778 NSettingsCrc "Crc of the settings";
CM_ SG_ 2147491778 NBootloaderId "Version number of the bootloader program";
CM_ SG_ 2147491778 NConfigVersion "Version number of the configuration";
CM_ SG_ 2147491778 NOcpDcdcErrorFlags "Detail on over current protection";
CM_ SG_ 2147491778 TBuckAux "Temperature of the auxiliary buck";
CM_ SG_ 2147491778 TSecCh2A "Temperature of the secondary bridge A of the channel 2 of the dcdc isolated stage";
CM_ SG_ 2147491778 TSecCh1A "Temperature of the secondary bridge A of the channel 1 of the dcdc isolated stage";
CM_ SG_ 2147491778 TPriCh2A "Temperature of the primary bridge A of the channel 2 of the dcdc isolated stage";
CM_ SG_ 2147491778 TPriCh1A "Temperature of the primary bridge A of the channel 1 of the dcdc isolated stage";
CM_ SG_ 2147491778 VHvAux "Main auxiliary voltage";
CM_ SG_ 2147491778 NMultiplexer "Multiplexer ID";
CM_ SG_ 2147491778 VSuppAux "Auxiliary voltage supply for the dcdc isolation stage";
CM_ SG_ 2147491778 IBuckAux "Auxiliary buck current value";
CM_ BO_ 2147490690 "Values of port Internal";
CM_ SG_ 2147490690 IPortInternalAverage "Average value of the internal port current";
CM_ SG_ 2147490690 VPortInternalAverage "Average value of the internal port voltage";
CM_ SG_ 2147490690 VPortInternalMax "Maximum value of the internal port voltage measured since the last message sent";
CM_ SG_ 2147490690 VPortInternalMin "Minimum value of the internal port voltage measured since the last message sent";
CM_ BO_ 2147490754 "Values of port C1";
CM_ SG_ 2147490754 IPortC1Average "Average value of the port C1 current";
CM_ SG_ 2147490754 VPortC1Average "Average value of the port C1 voltage";
CM_ SG_ 2147490754 VPortC1Max "Maximum value of the  port C1 voltage seen since the last message sent";
CM_ SG_ 2147490754 VPortC1Min "Minimum value of the port C1 voltage seen since the last message sent";
CM_ BO_ 2147491395 "Response message giving the present values of the setpoints";
CM_ SG_ 2147491395 NPath1CurrentSideSelected "Point of current limitation of Power path 1";
CM_ SG_ 2147491395 NPath1VoltageSideSelected "Point of voltage regulation of Power path 1";
CM_ SG_ 2147491395 IPath1LimitLo "Power path 1 current lower limitation";
CM_ SG_ 2147491395 IPath1LimitHi "Power path 1 current upper limitation";
CM_ SG_ 2147491395 VPath1Setpoint "Power path 1 voltage setpoint";
CM_ SG_ 2147491395 NMultiplexer "Multiplexer ID: the power path's number of the setpoints";
CM_ BO_ 2147491459 "Response message giving the present values of the setpoints";
CM_ SG_ 2147491459 PPath1LimitLo "Power path 1 power lower limitation";
CM_ SG_ 2147491459 PPath1LimitHi "Power path 1 power upper limitation";
CM_ SG_ 2147491459 NMultiplexer "Multiplexer ID:  the power path's number of the setpoints";
CM_ BO_ 2147490819 "Values of port B1";
CM_ SG_ 2147490819 NPortB1OverloadCount "Counter indicating the number of times an overload is detected on port B1";
CM_ SG_ 2147490819 IPortB1Average "Average value of the port B1 current";
CM_ SG_ 2147490819 VPortB1Average "Average value of the port B1 voltage";
CM_ SG_ 2147490819 VPortB1Max "Maximum value of the  port B1 voltage seen since the last message sent";
CM_ SG_ 2147490819 VPortB1Min "Minimum value of the port B1 voltage seen since the last message sent";
CM_ BO_ 2147489923 "Values of port A1";
CM_ SG_ 2147489923 NMultiplexer "Multiplexer ID";
CM_ SG_ 2147489923 NPortA1OverloadCount "Counter indicating the number of times an overload is detected on port A1";
CM_ SG_ 2147489923 IPortA1Average "Average value of the port A1 current";
CM_ SG_ 2147489923 VPortA1Average "Average value of the port A1 voltage";
CM_ SG_ 2147489923 VPortA1Max "Maximum value of the port A1 voltage seen since the last message sent";
CM_ SG_ 2147489923 VPortA1Min "Minimum value of the port A1 voltage seen since the last message sent";
CM_ BO_ 2147491523 "Value of all parameters of the configuration and settings";
CM_ SG_ 2147491523 NParameterValue "Value of the parameter";
CM_ SG_ 2147491523 NParameterIndex "Index at which the word is read in the selected zone";
CM_ SG_ 2147491523 NReadZoneSelect "Zone in which to read the parameters";
CM_ BO_ 2147489859 "Global values";
CM_ SG_ 2147489859 BSetpointsApplied "Indicates the power path setpoints have been applied";
CM_ SG_ 2147489859 VAuxCell6N1 "Auxiliary voltage number 1 of cell 6";
CM_ SG_ 2147489859 TCell6N2 "Temperature number 2 of cell 6";
CM_ SG_ 2147489859 TCell3N2 "Temperature number 2 of cell 3";
CM_ SG_ 2147489859 NCellOtpErrorFlags "Indicates overtemperature protection of cells";
CM_ SG_ 2147489859 VAuxCell5N1 "Auxiliary voltage number 1 of cell 5";
CM_ SG_ 2147489859 NApplicationId "Version number of the application program";
CM_ SG_ 2147489859 NBootloaderId "Version number of the bootloader program";
CM_ SG_ 2147489859 TInternal "Global product temperature";
CM_ SG_ 2147489859 TCell6N1 "Temperature number 1 of cell 6";
CM_ SG_ 2147489859 TCell3N1 "Temperature number 1 of cell 3";
CM_ SG_ 2147489859 NSyncNodeCount "Count of nodes in the array";
CM_ SG_ 2147489859 NSyncNodeRank "Rank of the node in the array";
CM_ SG_ 2147489859 VAuxCell4N1 "Auxiliary voltage number 1 of cell 4";
CM_ SG_ 2147489859 NCellVAuxErrorFlags "Indicates Auxiliary voltage error on cells";
CM_ SG_ 2147489859 TCell8N2 "Temperature number 2 of cell 8";
CM_ SG_ 2147489859 TCell5N2 "Temperature number 2 of cell 5";
CM_ SG_ 2147489859 TCell2N2 "Temperature number 2 of cell 2";
CM_ SG_ 2147489859 NReleaseMode "Reserved";
CM_ SG_ 2147489859 VAuxCell3N1 "Auxiliary voltage number 1 of cell 3";
CM_ SG_ 2147489859 NSerial "Product Serial Number";
CM_ SG_ 2147489859 NSettingsCrc "CRC of the SETTINGS";
CM_ SG_ 2147489859 NConfigCrc "CRC of the CONFIG";
CM_ SG_ 2147489859 TCell8N1 "Temperature number 1 of cell 8";
CM_ SG_ 2147489859 TCell5N1 "Temperature number 1 of cell 5";
CM_ SG_ 2147489859 TCell2N1 "Temperature number 1 of cell 2";
CM_ SG_ 2147489859 VAux3Measured "Auxiliary voltage used for offset of current and voltage measurement";
CM_ SG_ 2147489859 VAuxCell8N1 "Auxiliary voltage number 1 of cell 8";
CM_ SG_ 2147489859 VAuxCell2N1 "Auxiliary voltage number 1 of cell 2";
CM_ SG_ 2147489859 NCellXcpErrorFlags "Indicates Xcp error on cells";
CM_ SG_ 2147489859 TCell7N2 "Temperature number 2 of cell 7";
CM_ SG_ 2147489859 TCell4N2 "Temperature number 2 of cell 4";
CM_ SG_ 2147489859 TCell1N2 "Temperature number 2 of cell 1";
CM_ SG_ 2147489859 VAux2Measured "Auxiliary voltage 3V3 value";
CM_ SG_ 2147489859 VAuxCell7N1 "Auxiliary voltage number 1 of cell 7";
CM_ SG_ 2147489859 VAuxCell1N1 "Auxiliary voltage number 1 of cell 1";
CM_ SG_ 2147489859 NCellSwOcpErrorFlags "Indicates Sw overcurrent protection ";
CM_ SG_ 2147489859 NChecksum "Checksum of the application program";
CM_ SG_ 2147489859 NSettingsVersion "Version number of the SETTINGS";
CM_ SG_ 2147489859 NConfigVersion "Version number of the CONFIG";
CM_ SG_ 2147489859 TCell7N1 "Temperature number 1 of cell 7";
CM_ SG_ 2147489859 TCell4N1 "Temperature number 1 of cell 4";
CM_ SG_ 2147489859 TCell1N1 "Temperature number 1 of cell 1";
CM_ SG_ 2147489859 VAux1Measured "Auxiliary voltage LV value";
CM_ SG_ 2147489859 NMultiplexer "Multiplexer ID";
CM_ BO_ 2147489795 "Overal DCDC Status & Diagnostic";
CM_ SG_ 2147489795 BPath1AcModeActivated "Indicates that the Power Path 1 is working in AC mode";
CM_ SG_ 2147489795 BPath1ErrVAuxCell "Indicates a driver auxiliary voltage error on power path 1";
CM_ SG_ 2147489795 IPath1Unbalance "Unbalanced current between cells on power path 1";
CM_ SG_ 2147489795 BPath1RcpWarning "Warns the user of a potential reverse current problem";
CM_ SG_ 2147489795 BPath1OcpError "Power path 1 overcurrent fault";
CM_ SG_ 2147489795 BPath1OtpError "Power path 1 overtemperature fault";
CM_ SG_ 2147489795 BPath1SideBUvpError "Power path 1 side B undervoltage fault";
CM_ SG_ 2147489795 BPath1SideAUvpError "Power path 1 side A undervoltage fault";
CM_ SG_ 2147489795 BPath1SideBOvpError "Power path 1 side B overvoltage fault";
CM_ SG_ 2147489795 BPath1SideAOvpError "Power path 1 side A overvoltage fault";
CM_ SG_ 2147489795 BPath1Requested "Indicates that the power path 1 start command has been received";
CM_ SG_ 2147489795 NPath1CurrentSideSelected "Point of current limitation of Power path 1";
CM_ SG_ 2147489795 NPath1VoltageSideSelected "Point of voltage regulation of Power path 1";
CM_ SG_ 2147489795 NPath1State "Indicates the path 1 status";
CM_ SG_ 2147489795 NMultiplexer "Multiplexer ID";
CM_ SG_ 2147489795 BXcpError "Indicates a power switches command?s integrity fault";
CM_ SG_ 2147489795 NCellHwErrorFlags "Indicates HW errors triggered on CELL";
CM_ SG_ 2147489795 BIsoError "Indicates if an error occured on the isolated stage";
CM_ SG_ 2147489795 BSyncInputSignal "Indicates if a correct synchronization signal is detected on the input synchronization pin";
CM_ SG_ 2147489795 BSyncRequested "Indicates the synchronization command has been received";
CM_ SG_ 2147489795 BInternalTemperatureError "Indicates an overtemperature error on the internal temperature";
CM_ SG_ 2147489795 BConfigSettingsError "Indicates that the Config and/or Settings data is corrupted";
CM_ SG_ 2147489795 BAuxSupplyError "Indicates a fault on one of the auxiliary power supplies";
CM_ SG_ 2147489795 BCanTimeoutError "Indicates an error on the CAN bus";
CM_ SG_ 2147489795 BAuxIsoEnabled "Indicates that isolated auxiliary supplies are activated";
CM_ SG_ 2147489795 BSafetyDischargeEnabled "Indicates the safety discharge is activated";
CM_ SG_ 2147489795 BFaultSignal "Indicates the signal Fault status";
CM_ SG_ 2147489795 BEnableSignal "Indicates the external hardware ENABLE status";
CM_ SG_ 2147489795 BSafetyDischargeStatus "Indicates the safety discharge status";
CM_ SG_ 2147489795 BSyncStatus "Indicates the synchronization has been done successfully";
CM_ SG_ 2147489795 BReadConfigAndSettingsRequested "Indicates that the Read config and settings command has been received";
CM_ SG_ 2147489795 BSwResetModuleRequested "Indicates that the Software reset command has been received";
CM_ SG_ 2147489795 BSafetyDischargeRequested "Indicates that the safety discharge command has been received";
CM_ SG_ 2147489795 NModuleState "Indicates the overall module status";
CM_ BO_ 2147491715 "Overal Isolation stage Status & Diagnostic";
CM_ SG_ 2147491715 BStartupTimeout "Indicates the start up sequence timed out";
CM_ SG_ 2147491715 BOtpBuckAux "Indicates on over temperature error on the auxiliary buck";
CM_ SG_ 2147491715 BOtpSecError "Indicates an over temperature error on the secondary side of the isolation transformer (side C)";
CM_ SG_ 2147491715 BOtpPriError "Indicates an over temperature error on the primary side of the isolation transformer (side internal)";
CM_ SG_ 2147491715 BXcpBuckAuxError "Indicates an internal fault on the auxiliary buck stage";
CM_ SG_ 2147491715 BXcpDcdcError "Indicates an internal fault on the Dcdc stage";
CM_ SG_ 2147491715 BSecOcpError "Indicates an over current error on the secondary side of the isolation transformer (side C)";
CM_ SG_ 2147491715 BPriOcpError "Indicates an over current error on the primary side of the isolation transformer (side internal)";
CM_ SG_ 2147491715 BSecUvpError "Indicates an undervoltage on the secondary side of the isolation transfomer (side C)";
CM_ SG_ 2147491715 BSecOvpError "Indicates an overvoltage on the secondary side of the isolation transformer (side C)";
CM_ SG_ 2147491715 BPriUvpError "Indicates an undervoltage on the primary side of the isolation transformer (side internal)";
CM_ SG_ 2147491715 BPriOvpError "Indicates an overvoltage on the primary side of the isolation transformer (side internal)";
CM_ SG_ 2147491715 BBuckOcpError "Indicates an error on the current measured in the auxiliary buck";
CM_ SG_ 2147491715 BSuppAuxUvpError "Indicates an undervoltage on the output of the auxiliairy buck";
CM_ SG_ 2147491715 BSuppAuxOvpError "Indicates an overvoltage on the output voltage of the auxiliary buck";
CM_ SG_ 2147491715 BBuckAuxHwError "Indicates an overvoltage on the output voltage of the auxiliary buck";
CM_ SG_ 2147491715 BBuckVAuxDriverError "Indicates an hardware error on the auxiliary buck";
CM_ SG_ 2147491715 BAuxSupplyError "Indicates an error on the auxiliary supply";
CM_ SG_ 2147491715 BCanIntTimeoutError "Indicates an error on the internal CAN bus";
CM_ SG_ 2147491715 BCanTimeoutError "Indicates an error on the CAN bus";
CM_ SG_ 2147491715 BConfigSettingsError "Indicates the Config and or the Settings data are corrupted";
CM_ SG_ 2147491715 BPowerRequested "Indicates a start request has been received from the power board";
CM_ SG_ 2147491715 NAuxBuckState "Indicates the auxiliary buck state";
CM_ SG_ 2147491715 NChan2State "Indicates the isolation transformer channel 2 state";
CM_ SG_ 2147491715 NChan1State "Indicates the isolation transformer channel 1 state";
CM_ SG_ 2147491715 BAuxIsoEnabled "Indicates if the isolated auxiliary supplies are activated";
CM_ SG_ 2147491715 BFaultSignal "Indicates the signal Fault status";
CM_ SG_ 2147491715 BEnableSignal "Indicates the external hardware ENABLE status";
CM_ SG_ 2147491715 BSyncInputSignal "Indicates if a correct synchronization signal is detected on the input synchronization pin";
CM_ SG_ 2147491715 BSyncStatus "Indicates if the synchronization has been done successfully";
CM_ SG_ 2147491715 BSwResetModuleRequested "Indicates the software reset command has been received";
CM_ SG_ 2147491715 NState "Indicates the isolation stage state";
CM_ BO_ 2147491779 "Isolation stage global values";
CM_ SG_ 2147491779 TSecCh2D "Temperature of the secondary bridge D of the channel 2 of the dcdc isolated stage";
CM_ SG_ 2147491779 TSecCh1D "Temperature of the secondary bridge D of the channel 1 of the dcdc isolated stage";
CM_ SG_ 2147491779 TPriCh2D "Temperature of the primary bridge D of the channel 2 of the dcdc isolated stage";
CM_ SG_ 2147491779 TPriCh1D "Temperature of the primary bridge D of the channel 1 of the dcdc isolated stage";
CM_ SG_ 2147491779 NReleaseMode "Reserved";
CM_ SG_ 2147491779 NApplicationId "Module Serial Number";
CM_ SG_ 2147491779 NSettingsVersion "Version number of the settings";
CM_ SG_ 2147491779 NConfigCrc "Crc of the configuration";
CM_ SG_ 2147491779 NXcpDcdcErrorFlags "Details on internal fault for the dcdc stage";
CM_ SG_ 2147491779 NOtpDcdcErrorFlags "Details on over temperature protection";
CM_ SG_ 2147491779 TSecCh2C "Temperature of the secondary bridge C of the channel 2 of the dcdc isolated stage";
CM_ SG_ 2147491779 TSecCh1C "Temperature of the secondary bridge C of the channel 1 of the dcdc isolated stage";
CM_ SG_ 2147491779 TPriCh2C "Temperature of the primary bridge C of the channel 2 of the dcdc isolated stage";
CM_ SG_ 2147491779 TPriCh1C "Temperature of the primary bridge C of the channel 1 of the dcdc isolated stage";
CM_ SG_ 2147491779 V1v65Aux "Auxiliary voltage 1V65 value";
CM_ SG_ 2147491779 VBuckAuxDriver "Auxiliary voltage supply for the auxiliary buck drivers";
CM_ SG_ 2147491779 TSecCh2B "Temperature of the secondary bridge B of the channel 2 of the dcdc isolated stage";
CM_ SG_ 2147491779 TSecCh1B "Temperature of the secondary bridge B of the channel 1 of the dcdc isolated stage";
CM_ SG_ 2147491779 TPriCh2B "Temperature of the primary bridge B of the channel 2 of the dcdc isolated stage";
CM_ SG_ 2147491779 TPriCh1B "Temperature of the primary bridge B of the channel 1 of the dcdc isolated stage";
CM_ SG_ 2147491779 V3v3Aux "Auxiliary voltage 3v3 value";
CM_ SG_ 2147491779 NMissedSyncPulseCount "reserved";
CM_ SG_ 2147491779 NChecksum "Checksum of the application program";
CM_ SG_ 2147491779 NSerial "Module serial number";
CM_ SG_ 2147491779 NSettingsCrc "Crc of the settings";
CM_ SG_ 2147491779 NBootloaderId "Version number of the bootloader program";
CM_ SG_ 2147491779 NConfigVersion "Version number of the configuration";
CM_ SG_ 2147491779 NOcpDcdcErrorFlags "Detail on over current protection";
CM_ SG_ 2147491779 TBuckAux "Temperature of the auxiliary buck";
CM_ SG_ 2147491779 TSecCh2A "Temperature of the secondary bridge A of the channel 2 of the dcdc isolated stage";
CM_ SG_ 2147491779 TSecCh1A "Temperature of the secondary bridge A of the channel 1 of the dcdc isolated stage";
CM_ SG_ 2147491779 TPriCh2A "Temperature of the primary bridge A of the channel 2 of the dcdc isolated stage";
CM_ SG_ 2147491779 TPriCh1A "Temperature of the primary bridge A of the channel 1 of the dcdc isolated stage";
CM_ SG_ 2147491779 VHvAux "Main auxiliary voltage";
CM_ SG_ 2147491779 NMultiplexer "Multiplexer ID";
CM_ SG_ 2147491779 VSuppAux "Auxiliary voltage supply for the dcdc isolation stage";
CM_ SG_ 2147491779 IBuckAux "Auxiliary buck current value";
CM_ BO_ 2147490691 "Values of port Internal";
CM_ SG_ 2147490691 IPortInternalAverage "Average value of the internal port current";
CM_ SG_ 2147490691 VPortInternalAverage "Average value of the internal port voltage";
CM_ SG_ 2147490691 VPortInternalMax "Maximum value of the internal port voltage measured since the last message sent";
CM_ SG_ 2147490691 VPortInternalMin "Minimum value of the internal port voltage measured since the last message sent";
CM_ BO_ 2147490755 "Values of port C1";
CM_ SG_ 2147490755 IPortC1Average "Average value of the port C1 current";
CM_ SG_ 2147490755 VPortC1Average "Average value of the port C1 voltage";
CM_ SG_ 2147490755 VPortC1Max "Maximum value of the  port C1 voltage seen since the last message sent";
CM_ SG_ 2147490755 VPortC1Min "Minimum value of the port C1 voltage seen since the last message sent";
BA_DEF_ BO_  "CanDootDecode" ENUM  "No","Yes";
BA_DEF_ BO_  "CanDootDecodeBus" INT 0 6;
BA_DEF_ BO_  "CanDootPaused" ENUM  "No","Yes";
BA_DEF_ BO_  "CanDootSimulateCycleTime" INT 0 50000;
BA_DEF_ BO_  "CG_RX_TX" ENUM  "RX","TX","NONE";
BA_DEF_ SG_  "CanDootHidden" ENUM  "No","Yes";
BA_DEF_ SG_  "CanDootBroadcast" ENUM  "No","Yes";
BA_DEF_ SG_  "CG_VarType" ENUM  "bool","uint8_t","int8_t","uint16_t","int16_t","uint32_t","int32_t","uin64_t","int64_t","float","double";
BA_DEF_DEF_  "CanDootDecode" "Yes";
BA_DEF_DEF_  "CanDootDecodeBus" 1;
BA_DEF_DEF_  "CanDootPaused" "Yes";
BA_DEF_DEF_  "CanDootSimulateCycleTime" 100;
BA_DEF_DEF_  "CG_RX_TX" "RX";
BA_DEF_DEF_  "CanDootHidden" "No";
BA_DEF_DEF_  "CanDootBroadcast" "No";
BA_DEF_DEF_  "CG_VarType" "uint8_t";
BA_ "CanDootPaused" BO_ 2147487750 0;
BA_ "CanDootPaused" BO_ 2147487753 0;
BA_ "CanDootPaused" BO_ 2147489417 0;
BA_ "CanDootPaused" BO_ 2147489353 0;
BA_ "CanDootPaused" BO_ 2147488777 0;
BA_ "CanDootPaused" BO_ 2147487881 0;
BA_ "CanDootPaused" BO_ 2147487945 0;
BA_ "CanDootPaused" BO_ 2147489416 0;
BA_ "CanDootPaused" BO_ 2147489352 0;
BA_ "CanDootPaused" BO_ 2147488776 0;
BA_ "CanDootPaused" BO_ 2147487880 0;
BA_ "CanDootPaused" BO_ 2147487944 0;
BA_ "CanDootPaused" BO_ 2147487752 0;
BA_ "CanDootPaused" BO_ 2147491393 0;
BA_ "CanDootPaused" BO_ 2147491457 0;
BA_ "CanDootPaused" BO_ 2147490817 0;
BA_ "CanDootPaused" BO_ 2147490175 0;
BA_ "CanDootPaused" BO_ 2147490111 0;
BA_ "CanDootPaused" BO_ 2147490047 0;
BA_ "CanDootPaused" BO_ 2147489921 0;
BA_ "CanDootPaused" BO_ 2147489793 0;
BA_ "CanDootPaused" BO_ 2147489983 0;
BA_ "CanDootPaused" BO_ 2147491713 0;
BA_ "CanDootPaused" BO_ 2147490689 0;
BA_ "CanDootPaused" BO_ 2147490753 0;
BA_ "CanDootPaused" BO_ 2147491394 0;
BA_ "CanDootPaused" BO_ 2147491458 0;
BA_ "CanDootPaused" BO_ 2147490818 0;
BA_ "CanDootPaused" BO_ 2147489922 0;
BA_ "CanDootPaused" BO_ 2147489794 0;
BA_ "CanDootPaused" BO_ 2147491714 0;
BA_ "CanDootPaused" BO_ 2147490690 0;
BA_ "CanDootPaused" BO_ 2147490754 0;
BA_ "CanDootDecode" BO_ 2147491395 0;
BA_ "CanDootPaused" BO_ 2147491395 0;
BA_ "CanDootDecode" BO_ 2147491459 0;
BA_ "CanDootPaused" BO_ 2147491459 0;
BA_ "CanDootDecode" BO_ 2147490819 0;
BA_ "CanDootPaused" BO_ 2147490819 0;
BA_ "CanDootDecode" BO_ 2147489923 0;
BA_ "CanDootPaused" BO_ 2147489923 0;
BA_ "CanDootDecode" BO_ 2147491523 0;
BA_ "CanDootDecode" BO_ 2147489859 0;
BA_ "CanDootDecode" BO_ 2147489795 0;
BA_ "CanDootPaused" BO_ 2147489795 0;
BA_ "CanDootDecode" BO_ 2147491715 0;
BA_ "CanDootPaused" BO_ 2147491715 0;
BA_ "CanDootDecode" BO_ 2147491779 0;
BA_ "CanDootDecode" BO_ 2147490691 0;
BA_ "CanDootPaused" BO_ 2147490691 0;
BA_ "CanDootDecode" BO_ 2147490755 0;
BA_ "CanDootPaused" BO_ 2147490755 0;
BA_ "CanDootHidden" SG_ 2147487814 NConfigCrc 1;
BA_ "CanDootHidden" SG_ 2147487814 NSettingsCrc 1;
BA_ "CanDootBroadcast" SG_ 2147487814 TCell1N2 1;
BA_ "CanDootHidden" SG_ 2147487814 NMultiplexer 1;
BA_ "CanDootHidden" SG_ 2147487750 NMultiplexer 1;
BA_ "CanDootHidden" SG_ 2147487753 NMultiplexer 1;
BA_ "CanDootHidden" SG_ 2147489417 NMultiplexer 1;
BA_ "CanDootHidden" SG_ 2147489353 NMultiplexer 1;
BA_ "CanDootHidden" SG_ 2147487881 NMultiplexer 1;
BA_ "CanDootHidden" SG_ 2147487945 NMultiplexer 1;
BA_ "CanDootHidden" SG_ 2147487817 NConfigCrc 1;
BA_ "CanDootHidden" SG_ 2147487817 NSettingsCrc 1;
BA_ "CanDootHidden" SG_ 2147487817 NMultiplexer 1;
BA_ "CanDootHidden" SG_ 2147489416 NMultiplexer 1;
BA_ "CanDootHidden" SG_ 2147489352 NMultiplexer 1;
BA_ "CanDootHidden" SG_ 2147487880 NMultiplexer 1;
BA_ "CanDootHidden" SG_ 2147487944 NMultiplexer 1;
BA_ "CanDootHidden" SG_ 2147487816 NConfigCrc 1;
BA_ "CanDootHidden" SG_ 2147487816 NSettingsCrc 1;
BA_ "CanDootHidden" SG_ 2147487816 NMultiplexer 1;
BA_ "CanDootHidden" SG_ 2147487752 NMultiplexer 1;
BA_ "CanDootHidden" SG_ 2147491393 NMultiplexer 1;
BA_ "CanDootHidden" SG_ 2147491457 NMultiplexer 1;
BA_ "CanDootHidden" SG_ 2147490111 NModuleSelect 1;
BA_ "CanDootHidden" SG_ 2147490047 NModuleSelect 1;
BA_ "CanDootHidden" SG_ 2147490047 BL5_NMultiplexer 1;
BA_ "CanDootHidden" SG_ 2147490047 BL6_NMultiplexer 1;
BA_ "CanDootHidden" SG_ 2147490047 BL7_NMultiplexer 1;
BA_ "CanDootHidden" SG_ 2147489921 NMultiplexer 1;
BA_ "CanDootHidden" SG_ 2147489857 NSettingsCrc 1;
BA_ "CanDootHidden" SG_ 2147489857 NConfigCrc 1;
BA_ "CanDootHidden" SG_ 2147489857 NMultiplexer 1;
BA_ "CanDootHidden" SG_ 2147489793 NMultiplexer 1;
BA_ "CanDootHidden" SG_ 2147489983 NModuleSelect 1;
BA_ "CanDootHidden" SG_ 2147489983 BL5_NMultiplexer 1;
BA_ "CanDootHidden" SG_ 2147489983 BL6_NMultiplexer 1;
BA_ "CanDootHidden" SG_ 2147489983 BL7_NMultiplexer 1;
BA_ "CanDootHidden" SG_ 2147489855 NModuleSelect 1;
BA_ "CanDootHidden" SG_ 2147491777 NConfigCrc 1;
BA_ "CanDootHidden" SG_ 2147491777 NSettingsCrc 1;
BA_ "CanDootHidden" SG_ 2147491777 NMultiplexer 1;
BA_ "CanDootHidden" SG_ 2147491394 NMultiplexer 1;
BA_ "CanDootHidden" SG_ 2147491458 NMultiplexer 1;
BA_ "CanDootHidden" SG_ 2147489922 NMultiplexer 1;
BA_ "CanDootHidden" SG_ 2147489858 NSettingsCrc 1;
BA_ "CanDootHidden" SG_ 2147489858 NConfigCrc 1;
BA_ "CanDootHidden" SG_ 2147489858 NMultiplexer 1;
BA_ "CanDootHidden" SG_ 2147489794 NMultiplexer 1;
BA_ "CanDootHidden" SG_ 2147491778 NConfigCrc 1;
BA_ "CanDootHidden" SG_ 2147491778 NSettingsCrc 1;
BA_ "CanDootHidden" SG_ 2147491778 NMultiplexer 1;
BA_ "CanDootHidden" SG_ 2147491395 NMultiplexer 1;
BA_ "CanDootHidden" SG_ 2147491459 NMultiplexer 1;
BA_ "CanDootHidden" SG_ 2147489923 NMultiplexer 1;
BA_ "CanDootHidden" SG_ 2147489859 NSettingsCrc 1;
BA_ "CanDootHidden" SG_ 2147489859 NConfigCrc 1;
BA_ "CanDootHidden" SG_ 2147489859 NMultiplexer 1;
BA_ "CanDootHidden" SG_ 2147489795 NMultiplexer 1;
BA_ "CanDootHidden" SG_ 2147491779 NConfigCrc 1;
BA_ "CanDootHidden" SG_ 2147491779 NSettingsCrc 1;
BA_ "CanDootHidden" SG_ 2147491779 NMultiplexer 1;
SIG_GROUP_ 2147490111 AcknowledgeErrors 1 :;
SIG_GROUP_ 2147490111 DCHVI_AcknowledgeErrors 1 : BAckErrorsPath1Request BAckErrorsModuleRequest;
SIG_GROUP_ 2147490047 Setpoints2Write 1 :;
SIG_GROUP_ 2147490047 DCHVI_Setpoints2Write 1 : BL5_PPath1LimitHi BL5_PPath1LimitLo;
SIG_GROUP_ 2147489983 DcSetpoints1Write 1 :;
SIG_GROUP_ 2147489983 DCHVI_DcSetpoints1Write 1 : BL5_VPath1Setpoint BL5_IPath1LimitHi BL5_IPath1LimitLo BL5_NPath1VoltageSideSelect BL5_NPath1CurrentSideSelect;
SG_MUL_VAL_ 2147490047 BL5_PPath1LimitLo BL5_NMultiplexer 1-1;
SG_MUL_VAL_ 2147490047 BL6_PPath1LimitLo BL6_NMultiplexer 1-1;
SG_MUL_VAL_ 2147490047 BL7_PPath1LimitLo BL7_NMultiplexer 1-1;
SG_MUL_VAL_ 2147490047 BL5_PPath1LimitHi BL5_NMultiplexer 1-1;
SG_MUL_VAL_ 2147490047 BL6_PPath1LimitHi BL6_NMultiplexer 1-1;
SG_MUL_VAL_ 2147490047 BL7_PPath1LimitHi BL7_NMultiplexer 1-1;
SG_MUL_VAL_ 2147490047 BL5_NMultiplexer NModuleSelect 1-1;
SG_MUL_VAL_ 2147490047 BL6_NMultiplexer NModuleSelect 2-2;
SG_MUL_VAL_ 2147490047 BL7_NMultiplexer NModuleSelect 3-3;
SG_MUL_VAL_ 2147489983 BL5_NPath1CurrentSideSelect BL5_NMultiplexer 1-1;
SG_MUL_VAL_ 2147489983 BL6_NPath1CurrentSideSelect BL6_NMultiplexer 1-1;
SG_MUL_VAL_ 2147489983 BL7_NPath1CurrentSideSelect BL7_NMultiplexer 1-1;
SG_MUL_VAL_ 2147489983 BL5_NPath1VoltageSideSelect BL5_NMultiplexer 1-1;
SG_MUL_VAL_ 2147489983 BL6_NPath1VoltageSideSelect BL6_NMultiplexer 1-1;
SG_MUL_VAL_ 2147489983 BL7_NPath1VoltageSideSelect BL7_NMultiplexer 1-1;
SG_MUL_VAL_ 2147489983 BL5_IPath1LimitLo BL5_NMultiplexer 1-1;
SG_MUL_VAL_ 2147489983 BL6_IPath1LimitLo BL6_NMultiplexer 1-1;
SG_MUL_VAL_ 2147489983 BL7_IPath1LimitLo BL7_NMultiplexer 1-1;
SG_MUL_VAL_ 2147489983 BL5_IPath1LimitHi BL5_NMultiplexer 1-1;
SG_MUL_VAL_ 2147489983 BL6_IPath1LimitHi BL6_NMultiplexer 1-1;
SG_MUL_VAL_ 2147489983 BL7_IPath1LimitHi BL7_NMultiplexer 1-1;
SG_MUL_VAL_ 2147489983 BL5_VPath1Setpoint BL5_NMultiplexer 1-1;
SG_MUL_VAL_ 2147489983 BL6_VPath1Setpoint BL6_NMultiplexer 1-1;
SG_MUL_VAL_ 2147489983 BL7_VPath1Setpoint BL7_NMultiplexer 1-1;
SG_MUL_VAL_ 2147489983 BL5_NMultiplexer NModuleSelect 1-1;
SG_MUL_VAL_ 2147489983 BL6_NMultiplexer NModuleSelect 2-2;
SG_MUL_VAL_ 2147489983 BL7_NMultiplexer NModuleSelect 3-3;
